VERSION "AgOpen Rate CAN ECU DBC with S0-S3 banks, 16 nodes, and service CAN"

NS_ :

BS_:

BU_: MASTER TOOL NODE1 NODE2 NODE3 NODE4 NODE5 NODE6 NODE7 NODE8 NODE9 NODE10 NODE11 NODE12 NODE13 NODE14 NODE15 NODE16

BO_ 972 S2_NODE_DIAG_12: 8 NODE12
 SG_ bus_voltage : 0|16@1+ (0.1,0) [0|6553.5] "V"  MASTER,NODE1,NODE2,NODE3,NODE4,NODE5,NODE6,NODE7,NODE8,NODE9,NODE10,NODE11,NODE12,NODE13,NODE14,NODE15,NODE16,TOOL
 SG_ motor_current : 16|16@1- (0.1,0) [-3276.8|3276.7] "A"  MASTER,NODE1,NODE2,NODE3,NODE4,NODE5,NODE6,NODE7,NODE8,NODE9,NODE10,NODE11,NODE12,NODE13,NODE14,NODE15,NODE16,TOOL
 SG_ controller_temp : 32|8@1- (1,0) [-128|127] "degC"  MASTER,NODE1,NODE2,NODE3,NODE4,NODE5,NODE6,NODE7,NODE8,NODE9,NODE10,NODE11,NODE12,NODE13,NODE14,NODE15,NODE16,TOOL
 SG_ motor_temp : 40|8@1- (1,0) [-128|127] "degC"  MASTER,NODE1,NODE2,NODE3,NODE4,NODE5,NODE6,NODE7,NODE8,NODE9,NODE10,NODE11,NODE12,NODE13,NODE14,NODE15,NODE16,TOOL
 SG_ fault_flags : 48|8@1+ (1,0) [0|255] "bitfield"  MASTER,NODE1,NODE2,NODE3,NODE4,NODE5,NODE6,NODE7,NODE8,NODE9,NODE10,NODE11,NODE12,NODE13,NODE14,NODE15,NODE16,TOOL
 SG_ warning_flags : 56|8@1+ (1,0) [0|255] "bitfield"  MASTER,NODE1,NODE2,NODE3,NODE4,NODE5,NODE6,NODE7,NODE8,NODE9,NODE10,NODE11,NODE12,NODE13,NODE14,NODE15,NODE16,TOOL

BO_ 797 S2_NODE_CMD_13: 8 MASTER
 SG_ node_command : 0|8@1+ (1,0) [0|255] ""  MASTER,NODE1,NODE2,NODE3,NODE4,NODE5,NODE6,NODE7,NODE8,NODE9,NODE10,NODE11,NODE12,NODE13,NODE14,NODE15,NODE16,TOOL
 SG_ node_flags : 8|8@1+ (1,0) [0|255] "bitfield"  MASTER,NODE1,NODE2,NODE3,NODE4,NODE5,NODE6,NODE7,NODE8,NODE9,NODE10,NODE11,NODE12,NODE13,NODE14,NODE15,NODE16,TOOL
 SG_ trim_rpm : 16|16@1- (0.1,0) [-3276.8|3276.7] "rpm"  MASTER,NODE1,NODE2,NODE3,NODE4,NODE5,NODE6,NODE7,NODE8,NODE9,NODE10,NODE11,NODE12,NODE13,NODE14,NODE15,NODE16,TOOL
 SG_ section_mask : 32|16@1+ (1,0) [0|65535] "bitmask"  MASTER,NODE1,NODE2,NODE3,NODE4,NODE5,NODE6,NODE7,NODE8,NODE9,NODE10,NODE11,NODE12,NODE13,NODE14,NODE15,NODE16,TOOL
 SG_ seq : 48|8@1+ (1,0) [0|255] ""  MASTER,NODE1,NODE2,NODE3,NODE4,NODE5,NODE6,NODE7,NODE8,NODE9,NODE10,NODE11,NODE12,NODE13,NODE14,NODE15,NODE16,TOOL
 SG_ reserved : 56|8@1+ (1,0) [0|255] ""  MASTER,NODE1,NODE2,NODE3,NODE4,NODE5,NODE6,NODE7,NODE8,NODE9,NODE10,NODE11,NODE12,NODE13,NODE14,NODE15,NODE16,TOOL

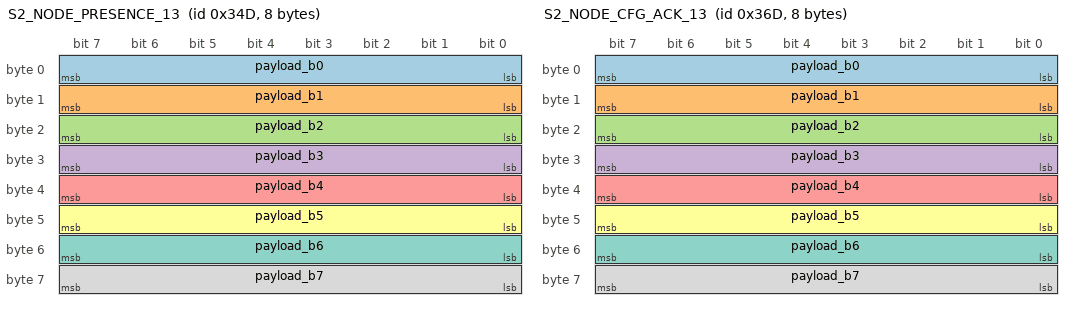
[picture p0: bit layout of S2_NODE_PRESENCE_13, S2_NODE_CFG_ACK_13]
BO_ 845 S2_NODE_PRESENCE_13: 8 NODE13
 SG_ payload_b0 : 0|8@1+ (1,0) [0|255] "raw"  MASTER,NODE1,NODE2,NODE3,NODE4,NODE5,NODE6,NODE7,NODE8,NODE9,NODE10,NODE11,NODE12,NODE13,NODE14,NODE15,NODE16,TOOL
 SG_ payload_b1 : 8|8@1+ (1,0) [0|255] "raw"  MASTER,NODE1,NODE2,NODE3,NODE4,NODE5,NODE6,NODE7,NODE8,NODE9,NODE10,NODE11,NODE12,NODE13,NODE14,NODE15,NODE16,TOOL
 SG_ payload_b2 : 16|8@1+ (1,0) [0|255] "raw"  MASTER,NODE1,NODE2,NODE3,NODE4,NODE5,NODE6,NODE7,NODE8,NODE9,NODE10,NODE11,NODE12,NODE13,NODE14,NODE15,NODE16,TOOL
 SG_ payload_b3 : 24|8@1+ (1,0) [0|255] "raw"  MASTER,NODE1,NODE2,NODE3,NODE4,NODE5,NODE6,NODE7,NODE8,NODE9,NODE10,NODE11,NODE12,NODE13,NODE14,NODE15,NODE16,TOOL
 SG_ payload_b4 : 32|8@1+ (1,0) [0|255] "raw"  MASTER,NODE1,NODE2,NODE3,NODE4,NODE5,NODE6,NODE7,NODE8,NODE9,NODE10,NODE11,NODE12,NODE13,NODE14,NODE15,NODE16,TOOL
 SG_ payload_b5 : 40|8@1+ (1,0) [0|255] "raw"  MASTER,NODE1,NODE2,NODE3,NODE4,NODE5,NODE6,NODE7,NODE8,NODE9,NODE10,NODE11,NODE12,NODE13,NODE14,NODE15,NODE16,TOOL
 SG_ payload_b6 : 48|8@1+ (1,0) [0|255] "raw"  MASTER,NODE1,NODE2,NODE3,NODE4,NODE5,NODE6,NODE7,NODE8,NODE9,NODE10,NODE11,NODE12,NODE13,NODE14,NODE15,NODE16,TOOL
 SG_ payload_b7 : 56|8@1+ (1,0) [0|255] "raw"  MASTER,NODE1,NODE2,NODE3,NODE4,NODE5,NODE6,NODE7,NODE8,NODE9,NODE10,NODE11,NODE12,NODE13,NODE14,NODE15,NODE16,TOOL

BO_ 877 S2_NODE_CFG_ACK_13: 8 NODE13
 SG_ payload_b0 : 0|8@1+ (1,0) [0|255] "raw"  MASTER,NODE1,NODE2,NODE3,NODE4,NODE5,NODE6,NODE7,NODE8,NODE9,NODE10,NODE11,NODE12,NODE13,NODE14,NODE15,NODE16,TOOL
 SG_ payload_b1 : 8|8@1+ (1,0) [0|255] "raw"  MASTER,NODE1,NODE2,NODE3,NODE4,NODE5,NODE6,NODE7,NODE8,NODE9,NODE10,NODE11,NODE12,NODE13,NODE14,NODE15,NODE16,TOOL
 SG_ payload_b2 : 16|8@1+ (1,0) [0|255] "raw"  MASTER,NODE1,NODE2,NODE3,NODE4,NODE5,NODE6,NODE7,NODE8,NODE9,NODE10,NODE11,NODE12,NODE13,NODE14,NODE15,NODE16,TOOL
 SG_ payload_b3 : 24|8@1+ (1,0) [0|255] "raw"  MASTER,NODE1,NODE2,NODE3,NODE4,NODE5,NODE6,NODE7,NODE8,NODE9,NODE10,NODE11,NODE12,NODE13,NODE14,NODE15,NODE16,TOOL
 SG_ payload_b4 : 32|8@1+ (1,0) [0|255] "raw"  MASTER,NODE1,NODE2,NODE3,NODE4,NODE5,NODE6,NODE7,NODE8,NODE9,NODE10,NODE11,NODE12,NODE13,NODE14,NODE15,NODE16,TOOL
 SG_ payload_b5 : 40|8@1+ (1,0) [0|255] "raw"  MASTER,NODE1,NODE2,NODE3,NODE4,NODE5,NODE6,NODE7,NODE8,NODE9,NODE10,NODE11,NODE12,NODE13,NODE14,NODE15,NODE16,TOOL
 SG_ payload_b6 : 48|8@1+ (1,0) [0|255] "raw"  MASTER,NODE1,NODE2,NODE3,NODE4,NODE5,NODE6,NODE7,NODE8,NODE9,NODE10,NODE11,NODE12,NODE13,NODE14,NODE15,NODE16,TOOL
 SG_ payload_b7 : 56|8@1+ (1,0) [0|255] "raw"  MASTER,NODE1,NODE2,NODE3,NODE4,NODE5,NODE6,NODE7,NODE8,NODE9,NODE10,NODE11,NODE12,NODE13,NODE14,NODE15,NODE16,TOOL

BO_ 909 S2_NODE_STATUS_FAST_13: 8 NODE13
 SG_ status_flags : 0|8@1+ (1,0) [0|255] "bitfield"  MASTER,NODE1,NODE2,NODE3,NODE4,NODE5,NODE6,NODE7,NODE8,NODE9,NODE10,NODE11,NODE12,NODE13,NODE14,NODE15,NODE16,TOOL
 SG_ error_code : 8|8@1+ (1,0) [0|255] ""  MASTER,NODE1,NODE2,NODE3,NODE4,NODE5,NODE6,NODE7,NODE8,NODE9,NODE10,NODE11,NODE12,NODE13,NODE14,NODE15,NODE16,TOOL
 SG_ actual_rpm : 16|16@1+ (1,0) [0|10000] "rpm"  MASTER,NODE1,NODE2,NODE3,NODE4,NODE5,NODE6,NODE7,NODE8,NODE9,NODE10,NODE11,NODE12,NODE13,NODE14,NODE15,NODE16,TOOL
 SG_ actual_pos : 32|16@1+ (1.52587890625e-05,0) [0|0.9999847412109375] "rev"  MASTER,NODE1,NODE2,NODE3,NODE4,NODE5,NODE6,NODE7,NODE8,NODE9,NODE10,NODE11,NODE12,NODE13,NODE14,NODE15,NODE16,TOOL
 SG_ alive_counter : 48|8@1+ (1,0) [0|255] ""  MASTER,NODE1,NODE2,NODE3,NODE4,NODE5,NODE6,NODE7,NODE8,NODE9,NODE10,NODE11,NODE12,NODE13,NODE14,NODE15,NODE16,TOOL
 SG_ sync_error : 56|8@1- (0.00390625,0) [-0.5|0.49609375] "rev"  MASTER,NODE1,NODE2,NODE3,NODE4,NODE5,NODE6,NODE7,NODE8,NODE9,NODE10,NODE11,NODE12,NODE13,NODE14,NODE15,NODE16,TOOL

BO_ 973 S2_NODE_DIAG_13: 8 NODE13
 SG_ bus_voltage : 0|16@1+ (0.1,0) [0|6553.5] "V"  MASTER,NODE1,NODE2,NODE3,NODE4,NODE5,NODE6,NODE7,NODE8,NODE9,NODE10,NODE11,NODE12,NODE13,NODE14,NODE15,NODE16,TOOL
 SG_ motor_current : 16|16@1- (0.1,0) [-3276.8|3276.7] "A"  MASTER,NODE1,NODE2,NODE3,NODE4,NODE5,NODE6,NODE7,NODE8,NODE9,NODE10,NODE11,NODE12,NODE13,NODE14,NODE15,NODE16,TOOL
 SG_ controller_temp : 32|8@1- (1,0) [-128|127] "degC"  MASTER,NODE1,NODE2,NODE3,NODE4,NODE5,NODE6,NODE7,NODE8,NODE9,NODE10,NODE11,NODE12,NODE13,NODE14,NODE15,NODE16,TOOL
 SG_ motor_temp : 40|8@1- (1,0) [-128|127] "degC"  MASTER,NODE1,NODE2,NODE3,NODE4,NODE5,NODE6,NODE7,NODE8,NODE9,NODE10,NODE11,NODE12,NODE13,NODE14,NODE15,NODE16,TOOL
 SG_ fault_flags : 48|8@1+ (1,0) [0|255] "bitfield"  MASTER,NODE1,NODE2,NODE3,NODE4,NODE5,NODE6,NODE7,NODE8,NODE9,NODE10,NODE11,NODE12,NODE13,NODE14,NODE15,NODE16,TOOL
 SG_ warning_flags : 56|8@1+ (1,0) [0|255] "bitfield"  MASTER,NODE1,NODE2,NODE3,NODE4,NODE5,NODE6,NODE7,NODE8,NODE9,NODE10,NODE11,NODE12,NODE13,NODE14,NODE15,NODE16,TOOL

BO_ 798 S2_NODE_CMD_14: 8 MASTER
 SG_ node_command : 0|8@1+ (1,0) [0|255] ""  MASTER,NODE1,NODE2,NODE3,NODE4,NODE5,NODE6,NODE7,NODE8,NODE9,NODE10,NODE11,NODE12,NODE13,NODE14,NODE15,NODE16,TOOL
 SG_ node_flags : 8|8@1+ (1,0) [0|255] "bitfield"  MASTER,NODE1,NODE2,NODE3,NODE4,NODE5,NODE6,NODE7,NODE8,NODE9,NODE10,NODE11,NODE12,NODE13,NODE14,NODE15,NODE16,TOOL
 SG_ trim_rpm : 16|16@1- (0.1,0) [-3276.8|3276.7] "rpm"  MASTER,NODE1,NODE2,NODE3,NODE4,NODE5,NODE6,NODE7,NODE8,NODE9,NODE10,NODE11,NODE12,NODE13,NODE14,NODE15,NODE16,TOOL
 SG_ section_mask : 32|16@1+ (1,0) [0|65535] "bitmask"  MASTER,NODE1,NODE2,NODE3,NODE4,NODE5,NODE6,NODE7,NODE8,NODE9,NODE10,NODE11,NODE12,NODE13,NODE14,NODE15,NODE16,TOOL
 SG_ seq : 48|8@1+ (1,0) [0|255] ""  MASTER,NODE1,NODE2,NODE3,NODE4,NODE5,NODE6,NODE7,NODE8,NODE9,NODE10,NODE11,NODE12,NODE13,NODE14,NODE15,NODE16,TOOL
 SG_ reserved : 56|8@1+ (1,0) [0|255] ""  MASTER,NODE1,NODE2,NODE3,NODE4,NODE5,NODE6,NODE7,NODE8,NODE9,NODE10,NODE11,NODE12,NODE13,NODE14,NODE15,NODE16,TOOL

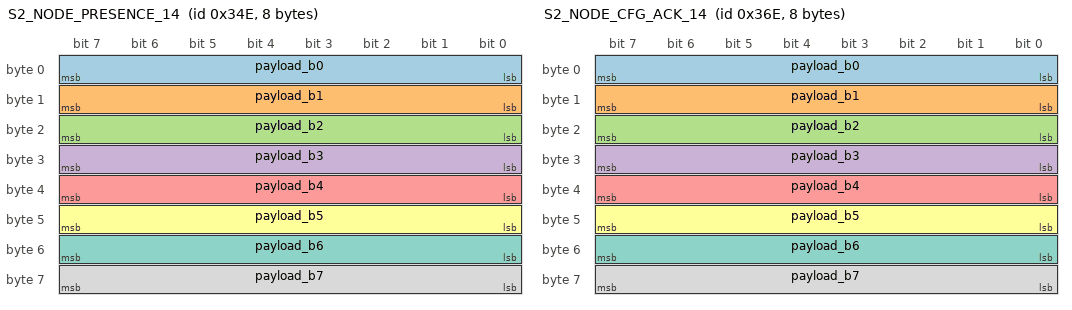
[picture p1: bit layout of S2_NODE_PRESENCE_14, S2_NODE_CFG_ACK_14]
BO_ 846 S2_NODE_PRESENCE_14: 8 NODE14
 SG_ payload_b0 : 0|8@1+ (1,0) [0|255] "raw"  MASTER,NODE1,NODE2,NODE3,NODE4,NODE5,NODE6,NODE7,NODE8,NODE9,NODE10,NODE11,NODE12,NODE13,NODE14,NODE15,NODE16,TOOL
 SG_ payload_b1 : 8|8@1+ (1,0) [0|255] "raw"  MASTER,NODE1,NODE2,NODE3,NODE4,NODE5,NODE6,NODE7,NODE8,NODE9,NODE10,NODE11,NODE12,NODE13,NODE14,NODE15,NODE16,TOOL
 SG_ payload_b2 : 16|8@1+ (1,0) [0|255] "raw"  MASTER,NODE1,NODE2,NODE3,NODE4,NODE5,NODE6,NODE7,NODE8,NODE9,NODE10,NODE11,NODE12,NODE13,NODE14,NODE15,NODE16,TOOL
 SG_ payload_b3 : 24|8@1+ (1,0) [0|255] "raw"  MASTER,NODE1,NODE2,NODE3,NODE4,NODE5,NODE6,NODE7,NODE8,NODE9,NODE10,NODE11,NODE12,NODE13,NODE14,NODE15,NODE16,TOOL
 SG_ payload_b4 : 32|8@1+ (1,0) [0|255] "raw"  MASTER,NODE1,NODE2,NODE3,NODE4,NODE5,NODE6,NODE7,NODE8,NODE9,NODE10,NODE11,NODE12,NODE13,NODE14,NODE15,NODE16,TOOL
 SG_ payload_b5 : 40|8@1+ (1,0) [0|255] "raw"  MASTER,NODE1,NODE2,NODE3,NODE4,NODE5,NODE6,NODE7,NODE8,NODE9,NODE10,NODE11,NODE12,NODE13,NODE14,NODE15,NODE16,TOOL
 SG_ payload_b6 : 48|8@1+ (1,0) [0|255] "raw"  MASTER,NODE1,NODE2,NODE3,NODE4,NODE5,NODE6,NODE7,NODE8,NODE9,NODE10,NODE11,NODE12,NODE13,NODE14,NODE15,NODE16,TOOL
 SG_ payload_b7 : 56|8@1+ (1,0) [0|255] "raw"  MASTER,NODE1,NODE2,NODE3,NODE4,NODE5,NODE6,NODE7,NODE8,NODE9,NODE10,NODE11,NODE12,NODE13,NODE14,NODE15,NODE16,TOOL

BO_ 878 S2_NODE_CFG_ACK_14: 8 NODE14
 SG_ payload_b0 : 0|8@1+ (1,0) [0|255] "raw"  MASTER,NODE1,NODE2,NODE3,NODE4,NODE5,NODE6,NODE7,NODE8,NODE9,NODE10,NODE11,NODE12,NODE13,NODE14,NODE15,NODE16,TOOL
 SG_ payload_b1 : 8|8@1+ (1,0) [0|255] "raw"  MASTER,NODE1,NODE2,NODE3,NODE4,NODE5,NODE6,NODE7,NODE8,NODE9,NODE10,NODE11,NODE12,NODE13,NODE14,NODE15,NODE16,TOOL
 SG_ payload_b2 : 16|8@1+ (1,0) [0|255] "raw"  MASTER,NODE1,NODE2,NODE3,NODE4,NODE5,NODE6,NODE7,NODE8,NODE9,NODE10,NODE11,NODE12,NODE13,NODE14,NODE15,NODE16,TOOL
 SG_ payload_b3 : 24|8@1+ (1,0) [0|255] "raw"  MASTER,NODE1,NODE2,NODE3,NODE4,NODE5,NODE6,NODE7,NODE8,NODE9,NODE10,NODE11,NODE12,NODE13,NODE14,NODE15,NODE16,TOOL
 SG_ payload_b4 : 32|8@1+ (1,0) [0|255] "raw"  MASTER,NODE1,NODE2,NODE3,NODE4,NODE5,NODE6,NODE7,NODE8,NODE9,NODE10,NODE11,NODE12,NODE13,NODE14,NODE15,NODE16,TOOL
 SG_ payload_b5 : 40|8@1+ (1,0) [0|255] "raw"  MASTER,NODE1,NODE2,NODE3,NODE4,NODE5,NODE6,NODE7,NODE8,NODE9,NODE10,NODE11,NODE12,NODE13,NODE14,NODE15,NODE16,TOOL
 SG_ payload_b6 : 48|8@1+ (1,0) [0|255] "raw"  MASTER,NODE1,NODE2,NODE3,NODE4,NODE5,NODE6,NODE7,NODE8,NODE9,NODE10,NODE11,NODE12,NODE13,NODE14,NODE15,NODE16,TOOL
 SG_ payload_b7 : 56|8@1+ (1,0) [0|255] "raw"  MASTER,NODE1,NODE2,NODE3,NODE4,NODE5,NODE6,NODE7,NODE8,NODE9,NODE10,NODE11,NODE12,NODE13,NODE14,NODE15,NODE16,TOOL

BO_ 910 S2_NODE_STATUS_FAST_14: 8 NODE14
 SG_ status_flags : 0|8@1+ (1,0) [0|255] "bitfield"  MASTER,NODE1,NODE2,NODE3,NODE4,NODE5,NODE6,NODE7,NODE8,NODE9,NODE10,NODE11,NODE12,NODE13,NODE14,NODE15,NODE16,TOOL
 SG_ error_code : 8|8@1+ (1,0) [0|255] ""  MASTER,NODE1,NODE2,NODE3,NODE4,NODE5,NODE6,NODE7,NODE8,NODE9,NODE10,NODE11,NODE12,NODE13,NODE14,NODE15,NODE16,TOOL
 SG_ actual_rpm : 16|16@1+ (1,0) [0|10000] "rpm"  MASTER,NODE1,NODE2,NODE3,NODE4,NODE5,NODE6,NODE7,NODE8,NODE9,NODE10,NODE11,NODE12,NODE13,NODE14,NODE15,NODE16,TOOL
 SG_ actual_pos : 32|16@1+ (1.52587890625e-05,0) [0|0.9999847412109375] "rev"  MASTER,NODE1,NODE2,NODE3,NODE4,NODE5,NODE6,NODE7,NODE8,NODE9,NODE10,NODE11,NODE12,NODE13,NODE14,NODE15,NODE16,TOOL
 SG_ alive_counter : 48|8@1+ (1,0) [0|255] ""  MASTER,NODE1,NODE2,NODE3,NODE4,NODE5,NODE6,NODE7,NODE8,NODE9,NODE10,NODE11,NODE12,NODE13,NODE14,NODE15,NODE16,TOOL
 SG_ sync_error : 56|8@1- (0.00390625,0) [-0.5|0.49609375] "rev"  MASTER,NODE1,NODE2,NODE3,NODE4,NODE5,NODE6,NODE7,NODE8,NODE9,NODE10,NODE11,NODE12,NODE13,NODE14,NODE15,NODE16,TOOL

BO_ 974 S2_NODE_DIAG_14: 8 NODE14
 SG_ bus_voltage : 0|16@1+ (0.1,0) [0|6553.5] "V"  MASTER,NODE1,NODE2,NODE3,NODE4,NODE5,NODE6,NODE7,NODE8,NODE9,NODE10,NODE11,NODE12,NODE13,NODE14,NODE15,NODE16,TOOL
 SG_ motor_current : 16|16@1- (0.1,0) [-3276.8|3276.7] "A"  MASTER,NODE1,NODE2,NODE3,NODE4,NODE5,NODE6,NODE7,NODE8,NODE9,NODE10,NODE11,NODE12,NODE13,NODE14,NODE15,NODE16,TOOL
 SG_ controller_temp : 32|8@1- (1,0) [-128|127] "degC"  MASTER,NODE1,NODE2,NODE3,NODE4,NODE5,NODE6,NODE7,NODE8,NODE9,NODE10,NODE11,NODE12,NODE13,NODE14,NODE15,NODE16,TOOL
 SG_ motor_temp : 40|8@1- (1,0) [-128|127] "degC"  MASTER,NODE1,NODE2,NODE3,NODE4,NODE5,NODE6,NODE7,NODE8,NODE9,NODE10,NODE11,NODE12,NODE13,NODE14,NODE15,NODE16,TOOL
 SG_ fault_flags : 48|8@1+ (1,0) [0|255] "bitfield"  MASTER,NODE1,NODE2,NODE3,NODE4,NODE5,NODE6,NODE7,NODE8,NODE9,NODE10,NODE11,NODE12,NODE13,NODE14,NODE15,NODE16,TOOL
 SG_ warning_flags : 56|8@1+ (1,0) [0|255] "bitfield"  MASTER,NODE1,NODE2,NODE3,NODE4,NODE5,NODE6,NODE7,NODE8,NODE9,NODE10,NODE11,NODE12,NODE13,NODE14,NODE15,NODE16,TOOL

BO_ 799 S2_NODE_CMD_15: 8 MASTER
 SG_ node_command : 0|8@1+ (1,0) [0|255] ""  MASTER,NODE1,NODE2,NODE3,NODE4,NODE5,NODE6,NODE7,NODE8,NODE9,NODE10,NODE11,NODE12,NODE13,NODE14,NODE15,NODE16,TOOL
 SG_ node_flags : 8|8@1+ (1,0) [0|255] "bitfield"  MASTER,NODE1,NODE2,NODE3,NODE4,NODE5,NODE6,NODE7,NODE8,NODE9,NODE10,NODE11,NODE12,NODE13,NODE14,NODE15,NODE16,TOOL
 SG_ trim_rpm : 16|16@1- (0.1,0) [-3276.8|3276.7] "rpm"  MASTER,NODE1,NODE2,NODE3,NODE4,NODE5,NODE6,NODE7,NODE8,NODE9,NODE10,NODE11,NODE12,NODE13,NODE14,NODE15,NODE16,TOOL
 SG_ section_mask : 32|16@1+ (1,0) [0|65535] "bitmask"  MASTER,NODE1,NODE2,NODE3,NODE4,NODE5,NODE6,NODE7,NODE8,NODE9,NODE10,NODE11,NODE12,NODE13,NODE14,NODE15,NODE16,TOOL
 SG_ seq : 48|8@1+ (1,0) [0|255] ""  MASTER,NODE1,NODE2,NODE3,NODE4,NODE5,NODE6,NODE7,NODE8,NODE9,NODE10,NODE11,NODE12,NODE13,NODE14,NODE15,NODE16,TOOL
 SG_ reserved : 56|8@1+ (1,0) [0|255] ""  MASTER,NODE1,NODE2,NODE3,NODE4,NODE5,NODE6,NODE7,NODE8,NODE9,NODE10,NODE11,NODE12,NODE13,NODE14,NODE15,NODE16,TOOL

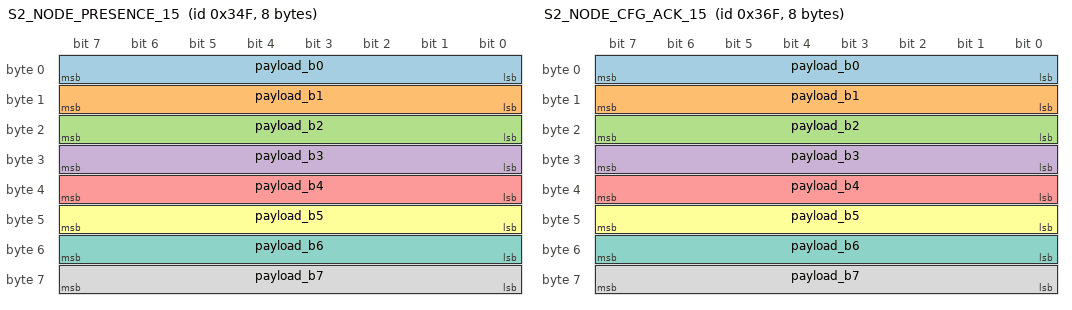
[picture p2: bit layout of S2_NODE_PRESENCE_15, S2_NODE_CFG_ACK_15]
BO_ 847 S2_NODE_PRESENCE_15: 8 NODE15
 SG_ payload_b0 : 0|8@1+ (1,0) [0|255] "raw"  MASTER,NODE1,NODE2,NODE3,NODE4,NODE5,NODE6,NODE7,NODE8,NODE9,NODE10,NODE11,NODE12,NODE13,NODE14,NODE15,NODE16,TOOL
 SG_ payload_b1 : 8|8@1+ (1,0) [0|255] "raw"  MASTER,NODE1,NODE2,NODE3,NODE4,NODE5,NODE6,NODE7,NODE8,NODE9,NODE10,NODE11,NODE12,NODE13,NODE14,NODE15,NODE16,TOOL
 SG_ payload_b2 : 16|8@1+ (1,0) [0|255] "raw"  MASTER,NODE1,NODE2,NODE3,NODE4,NODE5,NODE6,NODE7,NODE8,NODE9,NODE10,NODE11,NODE12,NODE13,NODE14,NODE15,NODE16,TOOL
 SG_ payload_b3 : 24|8@1+ (1,0) [0|255] "raw"  MASTER,NODE1,NODE2,NODE3,NODE4,NODE5,NODE6,NODE7,NODE8,NODE9,NODE10,NODE11,NODE12,NODE13,NODE14,NODE15,NODE16,TOOL
 SG_ payload_b4 : 32|8@1+ (1,0) [0|255] "raw"  MASTER,NODE1,NODE2,NODE3,NODE4,NODE5,NODE6,NODE7,NODE8,NODE9,NODE10,NODE11,NODE12,NODE13,NODE14,NODE15,NODE16,TOOL
 SG_ payload_b5 : 40|8@1+ (1,0) [0|255] "raw"  MASTER,NODE1,NODE2,NODE3,NODE4,NODE5,NODE6,NODE7,NODE8,NODE9,NODE10,NODE11,NODE12,NODE13,NODE14,NODE15,NODE16,TOOL
 SG_ payload_b6 : 48|8@1+ (1,0) [0|255] "raw"  MASTER,NODE1,NODE2,NODE3,NODE4,NODE5,NODE6,NODE7,NODE8,NODE9,NODE10,NODE11,NODE12,NODE13,NODE14,NODE15,NODE16,TOOL
 SG_ payload_b7 : 56|8@1+ (1,0) [0|255] "raw"  MASTER,NODE1,NODE2,NODE3,NODE4,NODE5,NODE6,NODE7,NODE8,NODE9,NODE10,NODE11,NODE12,NODE13,NODE14,NODE15,NODE16,TOOL

BO_ 879 S2_NODE_CFG_ACK_15: 8 NODE15
 SG_ payload_b0 : 0|8@1+ (1,0) [0|255] "raw"  MASTER,NODE1,NODE2,NODE3,NODE4,NODE5,NODE6,NODE7,NODE8,NODE9,NODE10,NODE11,NODE12,NODE13,NODE14,NODE15,NODE16,TOOL
 SG_ payload_b1 : 8|8@1+ (1,0) [0|255] "raw"  MASTER,NODE1,NODE2,NODE3,NODE4,NODE5,NODE6,NODE7,NODE8,NODE9,NODE10,NODE11,NODE12,NODE13,NODE14,NODE15,NODE16,TOOL
 SG_ payload_b2 : 16|8@1+ (1,0) [0|255] "raw"  MASTER,NODE1,NODE2,NODE3,NODE4,NODE5,NODE6,NODE7,NODE8,NODE9,NODE10,NODE11,NODE12,NODE13,NODE14,NODE15,NODE16,TOOL
 SG_ payload_b3 : 24|8@1+ (1,0) [0|255] "raw"  MASTER,NODE1,NODE2,NODE3,NODE4,NODE5,NODE6,NODE7,NODE8,NODE9,NODE10,NODE11,NODE12,NODE13,NODE14,NODE15,NODE16,TOOL
 SG_ payload_b4 : 32|8@1+ (1,0) [0|255] "raw"  MASTER,NODE1,NODE2,NODE3,NODE4,NODE5,NODE6,NODE7,NODE8,NODE9,NODE10,NODE11,NODE12,NODE13,NODE14,NODE15,NODE16,TOOL
 SG_ payload_b5 : 40|8@1+ (1,0) [0|255] "raw"  MASTER,NODE1,NODE2,NODE3,NODE4,NODE5,NODE6,NODE7,NODE8,NODE9,NODE10,NODE11,NODE12,NODE13,NODE14,NODE15,NODE16,TOOL
 SG_ payload_b6 : 48|8@1+ (1,0) [0|255] "raw"  MASTER,NODE1,NODE2,NODE3,NODE4,NODE5,NODE6,NODE7,NODE8,NODE9,NODE10,NODE11,NODE12,NODE13,NODE14,NODE15,NODE16,TOOL
 SG_ payload_b7 : 56|8@1+ (1,0) [0|255] "raw"  MASTER,NODE1,NODE2,NODE3,NODE4,NODE5,NODE6,NODE7,NODE8,NODE9,NODE10,NODE11,NODE12,NODE13,NODE14,NODE15,NODE16,TOOL

BO_ 911 S2_NODE_STATUS_FAST_15: 8 NODE15
 SG_ status_flags : 0|8@1+ (1,0) [0|255] "bitfield"  MASTER,NODE1,NODE2,NODE3,NODE4,NODE5,NODE6,NODE7,NODE8,NODE9,NODE10,NODE11,NODE12,NODE13,NODE14,NODE15,NODE16,TOOL
 SG_ error_code : 8|8@1+ (1,0) [0|255] ""  MASTER,NODE1,NODE2,NODE3,NODE4,NODE5,NODE6,NODE7,NODE8,NODE9,NODE10,NODE11,NODE12,NODE13,NODE14,NODE15,NODE16,TOOL
 SG_ actual_rpm : 16|16@1+ (1,0) [0|10000] "rpm"  MASTER,NODE1,NODE2,NODE3,NODE4,NODE5,NODE6,NODE7,NODE8,NODE9,NODE10,NODE11,NODE12,NODE13,NODE14,NODE15,NODE16,TOOL
 SG_ actual_pos : 32|16@1+ (1.52587890625e-05,0) [0|0.9999847412109375] "rev"  MASTER,NODE1,NODE2,NODE3,NODE4,NODE5,NODE6,NODE7,NODE8,NODE9,NODE10,NODE11,NODE12,NODE13,NODE14,NODE15,NODE16,TOOL
 SG_ alive_counter : 48|8@1+ (1,0) [0|255] ""  MASTER,NODE1,NODE2,NODE3,NODE4,NODE5,NODE6,NODE7,NODE8,NODE9,NODE10,NODE11,NODE12,NODE13,NODE14,NODE15,NODE16,TOOL
 SG_ sync_error : 56|8@1- (0.00390625,0) [-0.5|0.49609375] "rev"  MASTER,NODE1,NODE2,NODE3,NODE4,NODE5,NODE6,NODE7,NODE8,NODE9,NODE10,NODE11,NODE12,NODE13,NODE14,NODE15,NODE16,TOOL

BO_ 975 S2_NODE_DIAG_15: 8 NODE15
 SG_ bus_voltage : 0|16@1+ (0.1,0) [0|6553.5] "V"  MASTER,NODE1,NODE2,NODE3,NODE4,NODE5,NODE6,NODE7,NODE8,NODE9,NODE10,NODE11,NODE12,NODE13,NODE14,NODE15,NODE16,TOOL
 SG_ motor_current : 16|16@1- (0.1,0) [-3276.8|3276.7] "A"  MASTER,NODE1,NODE2,NODE3,NODE4,NODE5,NODE6,NODE7,NODE8,NODE9,NODE10,NODE11,NODE12,NODE13,NODE14,NODE15,NODE16,TOOL
 SG_ controller_temp : 32|8@1- (1,0) [-128|127] "degC"  MASTER,NODE1,NODE2,NODE3,NODE4,NODE5,NODE6,NODE7,NODE8,NODE9,NODE10,NODE11,NODE12,NODE13,NODE14,NODE15,NODE16,TOOL
 SG_ motor_temp : 40|8@1- (1,0) [-128|127] "degC"  MASTER,NODE1,NODE2,NODE3,NODE4,NODE5,NODE6,NODE7,NODE8,NODE9,NODE10,NODE11,NODE12,NODE13,NODE14,NODE15,NODE16,TOOL
 SG_ fault_flags : 48|8@1+ (1,0) [0|255] "bitfield"  MASTER,NODE1,NODE2,NODE3,NODE4,NODE5,NODE6,NODE7,NODE8,NODE9,NODE10,NODE11,NODE12,NODE13,NODE14,NODE15,NODE16,TOOL
 SG_ warning_flags : 56|8@1+ (1,0) [0|255] "bitfield"  MASTER,NODE1,NODE2,NODE3,NODE4,NODE5,NODE6,NODE7,NODE8,NODE9,NODE10,NODE11,NODE12,NODE13,NODE14,NODE15,NODE16,TOOL

BO_ 800 S2_NODE_CMD_16: 8 MASTER
 SG_ node_command : 0|8@1+ (1,0) [0|255] ""  MASTER,NODE1,NODE2,NODE3,NODE4,NODE5,NODE6,NODE7,NODE8,NODE9,NODE10,NODE11,NODE12,NODE13,NODE14,NODE15,NODE16,TOOL
 SG_ node_flags : 8|8@1+ (1,0) [0|255] "bitfield"  MASTER,NODE1,NODE2,NODE3,NODE4,NODE5,NODE6,NODE7,NODE8,NODE9,NODE10,NODE11,NODE12,NODE13,NODE14,NODE15,NODE16,TOOL
 SG_ trim_rpm : 16|16@1- (0.1,0) [-3276.8|3276.7] "rpm"  MASTER,NODE1,NODE2,NODE3,NODE4,NODE5,NODE6,NODE7,NODE8,NODE9,NODE10,NODE11,NODE12,NODE13,NODE14,NODE15,NODE16,TOOL
 SG_ section_mask : 32|16@1+ (1,0) [0|65535] "bitmask"  MASTER,NODE1,NODE2,NODE3,NODE4,NODE5,NODE6,NODE7,NODE8,NODE9,NODE10,NODE11,NODE12,NODE13,NODE14,NODE15,NODE16,TOOL
 SG_ seq : 48|8@1+ (1,0) [0|255] ""  MASTER,NODE1,NODE2,NODE3,NODE4,NODE5,NODE6,NODE7,NODE8,NODE9,NODE10,NODE11,NODE12,NODE13,NODE14,NODE15,NODE16,TOOL
 SG_ reserved : 56|8@1+ (1,0) [0|255] ""  MASTER,NODE1,NODE2,NODE3,NODE4,NODE5,NODE6,NODE7,NODE8,NODE9,NODE10,NODE11,NODE12,NODE13,NODE14,NODE15,NODE16,TOOL

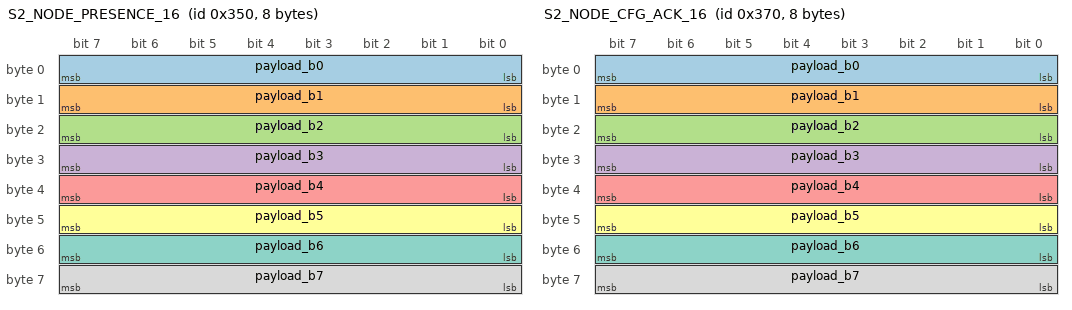
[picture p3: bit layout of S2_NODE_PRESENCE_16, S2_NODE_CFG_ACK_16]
BO_ 848 S2_NODE_PRESENCE_16: 8 NODE16
 SG_ payload_b0 : 0|8@1+ (1,0) [0|255] "raw"  MASTER,NODE1,NODE2,NODE3,NODE4,NODE5,NODE6,NODE7,NODE8,NODE9,NODE10,NODE11,NODE12,NODE13,NODE14,NODE15,NODE16,TOOL
 SG_ payload_b1 : 8|8@1+ (1,0) [0|255] "raw"  MASTER,NODE1,NODE2,NODE3,NODE4,NODE5,NODE6,NODE7,NODE8,NODE9,NODE10,NODE11,NODE12,NODE13,NODE14,NODE15,NODE16,TOOL
 SG_ payload_b2 : 16|8@1+ (1,0) [0|255] "raw"  MASTER,NODE1,NODE2,NODE3,NODE4,NODE5,NODE6,NODE7,NODE8,NODE9,NODE10,NODE11,NODE12,NODE13,NODE14,NODE15,NODE16,TOOL
 SG_ payload_b3 : 24|8@1+ (1,0) [0|255] "raw"  MASTER,NODE1,NODE2,NODE3,NODE4,NODE5,NODE6,NODE7,NODE8,NODE9,NODE10,NODE11,NODE12,NODE13,NODE14,NODE15,NODE16,TOOL
 SG_ payload_b4 : 32|8@1+ (1,0) [0|255] "raw"  MASTER,NODE1,NODE2,NODE3,NODE4,NODE5,NODE6,NODE7,NODE8,NODE9,NODE10,NODE11,NODE12,NODE13,NODE14,NODE15,NODE16,TOOL
 SG_ payload_b5 : 40|8@1+ (1,0) [0|255] "raw"  MASTER,NODE1,NODE2,NODE3,NODE4,NODE5,NODE6,NODE7,NODE8,NODE9,NODE10,NODE11,NODE12,NODE13,NODE14,NODE15,NODE16,TOOL
 SG_ payload_b6 : 48|8@1+ (1,0) [0|255] "raw"  MASTER,NODE1,NODE2,NODE3,NODE4,NODE5,NODE6,NODE7,NODE8,NODE9,NODE10,NODE11,NODE12,NODE13,NODE14,NODE15,NODE16,TOOL
 SG_ payload_b7 : 56|8@1+ (1,0) [0|255] "raw"  MASTER,NODE1,NODE2,NODE3,NODE4,NODE5,NODE6,NODE7,NODE8,NODE9,NODE10,NODE11,NODE12,NODE13,NODE14,NODE15,NODE16,TOOL

BO_ 880 S2_NODE_CFG_ACK_16: 8 NODE16
 SG_ payload_b0 : 0|8@1+ (1,0) [0|255] "raw"  MASTER,NODE1,NODE2,NODE3,NODE4,NODE5,NODE6,NODE7,NODE8,NODE9,NODE10,NODE11,NODE12,NODE13,NODE14,NODE15,NODE16,TOOL
 SG_ payload_b1 : 8|8@1+ (1,0) [0|255] "raw"  MASTER,NODE1,NODE2,NODE3,NODE4,NODE5,NODE6,NODE7,NODE8,NODE9,NODE10,NODE11,NODE12,NODE13,NODE14,NODE15,NODE16,TOOL
 SG_ payload_b2 : 16|8@1+ (1,0) [0|255] "raw"  MASTER,NODE1,NODE2,NODE3,NODE4,NODE5,NODE6,NODE7,NODE8,NODE9,NODE10,NODE11,NODE12,NODE13,NODE14,NODE15,NODE16,TOOL
 SG_ payload_b3 : 24|8@1+ (1,0) [0|255] "raw"  MASTER,NODE1,NODE2,NODE3,NODE4,NODE5,NODE6,NODE7,NODE8,NODE9,NODE10,NODE11,NODE12,NODE13,NODE14,NODE15,NODE16,TOOL
 SG_ payload_b4 : 32|8@1+ (1,0) [0|255] "raw"  MASTER,NODE1,NODE2,NODE3,NODE4,NODE5,NODE6,NODE7,NODE8,NODE9,NODE10,NODE11,NODE12,NODE13,NODE14,NODE15,NODE16,TOOL
 SG_ payload_b5 : 40|8@1+ (1,0) [0|255] "raw"  MASTER,NODE1,NODE2,NODE3,NODE4,NODE5,NODE6,NODE7,NODE8,NODE9,NODE10,NODE11,NODE12,NODE13,NODE14,NODE15,NODE16,TOOL
 SG_ payload_b6 : 48|8@1+ (1,0) [0|255] "raw"  MASTER,NODE1,NODE2,NODE3,NODE4,NODE5,NODE6,NODE7,NODE8,NODE9,NODE10,NODE11,NODE12,NODE13,NODE14,NODE15,NODE16,TOOL
 SG_ payload_b7 : 56|8@1+ (1,0) [0|255] "raw"  MASTER,NODE1,NODE2,NODE3,NODE4,NODE5,NODE6,NODE7,NODE8,NODE9,NODE10,NODE11,NODE12,NODE13,NODE14,NODE15,NODE16,TOOL

BO_ 912 S2_NODE_STATUS_FAST_16: 8 NODE16
 SG_ status_flags : 0|8@1+ (1,0) [0|255] "bitfield"  MASTER,NODE1,NODE2,NODE3,NODE4,NODE5,NODE6,NODE7,NODE8,NODE9,NODE10,NODE11,NODE12,NODE13,NODE14,NODE15,NODE16,TOOL
 SG_ error_code : 8|8@1+ (1,0) [0|255] ""  MASTER,NODE1,NODE2,NODE3,NODE4,NODE5,NODE6,NODE7,NODE8,NODE9,NODE10,NODE11,NODE12,NODE13,NODE14,NODE15,NODE16,TOOL
 SG_ actual_rpm : 16|16@1+ (1,0) [0|10000] "rpm"  MASTER,NODE1,NODE2,NODE3,NODE4,NODE5,NODE6,NODE7,NODE8,NODE9,NODE10,NODE11,NODE12,NODE13,NODE14,NODE15,NODE16,TOOL
 SG_ actual_pos : 32|16@1+ (1.52587890625e-05,0) [0|0.9999847412109375] "rev"  MASTER,NODE1,NODE2,NODE3,NODE4,NODE5,NODE6,NODE7,NODE8,NODE9,NODE10,NODE11,NODE12,NODE13,NODE14,NODE15,NODE16,TOOL
 SG_ alive_counter : 48|8@1+ (1,0) [0|255] ""  MASTER,NODE1,NODE2,NODE3,NODE4,NODE5,NODE6,NODE7,NODE8,NODE9,NODE10,NODE11,NODE12,NODE13,NODE14,NODE15,NODE16,TOOL
 SG_ sync_error : 56|8@1- (0.00390625,0) [-0.5|0.49609375] "rev"  MASTER,NODE1,NODE2,NODE3,NODE4,NODE5,NODE6,NODE7,NODE8,NODE9,NODE10,NODE11,NODE12,NODE13,NODE14,NODE15,NODE16,TOOL

BO_ 976 S2_NODE_DIAG_16: 8 NODE16
 SG_ bus_voltage : 0|16@1+ (0.1,0) [0|6553.5] "V"  MASTER,NODE1,NODE2,NODE3,NODE4,NODE5,NODE6,NODE7,NODE8,NODE9,NODE10,NODE11,NODE12,NODE13,NODE14,NODE15,NODE16,TOOL
 SG_ motor_current : 16|16@1- (0.1,0) [-3276.8|3276.7] "A"  MASTER,NODE1,NODE2,NODE3,NODE4,NODE5,NODE6,NODE7,NODE8,NODE9,NODE10,NODE11,NODE12,NODE13,NODE14,NODE15,NODE16,TOOL
 SG_ controller_temp : 32|8@1- (1,0) [-128|127] "degC"  MASTER,NODE1,NODE2,NODE3,NODE4,NODE5,NODE6,NODE7,NODE8,NODE9,NODE10,NODE11,NODE12,NODE13,NODE14,NODE15,NODE16,TOOL
 SG_ motor_temp : 40|8@1- (1,0) [-128|127] "degC"  MASTER,NODE1,NODE2,NODE3,NODE4,NODE5,NODE6,NODE7,NODE8,NODE9,NODE10,NODE11,NODE12,NODE13,NODE14,NODE15,NODE16,TOOL
 SG_ fault_flags : 48|8@1+ (1,0) [0|255] "bitfield"  MASTER,NODE1,NODE2,NODE3,NODE4,NODE5,NODE6,NODE7,NODE8,NODE9,NODE10,NODE11,NODE12,NODE13,NODE14,NODE15,NODE16,TOOL
 SG_ warning_flags : 56|8@1+ (1,0) [0|255] "bitfield"  MASTER,NODE1,NODE2,NODE3,NODE4,NODE5,NODE6,NODE7,NODE8,NODE9,NODE10,NODE11,NODE12,NODE13,NODE14,NODE15,NODE16,TOOL

BO_ 1024 S3_GLOBAL_CONTROL: 8 MASTER
 SG_ system_mode : 0|8@1+ (1,0) [0|255] ""  MASTER,NODE1,NODE2,NODE3,NODE4,NODE5,NODE6,NODE7,NODE8,NODE9,NODE10,NODE11,NODE12,NODE13,NODE14,NODE15,NODE16,TOOL
 SG_ control_flags : 8|8@1+ (1,0) [0|255] "bitfield"  MASTER,NODE1,NODE2,NODE3,NODE4,NODE5,NODE6,NODE7,NODE8,NODE9,NODE10,NODE11,NODE12,NODE13,NODE14,NODE15,NODE16,TOOL
 SG_ ctrl_drive_enable : 8|1@1+ (1,0) [0|1] "bool"  MASTER,NODE1,NODE2,NODE3,NODE4,NODE5,NODE6,NODE7,NODE8,NODE9,NODE10,NODE11,NODE12,NODE13,NODE14,NODE15,NODE16,TOOL
 SG_ ctrl_sync_enable : 9|1@1+ (1,0) [0|1] "bool"  MASTER,NODE1,NODE2,NODE3,NODE4,NODE5,NODE6,NODE7,NODE8,NODE9,NODE10,NODE11,NODE12,NODE13,NODE14,NODE15,NODE16,TOOL
 SG_ ctrl_estop : 10|1@1+ (1,0) [0|1] "bool"  MASTER,NODE1,NODE2,NODE3,NODE4,NODE5,NODE6,NODE7,NODE8,NODE9,NODE10,NODE11,NODE12,NODE13,NODE14,NODE15,NODE16,TOOL
 SG_ ctrl_diag_enable : 11|1@1+ (1,0) [0|1] "bool"  MASTER,NODE1,NODE2,NODE3,NODE4,NODE5,NODE6,NODE7,NODE8,NODE9,NODE10,NODE11,NODE12,NODE13,NODE14,NODE15,NODE16,TOOL
 SG_ base_rpm : 16|16@1+ (1,0) [0|10000] "rpm"  MASTER,NODE1,NODE2,NODE3,NODE4,NODE5,NODE6,NODE7,NODE8,NODE9,NODE10,NODE11,NODE12,NODE13,NODE14,NODE15,NODE16,TOOL
 SG_ sync_pos : 32|16@1+ (1.52587890625e-05,0) [0|0.9999847412109375] "rev"  MASTER,NODE1,NODE2,NODE3,NODE4,NODE5,NODE6,NODE7,NODE8,NODE9,NODE10,NODE11,NODE12,NODE13,NODE14,NODE15,NODE16,TOOL
 SG_ sequence : 48|8@1+ (1,0) [0|255] ""  MASTER,NODE1,NODE2,NODE3,NODE4,NODE5,NODE6,NODE7,NODE8,NODE9,NODE10,NODE11,NODE12,NODE13,NODE14,NODE15,NODE16,TOOL
 SG_ reserved : 56|8@1+ (1,0) [0|255] ""  MASTER,NODE1,NODE2,NODE3,NODE4,NODE5,NODE6,NODE7,NODE8,NODE9,NODE10,NODE11,NODE12,NODE13,NODE14,NODE15,NODE16,TOOL

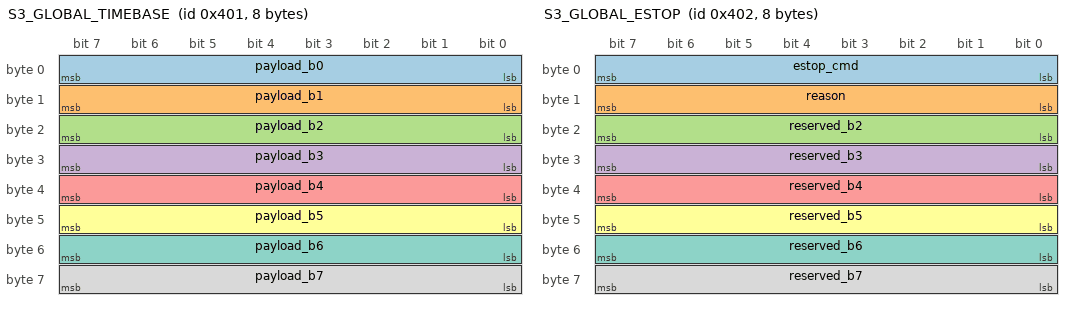
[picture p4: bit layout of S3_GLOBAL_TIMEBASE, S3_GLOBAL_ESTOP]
BO_ 1025 S3_GLOBAL_TIMEBASE: 8 MASTER
 SG_ payload_b0 : 0|8@1+ (1,0) [0|255] "raw"  MASTER,NODE1,NODE2,NODE3,NODE4,NODE5,NODE6,NODE7,NODE8,NODE9,NODE10,NODE11,NODE12,NODE13,NODE14,NODE15,NODE16,TOOL
 SG_ payload_b1 : 8|8@1+ (1,0) [0|255] "raw"  MASTER,NODE1,NODE2,NODE3,NODE4,NODE5,NODE6,NODE7,NODE8,NODE9,NODE10,NODE11,NODE12,NODE13,NODE14,NODE15,NODE16,TOOL
 SG_ payload_b2 : 16|8@1+ (1,0) [0|255] "raw"  MASTER,NODE1,NODE2,NODE3,NODE4,NODE5,NODE6,NODE7,NODE8,NODE9,NODE10,NODE11,NODE12,NODE13,NODE14,NODE15,NODE16,TOOL
 SG_ payload_b3 : 24|8@1+ (1,0) [0|255] "raw"  MASTER,NODE1,NODE2,NODE3,NODE4,NODE5,NODE6,NODE7,NODE8,NODE9,NODE10,NODE11,NODE12,NODE13,NODE14,NODE15,NODE16,TOOL
 SG_ payload_b4 : 32|8@1+ (1,0) [0|255] "raw"  MASTER,NODE1,NODE2,NODE3,NODE4,NODE5,NODE6,NODE7,NODE8,NODE9,NODE10,NODE11,NODE12,NODE13,NODE14,NODE15,NODE16,TOOL
 SG_ payload_b5 : 40|8@1+ (1,0) [0|255] "raw"  MASTER,NODE1,NODE2,NODE3,NODE4,NODE5,NODE6,NODE7,NODE8,NODE9,NODE10,NODE11,NODE12,NODE13,NODE14,NODE15,NODE16,TOOL
 SG_ payload_b6 : 48|8@1+ (1,0) [0|255] "raw"  MASTER,NODE1,NODE2,NODE3,NODE4,NODE5,NODE6,NODE7,NODE8,NODE9,NODE10,NODE11,NODE12,NODE13,NODE14,NODE15,NODE16,TOOL
 SG_ payload_b7 : 56|8@1+ (1,0) [0|255] "raw"  MASTER,NODE1,NODE2,NODE3,NODE4,NODE5,NODE6,NODE7,NODE8,NODE9,NODE10,NODE11,NODE12,NODE13,NODE14,NODE15,NODE16,TOOL

BO_ 1026 S3_GLOBAL_ESTOP: 8 MASTER
 SG_ estop_cmd : 0|8@1+ (1,0) [0|255] ""  MASTER,NODE1,NODE2,NODE3,NODE4,NODE5,NODE6,NODE7,NODE8,NODE9,NODE10,NODE11,NODE12,NODE13,NODE14,NODE15,NODE16,TOOL
 SG_ reason : 8|8@1+ (1,0) [0|255] ""  MASTER,NODE1,NODE2,NODE3,NODE4,NODE5,NODE6,NODE7,NODE8,NODE9,NODE10,NODE11,NODE12,NODE13,NODE14,NODE15,NODE16,TOOL
 SG_ reserved_b2 : 16|8@1+ (1,0) [0|255] ""  MASTER,NODE1,NODE2,NODE3,NODE4,NODE5,NODE6,NODE7,NODE8,NODE9,NODE10,NODE11,NODE12,NODE13,NODE14,NODE15,NODE16,TOOL
 SG_ reserved_b3 : 24|8@1+ (1,0) [0|255] ""  MASTER,NODE1,NODE2,NODE3,NODE4,NODE5,NODE6,NODE7,NODE8,NODE9,NODE10,NODE11,NODE12,NODE13,NODE14,NODE15,NODE16,TOOL
 SG_ reserved_b4 : 32|8@1+ (1,0) [0|255] ""  MASTER,NODE1,NODE2,NODE3,NODE4,NODE5,NODE6,NODE7,NODE8,NODE9,NODE10,NODE11,NODE12,NODE13,NODE14,NODE15,NODE16,TOOL
 SG_ reserved_b5 : 40|8@1+ (1,0) [0|255] ""  MASTER,NODE1,NODE2,NODE3,NODE4,NODE5,NODE6,NODE7,NODE8,NODE9,NODE10,NODE11,NODE12,NODE13,NODE14,NODE15,NODE16,TOOL
 SG_ reserved_b6 : 48|8@1+ (1,0) [0|255] ""  MASTER,NODE1,NODE2,NODE3,NODE4,NODE5,NODE6,NODE7,NODE8,NODE9,NODE10,NODE11,NODE12,NODE13,NODE14,NODE15,NODE16,TOOL
 SG_ reserved_b7 : 56|8@1+ (1,0) [0|255] ""  MASTER,NODE1,NODE2,NODE3,NODE4,NODE5,NODE6,NODE7,NODE8,NODE9,NODE10,NODE11,NODE12,NODE13,NODE14,NODE15,NODE16,TOOL

BO_ 1041 S3_NODE_CMD_1: 8 MASTER
 SG_ node_command : 0|8@1+ (1,0) [0|255] ""  MASTER,NODE1,NODE2,NODE3,NODE4,NODE5,NODE6,NODE7,NODE8,NODE9,NODE10,NODE11,NODE12,NODE13,NODE14,NODE15,NODE16,TOOL
 SG_ node_flags : 8|8@1+ (1,0) [0|255] "bitfield"  MASTER,NODE1,NODE2,NODE3,NODE4,NODE5,NODE6,NODE7,NODE8,NODE9,NODE10,NODE11,NODE12,NODE13,NODE14,NODE15,NODE16,TOOL
 SG_ trim_rpm : 16|16@1- (0.1,0) [-3276.8|3276.7] "rpm"  MASTER,NODE1,NODE2,NODE3,NODE4,NODE5,NODE6,NODE7,NODE8,NODE9,NODE10,NODE11,NODE12,NODE13,NODE14,NODE15,NODE16,TOOL
 SG_ section_mask : 32|16@1+ (1,0) [0|65535] "bitmask"  MASTER,NODE1,NODE2,NODE3,NODE4,NODE5,NODE6,NODE7,NODE8,NODE9,NODE10,NODE11,NODE12,NODE13,NODE14,NODE15,NODE16,TOOL
 SG_ seq : 48|8@1+ (1,0) [0|255] ""  MASTER,NODE1,NODE2,NODE3,NODE4,NODE5,NODE6,NODE7,NODE8,NODE9,NODE10,NODE11,NODE12,NODE13,NODE14,NODE15,NODE16,TOOL
 SG_ reserved : 56|8@1+ (1,0) [0|255] ""  MASTER,NODE1,NODE2,NODE3,NODE4,NODE5,NODE6,NODE7,NODE8,NODE9,NODE10,NODE11,NODE12,NODE13,NODE14,NODE15,NODE16,TOOL

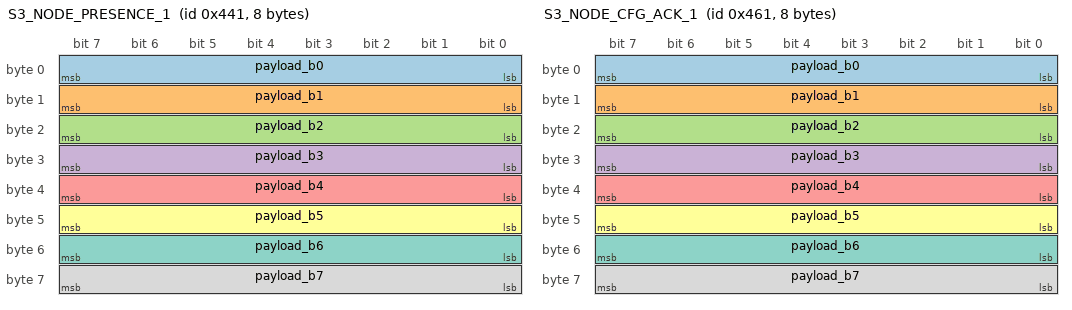
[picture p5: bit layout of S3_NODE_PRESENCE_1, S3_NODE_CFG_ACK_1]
BO_ 1089 S3_NODE_PRESENCE_1: 8 NODE1
 SG_ payload_b0 : 0|8@1+ (1,0) [0|255] "raw"  MASTER,NODE1,NODE2,NODE3,NODE4,NODE5,NODE6,NODE7,NODE8,NODE9,NODE10,NODE11,NODE12,NODE13,NODE14,NODE15,NODE16,TOOL
 SG_ payload_b1 : 8|8@1+ (1,0) [0|255] "raw"  MASTER,NODE1,NODE2,NODE3,NODE4,NODE5,NODE6,NODE7,NODE8,NODE9,NODE10,NODE11,NODE12,NODE13,NODE14,NODE15,NODE16,TOOL
 SG_ payload_b2 : 16|8@1+ (1,0) [0|255] "raw"  MASTER,NODE1,NODE2,NODE3,NODE4,NODE5,NODE6,NODE7,NODE8,NODE9,NODE10,NODE11,NODE12,NODE13,NODE14,NODE15,NODE16,TOOL
 SG_ payload_b3 : 24|8@1+ (1,0) [0|255] "raw"  MASTER,NODE1,NODE2,NODE3,NODE4,NODE5,NODE6,NODE7,NODE8,NODE9,NODE10,NODE11,NODE12,NODE13,NODE14,NODE15,NODE16,TOOL
 SG_ payload_b4 : 32|8@1+ (1,0) [0|255] "raw"  MASTER,NODE1,NODE2,NODE3,NODE4,NODE5,NODE6,NODE7,NODE8,NODE9,NODE10,NODE11,NODE12,NODE13,NODE14,NODE15,NODE16,TOOL
 SG_ payload_b5 : 40|8@1+ (1,0) [0|255] "raw"  MASTER,NODE1,NODE2,NODE3,NODE4,NODE5,NODE6,NODE7,NODE8,NODE9,NODE10,NODE11,NODE12,NODE13,NODE14,NODE15,NODE16,TOOL
 SG_ payload_b6 : 48|8@1+ (1,0) [0|255] "raw"  MASTER,NODE1,NODE2,NODE3,NODE4,NODE5,NODE6,NODE7,NODE8,NODE9,NODE10,NODE11,NODE12,NODE13,NODE14,NODE15,NODE16,TOOL
 SG_ payload_b7 : 56|8@1+ (1,0) [0|255] "raw"  MASTER,NODE1,NODE2,NODE3,NODE4,NODE5,NODE6,NODE7,NODE8,NODE9,NODE10,NODE11,NODE12,NODE13,NODE14,NODE15,NODE16,TOOL

BO_ 1121 S3_NODE_CFG_ACK_1: 8 NODE1
 SG_ payload_b0 : 0|8@1+ (1,0) [0|255] "raw"  MASTER,NODE1,NODE2,NODE3,NODE4,NODE5,NODE6,NODE7,NODE8,NODE9,NODE10,NODE11,NODE12,NODE13,NODE14,NODE15,NODE16,TOOL
 SG_ payload_b1 : 8|8@1+ (1,0) [0|255] "raw"  MASTER,NODE1,NODE2,NODE3,NODE4,NODE5,NODE6,NODE7,NODE8,NODE9,NODE10,NODE11,NODE12,NODE13,NODE14,NODE15,NODE16,TOOL
 SG_ payload_b2 : 16|8@1+ (1,0) [0|255] "raw"  MASTER,NODE1,NODE2,NODE3,NODE4,NODE5,NODE6,NODE7,NODE8,NODE9,NODE10,NODE11,NODE12,NODE13,NODE14,NODE15,NODE16,TOOL
 SG_ payload_b3 : 24|8@1+ (1,0) [0|255] "raw"  MASTER,NODE1,NODE2,NODE3,NODE4,NODE5,NODE6,NODE7,NODE8,NODE9,NODE10,NODE11,NODE12,NODE13,NODE14,NODE15,NODE16,TOOL
 SG_ payload_b4 : 32|8@1+ (1,0) [0|255] "raw"  MASTER,NODE1,NODE2,NODE3,NODE4,NODE5,NODE6,NODE7,NODE8,NODE9,NODE10,NODE11,NODE12,NODE13,NODE14,NODE15,NODE16,TOOL
 SG_ payload_b5 : 40|8@1+ (1,0) [0|255] "raw"  MASTER,NODE1,NODE2,NODE3,NODE4,NODE5,NODE6,NODE7,NODE8,NODE9,NODE10,NODE11,NODE12,NODE13,NODE14,NODE15,NODE16,TOOL
 SG_ payload_b6 : 48|8@1+ (1,0) [0|255] "raw"  MASTER,NODE1,NODE2,NODE3,NODE4,NODE5,NODE6,NODE7,NODE8,NODE9,NODE10,NODE11,NODE12,NODE13,NODE14,NODE15,NODE16,TOOL
 SG_ payload_b7 : 56|8@1+ (1,0) [0|255] "raw"  MASTER,NODE1,NODE2,NODE3,NODE4,NODE5,NODE6,NODE7,NODE8,NODE9,NODE10,NODE11,NODE12,NODE13,NODE14,NODE15,NODE16,TOOL

BO_ 1153 S3_NODE_STATUS_FAST_1: 8 NODE1
 SG_ status_flags : 0|8@1+ (1,0) [0|255] "bitfield"  MASTER,NODE1,NODE2,NODE3,NODE4,NODE5,NODE6,NODE7,NODE8,NODE9,NODE10,NODE11,NODE12,NODE13,NODE14,NODE15,NODE16,TOOL
 SG_ error_code : 8|8@1+ (1,0) [0|255] ""  MASTER,NODE1,NODE2,NODE3,NODE4,NODE5,NODE6,NODE7,NODE8,NODE9,NODE10,NODE11,NODE12,NODE13,NODE14,NODE15,NODE16,TOOL
 SG_ actual_rpm : 16|16@1+ (1,0) [0|10000] "rpm"  MASTER,NODE1,NODE2,NODE3,NODE4,NODE5,NODE6,NODE7,NODE8,NODE9,NODE10,NODE11,NODE12,NODE13,NODE14,NODE15,NODE16,TOOL
 SG_ actual_pos : 32|16@1+ (1.52587890625e-05,0) [0|0.9999847412109375] "rev"  MASTER,NODE1,NODE2,NODE3,NODE4,NODE5,NODE6,NODE7,NODE8,NODE9,NODE10,NODE11,NODE12,NODE13,NODE14,NODE15,NODE16,TOOL
 SG_ alive_counter : 48|8@1+ (1,0) [0|255] ""  MASTER,NODE1,NODE2,NODE3,NODE4,NODE5,NODE6,NODE7,NODE8,NODE9,NODE10,NODE11,NODE12,NODE13,NODE14,NODE15,NODE16,TOOL
 SG_ sync_error : 56|8@1- (0.00390625,0) [-0.5|0.49609375] "rev"  MASTER,NODE1,NODE2,NODE3,NODE4,NODE5,NODE6,NODE7,NODE8,NODE9,NODE10,NODE11,NODE12,NODE13,NODE14,NODE15,NODE16,TOOL

BO_ 1217 S3_NODE_DIAG_1: 8 NODE1
 SG_ bus_voltage : 0|16@1+ (0.1,0) [0|6553.5] "V"  MASTER,NODE1,NODE2,NODE3,NODE4,NODE5,NODE6,NODE7,NODE8,NODE9,NODE10,NODE11,NODE12,NODE13,NODE14,NODE15,NODE16,TOOL
 SG_ motor_current : 16|16@1- (0.1,0) [-3276.8|3276.7] "A"  MASTER,NODE1,NODE2,NODE3,NODE4,NODE5,NODE6,NODE7,NODE8,NODE9,NODE10,NODE11,NODE12,NODE13,NODE14,NODE15,NODE16,TOOL
 SG_ controller_temp : 32|8@1- (1,0) [-128|127] "degC"  MASTER,NODE1,NODE2,NODE3,NODE4,NODE5,NODE6,NODE7,NODE8,NODE9,NODE10,NODE11,NODE12,NODE13,NODE14,NODE15,NODE16,TOOL
 SG_ motor_temp : 40|8@1- (1,0) [-128|127] "degC"  MASTER,NODE1,NODE2,NODE3,NODE4,NODE5,NODE6,NODE7,NODE8,NODE9,NODE10,NODE11,NODE12,NODE13,NODE14,NODE15,NODE16,TOOL
 SG_ fault_flags : 48|8@1+ (1,0) [0|255] "bitfield"  MASTER,NODE1,NODE2,NODE3,NODE4,NODE5,NODE6,NODE7,NODE8,NODE9,NODE10,NODE11,NODE12,NODE13,NODE14,NODE15,NODE16,TOOL
 SG_ warning_flags : 56|8@1+ (1,0) [0|255] "bitfield"  MASTER,NODE1,NODE2,NODE3,NODE4,NODE5,NODE6,NODE7,NODE8,NODE9,NODE10,NODE11,NODE12,NODE13,NODE14,NODE15,NODE16,TOOL

BO_ 1042 S3_NODE_CMD_2: 8 MASTER
 SG_ node_command : 0|8@1+ (1,0) [0|255] ""  MASTER,NODE1,NODE2,NODE3,NODE4,NODE5,NODE6,NODE7,NODE8,NODE9,NODE10,NODE11,NODE12,NODE13,NODE14,NODE15,NODE16,TOOL
 SG_ node_flags : 8|8@1+ (1,0) [0|255] "bitfield"  MASTER,NODE1,NODE2,NODE3,NODE4,NODE5,NODE6,NODE7,NODE8,NODE9,NODE10,NODE11,NODE12,NODE13,NODE14,NODE15,NODE16,TOOL
 SG_ trim_rpm : 16|16@1- (0.1,0) [-3276.8|3276.7] "rpm"  MASTER,NODE1,NODE2,NODE3,NODE4,NODE5,NODE6,NODE7,NODE8,NODE9,NODE10,NODE11,NODE12,NODE13,NODE14,NODE15,NODE16,TOOL
 SG_ section_mask : 32|16@1+ (1,0) [0|65535] "bitmask"  MASTER,NODE1,NODE2,NODE3,NODE4,NODE5,NODE6,NODE7,NODE8,NODE9,NODE10,NODE11,NODE12,NODE13,NODE14,NODE15,NODE16,TOOL
 SG_ seq : 48|8@1+ (1,0) [0|255] ""  MASTER,NODE1,NODE2,NODE3,NODE4,NODE5,NODE6,NODE7,NODE8,NODE9,NODE10,NODE11,NODE12,NODE13,NODE14,NODE15,NODE16,TOOL
 SG_ reserved : 56|8@1+ (1,0) [0|255] ""  MASTER,NODE1,NODE2,NODE3,NODE4,NODE5,NODE6,NODE7,NODE8,NODE9,NODE10,NODE11,NODE12,NODE13,NODE14,NODE15,NODE16,TOOL

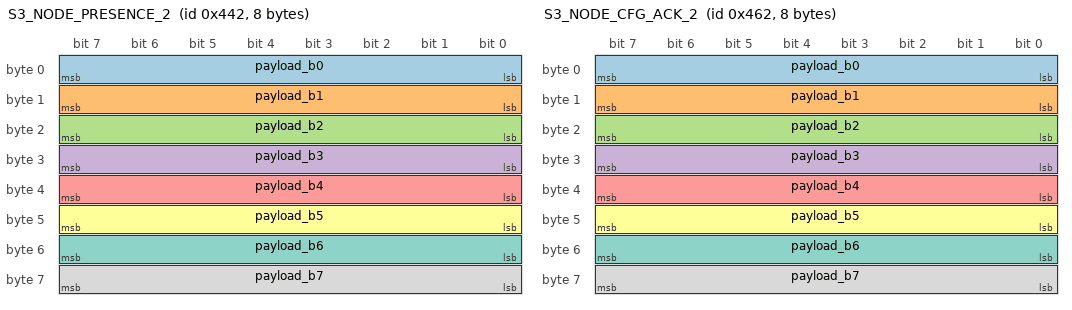
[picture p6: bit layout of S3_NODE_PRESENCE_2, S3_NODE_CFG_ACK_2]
BO_ 1090 S3_NODE_PRESENCE_2: 8 NODE2
 SG_ payload_b0 : 0|8@1+ (1,0) [0|255] "raw"  MASTER,NODE1,NODE2,NODE3,NODE4,NODE5,NODE6,NODE7,NODE8,NODE9,NODE10,NODE11,NODE12,NODE13,NODE14,NODE15,NODE16,TOOL
 SG_ payload_b1 : 8|8@1+ (1,0) [0|255] "raw"  MASTER,NODE1,NODE2,NODE3,NODE4,NODE5,NODE6,NODE7,NODE8,NODE9,NODE10,NODE11,NODE12,NODE13,NODE14,NODE15,NODE16,TOOL
 SG_ payload_b2 : 16|8@1+ (1,0) [0|255] "raw"  MASTER,NODE1,NODE2,NODE3,NODE4,NODE5,NODE6,NODE7,NODE8,NODE9,NODE10,NODE11,NODE12,NODE13,NODE14,NODE15,NODE16,TOOL
 SG_ payload_b3 : 24|8@1+ (1,0) [0|255] "raw"  MASTER,NODE1,NODE2,NODE3,NODE4,NODE5,NODE6,NODE7,NODE8,NODE9,NODE10,NODE11,NODE12,NODE13,NODE14,NODE15,NODE16,TOOL
 SG_ payload_b4 : 32|8@1+ (1,0) [0|255] "raw"  MASTER,NODE1,NODE2,NODE3,NODE4,NODE5,NODE6,NODE7,NODE8,NODE9,NODE10,NODE11,NODE12,NODE13,NODE14,NODE15,NODE16,TOOL
 SG_ payload_b5 : 40|8@1+ (1,0) [0|255] "raw"  MASTER,NODE1,NODE2,NODE3,NODE4,NODE5,NODE6,NODE7,NODE8,NODE9,NODE10,NODE11,NODE12,NODE13,NODE14,NODE15,NODE16,TOOL
 SG_ payload_b6 : 48|8@1+ (1,0) [0|255] "raw"  MASTER,NODE1,NODE2,NODE3,NODE4,NODE5,NODE6,NODE7,NODE8,NODE9,NODE10,NODE11,NODE12,NODE13,NODE14,NODE15,NODE16,TOOL
 SG_ payload_b7 : 56|8@1+ (1,0) [0|255] "raw"  MASTER,NODE1,NODE2,NODE3,NODE4,NODE5,NODE6,NODE7,NODE8,NODE9,NODE10,NODE11,NODE12,NODE13,NODE14,NODE15,NODE16,TOOL

BO_ 1122 S3_NODE_CFG_ACK_2: 8 NODE2
 SG_ payload_b0 : 0|8@1+ (1,0) [0|255] "raw"  MASTER,NODE1,NODE2,NODE3,NODE4,NODE5,NODE6,NODE7,NODE8,NODE9,NODE10,NODE11,NODE12,NODE13,NODE14,NODE15,NODE16,TOOL
 SG_ payload_b1 : 8|8@1+ (1,0) [0|255] "raw"  MASTER,NODE1,NODE2,NODE3,NODE4,NODE5,NODE6,NODE7,NODE8,NODE9,NODE10,NODE11,NODE12,NODE13,NODE14,NODE15,NODE16,TOOL
 SG_ payload_b2 : 16|8@1+ (1,0) [0|255] "raw"  MASTER,NODE1,NODE2,NODE3,NODE4,NODE5,NODE6,NODE7,NODE8,NODE9,NODE10,NODE11,NODE12,NODE13,NODE14,NODE15,NODE16,TOOL
 SG_ payload_b3 : 24|8@1+ (1,0) [0|255] "raw"  MASTER,NODE1,NODE2,NODE3,NODE4,NODE5,NODE6,NODE7,NODE8,NODE9,NODE10,NODE11,NODE12,NODE13,NODE14,NODE15,NODE16,TOOL
 SG_ payload_b4 : 32|8@1+ (1,0) [0|255] "raw"  MASTER,NODE1,NODE2,NODE3,NODE4,NODE5,NODE6,NODE7,NODE8,NODE9,NODE10,NODE11,NODE12,NODE13,NODE14,NODE15,NODE16,TOOL
 SG_ payload_b5 : 40|8@1+ (1,0) [0|255] "raw"  MASTER,NODE1,NODE2,NODE3,NODE4,NODE5,NODE6,NODE7,NODE8,NODE9,NODE10,NODE11,NODE12,NODE13,NODE14,NODE15,NODE16,TOOL
 SG_ payload_b6 : 48|8@1+ (1,0) [0|255] "raw"  MASTER,NODE1,NODE2,NODE3,NODE4,NODE5,NODE6,NODE7,NODE8,NODE9,NODE10,NODE11,NODE12,NODE13,NODE14,NODE15,NODE16,TOOL
 SG_ payload_b7 : 56|8@1+ (1,0) [0|255] "raw"  MASTER,NODE1,NODE2,NODE3,NODE4,NODE5,NODE6,NODE7,NODE8,NODE9,NODE10,NODE11,NODE12,NODE13,NODE14,NODE15,NODE16,TOOL

BO_ 1154 S3_NODE_STATUS_FAST_2: 8 NODE2
 SG_ status_flags : 0|8@1+ (1,0) [0|255] "bitfield"  MASTER,NODE1,NODE2,NODE3,NODE4,NODE5,NODE6,NODE7,NODE8,NODE9,NODE10,NODE11,NODE12,NODE13,NODE14,NODE15,NODE16,TOOL
 SG_ error_code : 8|8@1+ (1,0) [0|255] ""  MASTER,NODE1,NODE2,NODE3,NODE4,NODE5,NODE6,NODE7,NODE8,NODE9,NODE10,NODE11,NODE12,NODE13,NODE14,NODE15,NODE16,TOOL
 SG_ actual_rpm : 16|16@1+ (1,0) [0|10000] "rpm"  MASTER,NODE1,NODE2,NODE3,NODE4,NODE5,NODE6,NODE7,NODE8,NODE9,NODE10,NODE11,NODE12,NODE13,NODE14,NODE15,NODE16,TOOL
 SG_ actual_pos : 32|16@1+ (1.52587890625e-05,0) [0|0.9999847412109375] "rev"  MASTER,NODE1,NODE2,NODE3,NODE4,NODE5,NODE6,NODE7,NODE8,NODE9,NODE10,NODE11,NODE12,NODE13,NODE14,NODE15,NODE16,TOOL
 SG_ alive_counter : 48|8@1+ (1,0) [0|255] ""  MASTER,NODE1,NODE2,NODE3,NODE4,NODE5,NODE6,NODE7,NODE8,NODE9,NODE10,NODE11,NODE12,NODE13,NODE14,NODE15,NODE16,TOOL
 SG_ sync_error : 56|8@1- (0.00390625,0) [-0.5|0.49609375] "rev"  MASTER,NODE1,NODE2,NODE3,NODE4,NODE5,NODE6,NODE7,NODE8,NODE9,NODE10,NODE11,NODE12,NODE13,NODE14,NODE15,NODE16,TOOL

BO_ 1218 S3_NODE_DIAG_2: 8 NODE2
 SG_ bus_voltage : 0|16@1+ (0.1,0) [0|6553.5] "V"  MASTER,NODE1,NODE2,NODE3,NODE4,NODE5,NODE6,NODE7,NODE8,NODE9,NODE10,NODE11,NODE12,NODE13,NODE14,NODE15,NODE16,TOOL
 SG_ motor_current : 16|16@1- (0.1,0) [-3276.8|3276.7] "A"  MASTER,NODE1,NODE2,NODE3,NODE4,NODE5,NODE6,NODE7,NODE8,NODE9,NODE10,NODE11,NODE12,NODE13,NODE14,NODE15,NODE16,TOOL
 SG_ controller_temp : 32|8@1- (1,0) [-128|127] "degC"  MASTER,NODE1,NODE2,NODE3,NODE4,NODE5,NODE6,NODE7,NODE8,NODE9,NODE10,NODE11,NODE12,NODE13,NODE14,NODE15,NODE16,TOOL
 SG_ motor_temp : 40|8@1- (1,0) [-128|127] "degC"  MASTER,NODE1,NODE2,NODE3,NODE4,NODE5,NODE6,NODE7,NODE8,NODE9,NODE10,NODE11,NODE12,NODE13,NODE14,NODE15,NODE16,TOOL
 SG_ fault_flags : 48|8@1+ (1,0) [0|255] "bitfield"  MASTER,NODE1,NODE2,NODE3,NODE4,NODE5,NODE6,NODE7,NODE8,NODE9,NODE10,NODE11,NODE12,NODE13,NODE14,NODE15,NODE16,TOOL
 SG_ warning_flags : 56|8@1+ (1,0) [0|255] "bitfield"  MASTER,NODE1,NODE2,NODE3,NODE4,NODE5,NODE6,NODE7,NODE8,NODE9,NODE10,NODE11,NODE12,NODE13,NODE14,NODE15,NODE16,TOOL

BO_ 1043 S3_NODE_CMD_3: 8 MASTER
 SG_ node_command : 0|8@1+ (1,0) [0|255] ""  MASTER,NODE1,NODE2,NODE3,NODE4,NODE5,NODE6,NODE7,NODE8,NODE9,NODE10,NODE11,NODE12,NODE13,NODE14,NODE15,NODE16,TOOL
 SG_ node_flags : 8|8@1+ (1,0) [0|255] "bitfield"  MASTER,NODE1,NODE2,NODE3,NODE4,NODE5,NODE6,NODE7,NODE8,NODE9,NODE10,NODE11,NODE12,NODE13,NODE14,NODE15,NODE16,TOOL
 SG_ trim_rpm : 16|16@1- (0.1,0) [-3276.8|3276.7] "rpm"  MASTER,NODE1,NODE2,NODE3,NODE4,NODE5,NODE6,NODE7,NODE8,NODE9,NODE10,NODE11,NODE12,NODE13,NODE14,NODE15,NODE16,TOOL
 SG_ section_mask : 32|16@1+ (1,0) [0|65535] "bitmask"  MASTER,NODE1,NODE2,NODE3,NODE4,NODE5,NODE6,NODE7,NODE8,NODE9,NODE10,NODE11,NODE12,NODE13,NODE14,NODE15,NODE16,TOOL
 SG_ seq : 48|8@1+ (1,0) [0|255] ""  MASTER,NODE1,NODE2,NODE3,NODE4,NODE5,NODE6,NODE7,NODE8,NODE9,NODE10,NODE11,NODE12,NODE13,NODE14,NODE15,NODE16,TOOL
 SG_ reserved : 56|8@1+ (1,0) [0|255] ""  MASTER,NODE1,NODE2,NODE3,NODE4,NODE5,NODE6,NODE7,NODE8,NODE9,NODE10,NODE11,NODE12,NODE13,NODE14,NODE15,NODE16,TOOL

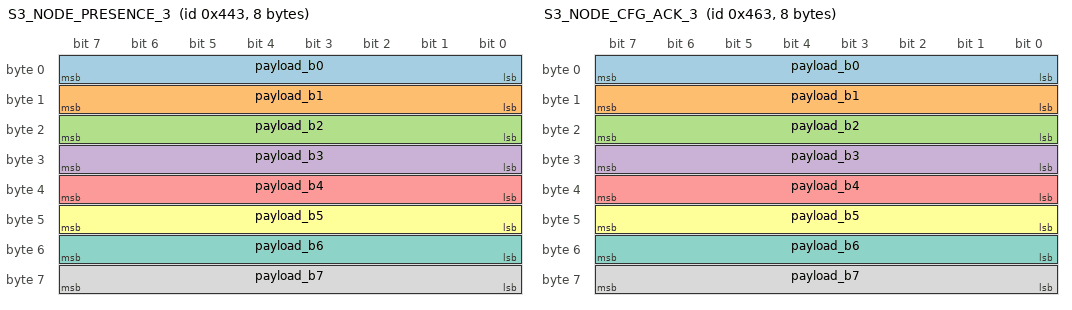
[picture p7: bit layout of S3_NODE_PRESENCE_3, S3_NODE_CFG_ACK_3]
BO_ 1091 S3_NODE_PRESENCE_3: 8 NODE3
 SG_ payload_b0 : 0|8@1+ (1,0) [0|255] "raw"  MASTER,NODE1,NODE2,NODE3,NODE4,NODE5,NODE6,NODE7,NODE8,NODE9,NODE10,NODE11,NODE12,NODE13,NODE14,NODE15,NODE16,TOOL
 SG_ payload_b1 : 8|8@1+ (1,0) [0|255] "raw"  MASTER,NODE1,NODE2,NODE3,NODE4,NODE5,NODE6,NODE7,NODE8,NODE9,NODE10,NODE11,NODE12,NODE13,NODE14,NODE15,NODE16,TOOL
 SG_ payload_b2 : 16|8@1+ (1,0) [0|255] "raw"  MASTER,NODE1,NODE2,NODE3,NODE4,NODE5,NODE6,NODE7,NODE8,NODE9,NODE10,NODE11,NODE12,NODE13,NODE14,NODE15,NODE16,TOOL
 SG_ payload_b3 : 24|8@1+ (1,0) [0|255] "raw"  MASTER,NODE1,NODE2,NODE3,NODE4,NODE5,NODE6,NODE7,NODE8,NODE9,NODE10,NODE11,NODE12,NODE13,NODE14,NODE15,NODE16,TOOL
 SG_ payload_b4 : 32|8@1+ (1,0) [0|255] "raw"  MASTER,NODE1,NODE2,NODE3,NODE4,NODE5,NODE6,NODE7,NODE8,NODE9,NODE10,NODE11,NODE12,NODE13,NODE14,NODE15,NODE16,TOOL
 SG_ payload_b5 : 40|8@1+ (1,0) [0|255] "raw"  MASTER,NODE1,NODE2,NODE3,NODE4,NODE5,NODE6,NODE7,NODE8,NODE9,NODE10,NODE11,NODE12,NODE13,NODE14,NODE15,NODE16,TOOL
 SG_ payload_b6 : 48|8@1+ (1,0) [0|255] "raw"  MASTER,NODE1,NODE2,NODE3,NODE4,NODE5,NODE6,NODE7,NODE8,NODE9,NODE10,NODE11,NODE12,NODE13,NODE14,NODE15,NODE16,TOOL
 SG_ payload_b7 : 56|8@1+ (1,0) [0|255] "raw"  MASTER,NODE1,NODE2,NODE3,NODE4,NODE5,NODE6,NODE7,NODE8,NODE9,NODE10,NODE11,NODE12,NODE13,NODE14,NODE15,NODE16,TOOL

BO_ 1123 S3_NODE_CFG_ACK_3: 8 NODE3
 SG_ payload_b0 : 0|8@1+ (1,0) [0|255] "raw"  MASTER,NODE1,NODE2,NODE3,NODE4,NODE5,NODE6,NODE7,NODE8,NODE9,NODE10,NODE11,NODE12,NODE13,NODE14,NODE15,NODE16,TOOL
 SG_ payload_b1 : 8|8@1+ (1,0) [0|255] "raw"  MASTER,NODE1,NODE2,NODE3,NODE4,NODE5,NODE6,NODE7,NODE8,NODE9,NODE10,NODE11,NODE12,NODE13,NODE14,NODE15,NODE16,TOOL
 SG_ payload_b2 : 16|8@1+ (1,0) [0|255] "raw"  MASTER,NODE1,NODE2,NODE3,NODE4,NODE5,NODE6,NODE7,NODE8,NODE9,NODE10,NODE11,NODE12,NODE13,NODE14,NODE15,NODE16,TOOL
 SG_ payload_b3 : 24|8@1+ (1,0) [0|255] "raw"  MASTER,NODE1,NODE2,NODE3,NODE4,NODE5,NODE6,NODE7,NODE8,NODE9,NODE10,NODE11,NODE12,NODE13,NODE14,NODE15,NODE16,TOOL
 SG_ payload_b4 : 32|8@1+ (1,0) [0|255] "raw"  MASTER,NODE1,NODE2,NODE3,NODE4,NODE5,NODE6,NODE7,NODE8,NODE9,NODE10,NODE11,NODE12,NODE13,NODE14,NODE15,NODE16,TOOL
 SG_ payload_b5 : 40|8@1+ (1,0) [0|255] "raw"  MASTER,NODE1,NODE2,NODE3,NODE4,NODE5,NODE6,NODE7,NODE8,NODE9,NODE10,NODE11,NODE12,NODE13,NODE14,NODE15,NODE16,TOOL
 SG_ payload_b6 : 48|8@1+ (1,0) [0|255] "raw"  MASTER,NODE1,NODE2,NODE3,NODE4,NODE5,NODE6,NODE7,NODE8,NODE9,NODE10,NODE11,NODE12,NODE13,NODE14,NODE15,NODE16,TOOL
 SG_ payload_b7 : 56|8@1+ (1,0) [0|255] "raw"  MASTER,NODE1,NODE2,NODE3,NODE4,NODE5,NODE6,NODE7,NODE8,NODE9,NODE10,NODE11,NODE12,NODE13,NODE14,NODE15,NODE16,TOOL

BO_ 1155 S3_NODE_STATUS_FAST_3: 8 NODE3
 SG_ status_flags : 0|8@1+ (1,0) [0|255] "bitfield"  MASTER,NODE1,NODE2,NODE3,NODE4,NODE5,NODE6,NODE7,NODE8,NODE9,NODE10,NODE11,NODE12,NODE13,NODE14,NODE15,NODE16,TOOL
 SG_ error_code : 8|8@1+ (1,0) [0|255] ""  MASTER,NODE1,NODE2,NODE3,NODE4,NODE5,NODE6,NODE7,NODE8,NODE9,NODE10,NODE11,NODE12,NODE13,NODE14,NODE15,NODE16,TOOL
 SG_ actual_rpm : 16|16@1+ (1,0) [0|10000] "rpm"  MASTER,NODE1,NODE2,NODE3,NODE4,NODE5,NODE6,NODE7,NODE8,NODE9,NODE10,NODE11,NODE12,NODE13,NODE14,NODE15,NODE16,TOOL
 SG_ actual_pos : 32|16@1+ (1.52587890625e-05,0) [0|0.9999847412109375] "rev"  MASTER,NODE1,NODE2,NODE3,NODE4,NODE5,NODE6,NODE7,NODE8,NODE9,NODE10,NODE11,NODE12,NODE13,NODE14,NODE15,NODE16,TOOL
 SG_ alive_counter : 48|8@1+ (1,0) [0|255] ""  MASTER,NODE1,NODE2,NODE3,NODE4,NODE5,NODE6,NODE7,NODE8,NODE9,NODE10,NODE11,NODE12,NODE13,NODE14,NODE15,NODE16,TOOL
 SG_ sync_error : 56|8@1- (0.00390625,0) [-0.5|0.49609375] "rev"  MASTER,NODE1,NODE2,NODE3,NODE4,NODE5,NODE6,NODE7,NODE8,NODE9,NODE10,NODE11,NODE12,NODE13,NODE14,NODE15,NODE16,TOOL

BO_ 1219 S3_NODE_DIAG_3: 8 NODE3
 SG_ bus_voltage : 0|16@1+ (0.1,0) [0|6553.5] "V"  MASTER,NODE1,NODE2,NODE3,NODE4,NODE5,NODE6,NODE7,NODE8,NODE9,NODE10,NODE11,NODE12,NODE13,NODE14,NODE15,NODE16,TOOL
 SG_ motor_current : 16|16@1- (0.1,0) [-3276.8|3276.7] "A"  MASTER,NODE1,NODE2,NODE3,NODE4,NODE5,NODE6,NODE7,NODE8,NODE9,NODE10,NODE11,NODE12,NODE13,NODE14,NODE15,NODE16,TOOL
 SG_ controller_temp : 32|8@1- (1,0) [-128|127] "degC"  MASTER,NODE1,NODE2,NODE3,NODE4,NODE5,NODE6,NODE7,NODE8,NODE9,NODE10,NODE11,NODE12,NODE13,NODE14,NODE15,NODE16,TOOL
 SG_ motor_temp : 40|8@1- (1,0) [-128|127] "degC"  MASTER,NODE1,NODE2,NODE3,NODE4,NODE5,NODE6,NODE7,NODE8,NODE9,NODE10,NODE11,NODE12,NODE13,NODE14,NODE15,NODE16,TOOL
 SG_ fault_flags : 48|8@1+ (1,0) [0|255] "bitfield"  MASTER,NODE1,NODE2,NODE3,NODE4,NODE5,NODE6,NODE7,NODE8,NODE9,NODE10,NODE11,NODE12,NODE13,NODE14,NODE15,NODE16,TOOL
 SG_ warning_flags : 56|8@1+ (1,0) [0|255] "bitfield"  MASTER,NODE1,NODE2,NODE3,NODE4,NODE5,NODE6,NODE7,NODE8,NODE9,NODE10,NODE11,NODE12,NODE13,NODE14,NODE15,NODE16,TOOL

BO_ 1044 S3_NODE_CMD_4: 8 MASTER
 SG_ node_command : 0|8@1+ (1,0) [0|255] ""  MASTER,NODE1,NODE2,NODE3,NODE4,NODE5,NODE6,NODE7,NODE8,NODE9,NODE10,NODE11,NODE12,NODE13,NODE14,NODE15,NODE16,TOOL
 SG_ node_flags : 8|8@1+ (1,0) [0|255] "bitfield"  MASTER,NODE1,NODE2,NODE3,NODE4,NODE5,NODE6,NODE7,NODE8,NODE9,NODE10,NODE11,NODE12,NODE13,NODE14,NODE15,NODE16,TOOL
 SG_ trim_rpm : 16|16@1- (0.1,0) [-3276.8|3276.7] "rpm"  MASTER,NODE1,NODE2,NODE3,NODE4,NODE5,NODE6,NODE7,NODE8,NODE9,NODE10,NODE11,NODE12,NODE13,NODE14,NODE15,NODE16,TOOL
 SG_ section_mask : 32|16@1+ (1,0) [0|65535] "bitmask"  MASTER,NODE1,NODE2,NODE3,NODE4,NODE5,NODE6,NODE7,NODE8,NODE9,NODE10,NODE11,NODE12,NODE13,NODE14,NODE15,NODE16,TOOL
 SG_ seq : 48|8@1+ (1,0) [0|255] ""  MASTER,NODE1,NODE2,NODE3,NODE4,NODE5,NODE6,NODE7,NODE8,NODE9,NODE10,NODE11,NODE12,NODE13,NODE14,NODE15,NODE16,TOOL
 SG_ reserved : 56|8@1+ (1,0) [0|255] ""  MASTER,NODE1,NODE2,NODE3,NODE4,NODE5,NODE6,NODE7,NODE8,NODE9,NODE10,NODE11,NODE12,NODE13,NODE14,NODE15,NODE16,TOOL

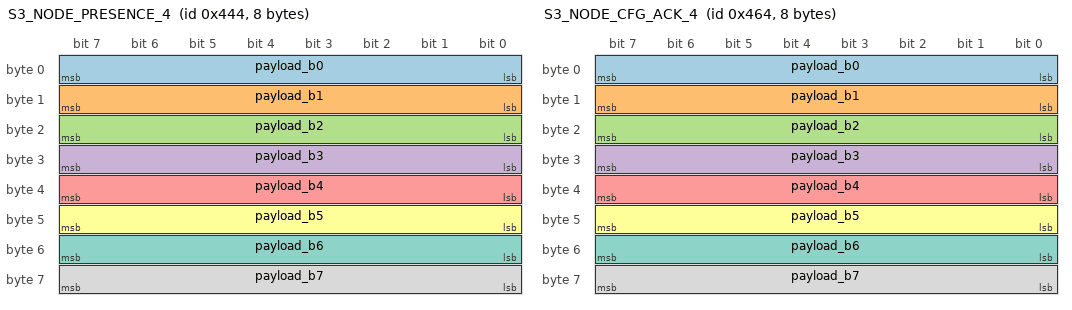
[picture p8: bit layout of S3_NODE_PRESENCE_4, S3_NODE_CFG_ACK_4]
BO_ 1092 S3_NODE_PRESENCE_4: 8 NODE4
 SG_ payload_b0 : 0|8@1+ (1,0) [0|255] "raw"  MASTER,NODE1,NODE2,NODE3,NODE4,NODE5,NODE6,NODE7,NODE8,NODE9,NODE10,NODE11,NODE12,NODE13,NODE14,NODE15,NODE16,TOOL
 SG_ payload_b1 : 8|8@1+ (1,0) [0|255] "raw"  MASTER,NODE1,NODE2,NODE3,NODE4,NODE5,NODE6,NODE7,NODE8,NODE9,NODE10,NODE11,NODE12,NODE13,NODE14,NODE15,NODE16,TOOL
 SG_ payload_b2 : 16|8@1+ (1,0) [0|255] "raw"  MASTER,NODE1,NODE2,NODE3,NODE4,NODE5,NODE6,NODE7,NODE8,NODE9,NODE10,NODE11,NODE12,NODE13,NODE14,NODE15,NODE16,TOOL
 SG_ payload_b3 : 24|8@1+ (1,0) [0|255] "raw"  MASTER,NODE1,NODE2,NODE3,NODE4,NODE5,NODE6,NODE7,NODE8,NODE9,NODE10,NODE11,NODE12,NODE13,NODE14,NODE15,NODE16,TOOL
 SG_ payload_b4 : 32|8@1+ (1,0) [0|255] "raw"  MASTER,NODE1,NODE2,NODE3,NODE4,NODE5,NODE6,NODE7,NODE8,NODE9,NODE10,NODE11,NODE12,NODE13,NODE14,NODE15,NODE16,TOOL
 SG_ payload_b5 : 40|8@1+ (1,0) [0|255] "raw"  MASTER,NODE1,NODE2,NODE3,NODE4,NODE5,NODE6,NODE7,NODE8,NODE9,NODE10,NODE11,NODE12,NODE13,NODE14,NODE15,NODE16,TOOL
 SG_ payload_b6 : 48|8@1+ (1,0) [0|255] "raw"  MASTER,NODE1,NODE2,NODE3,NODE4,NODE5,NODE6,NODE7,NODE8,NODE9,NODE10,NODE11,NODE12,NODE13,NODE14,NODE15,NODE16,TOOL
 SG_ payload_b7 : 56|8@1+ (1,0) [0|255] "raw"  MASTER,NODE1,NODE2,NODE3,NODE4,NODE5,NODE6,NODE7,NODE8,NODE9,NODE10,NODE11,NODE12,NODE13,NODE14,NODE15,NODE16,TOOL

BO_ 1124 S3_NODE_CFG_ACK_4: 8 NODE4
 SG_ payload_b0 : 0|8@1+ (1,0) [0|255] "raw"  MASTER,NODE1,NODE2,NODE3,NODE4,NODE5,NODE6,NODE7,NODE8,NODE9,NODE10,NODE11,NODE12,NODE13,NODE14,NODE15,NODE16,TOOL
 SG_ payload_b1 : 8|8@1+ (1,0) [0|255] "raw"  MASTER,NODE1,NODE2,NODE3,NODE4,NODE5,NODE6,NODE7,NODE8,NODE9,NODE10,NODE11,NODE12,NODE13,NODE14,NODE15,NODE16,TOOL
 SG_ payload_b2 : 16|8@1+ (1,0) [0|255] "raw"  MASTER,NODE1,NODE2,NODE3,NODE4,NODE5,NODE6,NODE7,NODE8,NODE9,NODE10,NODE11,NODE12,NODE13,NODE14,NODE15,NODE16,TOOL
 SG_ payload_b3 : 24|8@1+ (1,0) [0|255] "raw"  MASTER,NODE1,NODE2,NODE3,NODE4,NODE5,NODE6,NODE7,NODE8,NODE9,NODE10,NODE11,NODE12,NODE13,NODE14,NODE15,NODE16,TOOL
 SG_ payload_b4 : 32|8@1+ (1,0) [0|255] "raw"  MASTER,NODE1,NODE2,NODE3,NODE4,NODE5,NODE6,NODE7,NODE8,NODE9,NODE10,NODE11,NODE12,NODE13,NODE14,NODE15,NODE16,TOOL
 SG_ payload_b5 : 40|8@1+ (1,0) [0|255] "raw"  MASTER,NODE1,NODE2,NODE3,NODE4,NODE5,NODE6,NODE7,NODE8,NODE9,NODE10,NODE11,NODE12,NODE13,NODE14,NODE15,NODE16,TOOL
 SG_ payload_b6 : 48|8@1+ (1,0) [0|255] "raw"  MASTER,NODE1,NODE2,NODE3,NODE4,NODE5,NODE6,NODE7,NODE8,NODE9,NODE10,NODE11,NODE12,NODE13,NODE14,NODE15,NODE16,TOOL
 SG_ payload_b7 : 56|8@1+ (1,0) [0|255] "raw"  MASTER,NODE1,NODE2,NODE3,NODE4,NODE5,NODE6,NODE7,NODE8,NODE9,NODE10,NODE11,NODE12,NODE13,NODE14,NODE15,NODE16,TOOL

BO_ 1156 S3_NODE_STATUS_FAST_4: 8 NODE4
 SG_ status_flags : 0|8@1+ (1,0) [0|255] "bitfield"  MASTER,NODE1,NODE2,NODE3,NODE4,NODE5,NODE6,NODE7,NODE8,NODE9,NODE10,NODE11,NODE12,NODE13,NODE14,NODE15,NODE16,TOOL
 SG_ error_code : 8|8@1+ (1,0) [0|255] ""  MASTER,NODE1,NODE2,NODE3,NODE4,NODE5,NODE6,NODE7,NODE8,NODE9,NODE10,NODE11,NODE12,NODE13,NODE14,NODE15,NODE16,TOOL
 SG_ actual_rpm : 16|16@1+ (1,0) [0|10000] "rpm"  MASTER,NODE1,NODE2,NODE3,NODE4,NODE5,NODE6,NODE7,NODE8,NODE9,NODE10,NODE11,NODE12,NODE13,NODE14,NODE15,NODE16,TOOL
 SG_ actual_pos : 32|16@1+ (1.52587890625e-05,0) [0|0.9999847412109375] "rev"  MASTER,NODE1,NODE2,NODE3,NODE4,NODE5,NODE6,NODE7,NODE8,NODE9,NODE10,NODE11,NODE12,NODE13,NODE14,NODE15,NODE16,TOOL
 SG_ alive_counter : 48|8@1+ (1,0) [0|255] ""  MASTER,NODE1,NODE2,NODE3,NODE4,NODE5,NODE6,NODE7,NODE8,NODE9,NODE10,NODE11,NODE12,NODE13,NODE14,NODE15,NODE16,TOOL
 SG_ sync_error : 56|8@1- (0.00390625,0) [-0.5|0.49609375] "rev"  MASTER,NODE1,NODE2,NODE3,NODE4,NODE5,NODE6,NODE7,NODE8,NODE9,NODE10,NODE11,NODE12,NODE13,NODE14,NODE15,NODE16,TOOL

BO_ 1220 S3_NODE_DIAG_4: 8 NODE4
 SG_ bus_voltage : 0|16@1+ (0.1,0) [0|6553.5] "V"  MASTER,NODE1,NODE2,NODE3,NODE4,NODE5,NODE6,NODE7,NODE8,NODE9,NODE10,NODE11,NODE12,NODE13,NODE14,NODE15,NODE16,TOOL
 SG_ motor_current : 16|16@1- (0.1,0) [-3276.8|3276.7] "A"  MASTER,NODE1,NODE2,NODE3,NODE4,NODE5,NODE6,NODE7,NODE8,NODE9,NODE10,NODE11,NODE12,NODE13,NODE14,NODE15,NODE16,TOOL
 SG_ controller_temp : 32|8@1- (1,0) [-128|127] "degC"  MASTER,NODE1,NODE2,NODE3,NODE4,NODE5,NODE6,NODE7,NODE8,NODE9,NODE10,NODE11,NODE12,NODE13,NODE14,NODE15,NODE16,TOOL
 SG_ motor_temp : 40|8@1- (1,0) [-128|127] "degC"  MASTER,NODE1,NODE2,NODE3,NODE4,NODE5,NODE6,NODE7,NODE8,NODE9,NODE10,NODE11,NODE12,NODE13,NODE14,NODE15,NODE16,TOOL
 SG_ fault_flags : 48|8@1+ (1,0) [0|255] "bitfield"  MASTER,NODE1,NODE2,NODE3,NODE4,NODE5,NODE6,NODE7,NODE8,NODE9,NODE10,NODE11,NODE12,NODE13,NODE14,NODE15,NODE16,TOOL
 SG_ warning_flags : 56|8@1+ (1,0) [0|255] "bitfield"  MASTER,NODE1,NODE2,NODE3,NODE4,NODE5,NODE6,NODE7,NODE8,NODE9,NODE10,NODE11,NODE12,NODE13,NODE14,NODE15,NODE16,TOOL

BO_ 1045 S3_NODE_CMD_5: 8 MASTER
 SG_ node_command : 0|8@1+ (1,0) [0|255] ""  MASTER,NODE1,NODE2,NODE3,NODE4,NODE5,NODE6,NODE7,NODE8,NODE9,NODE10,NODE11,NODE12,NODE13,NODE14,NODE15,NODE16,TOOL
 SG_ node_flags : 8|8@1+ (1,0) [0|255] "bitfield"  MASTER,NODE1,NODE2,NODE3,NODE4,NODE5,NODE6,NODE7,NODE8,NODE9,NODE10,NODE11,NODE12,NODE13,NODE14,NODE15,NODE16,TOOL
 SG_ trim_rpm : 16|16@1- (0.1,0) [-3276.8|3276.7] "rpm"  MASTER,NODE1,NODE2,NODE3,NODE4,NODE5,NODE6,NODE7,NODE8,NODE9,NODE10,NODE11,NODE12,NODE13,NODE14,NODE15,NODE16,TOOL
 SG_ section_mask : 32|16@1+ (1,0) [0|65535] "bitmask"  MASTER,NODE1,NODE2,NODE3,NODE4,NODE5,NODE6,NODE7,NODE8,NODE9,NODE10,NODE11,NODE12,NODE13,NODE14,NODE15,NODE16,TOOL
 SG_ seq : 48|8@1+ (1,0) [0|255] ""  MASTER,NODE1,NODE2,NODE3,NODE4,NODE5,NODE6,NODE7,NODE8,NODE9,NODE10,NODE11,NODE12,NODE13,NODE14,NODE15,NODE16,TOOL
 SG_ reserved : 56|8@1+ (1,0) [0|255] ""  MASTER,NODE1,NODE2,NODE3,NODE4,NODE5,NODE6,NODE7,NODE8,NODE9,NODE10,NODE11,NODE12,NODE13,NODE14,NODE15,NODE16,TOOL

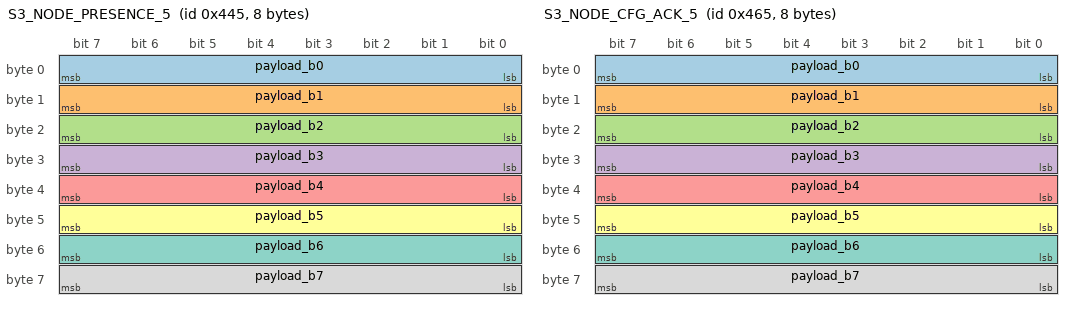
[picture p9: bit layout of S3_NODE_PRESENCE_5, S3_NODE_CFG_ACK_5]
BO_ 1093 S3_NODE_PRESENCE_5: 8 NODE5
 SG_ payload_b0 : 0|8@1+ (1,0) [0|255] "raw"  MASTER,NODE1,NODE2,NODE3,NODE4,NODE5,NODE6,NODE7,NODE8,NODE9,NODE10,NODE11,NODE12,NODE13,NODE14,NODE15,NODE16,TOOL
 SG_ payload_b1 : 8|8@1+ (1,0) [0|255] "raw"  MASTER,NODE1,NODE2,NODE3,NODE4,NODE5,NODE6,NODE7,NODE8,NODE9,NODE10,NODE11,NODE12,NODE13,NODE14,NODE15,NODE16,TOOL
 SG_ payload_b2 : 16|8@1+ (1,0) [0|255] "raw"  MASTER,NODE1,NODE2,NODE3,NODE4,NODE5,NODE6,NODE7,NODE8,NODE9,NODE10,NODE11,NODE12,NODE13,NODE14,NODE15,NODE16,TOOL
 SG_ payload_b3 : 24|8@1+ (1,0) [0|255] "raw"  MASTER,NODE1,NODE2,NODE3,NODE4,NODE5,NODE6,NODE7,NODE8,NODE9,NODE10,NODE11,NODE12,NODE13,NODE14,NODE15,NODE16,TOOL
 SG_ payload_b4 : 32|8@1+ (1,0) [0|255] "raw"  MASTER,NODE1,NODE2,NODE3,NODE4,NODE5,NODE6,NODE7,NODE8,NODE9,NODE10,NODE11,NODE12,NODE13,NODE14,NODE15,NODE16,TOOL
 SG_ payload_b5 : 40|8@1+ (1,0) [0|255] "raw"  MASTER,NODE1,NODE2,NODE3,NODE4,NODE5,NODE6,NODE7,NODE8,NODE9,NODE10,NODE11,NODE12,NODE13,NODE14,NODE15,NODE16,TOOL
 SG_ payload_b6 : 48|8@1+ (1,0) [0|255] "raw"  MASTER,NODE1,NODE2,NODE3,NODE4,NODE5,NODE6,NODE7,NODE8,NODE9,NODE10,NODE11,NODE12,NODE13,NODE14,NODE15,NODE16,TOOL
 SG_ payload_b7 : 56|8@1+ (1,0) [0|255] "raw"  MASTER,NODE1,NODE2,NODE3,NODE4,NODE5,NODE6,NODE7,NODE8,NODE9,NODE10,NODE11,NODE12,NODE13,NODE14,NODE15,NODE16,TOOL

BO_ 1125 S3_NODE_CFG_ACK_5: 8 NODE5
 SG_ payload_b0 : 0|8@1+ (1,0) [0|255] "raw"  MASTER,NODE1,NODE2,NODE3,NODE4,NODE5,NODE6,NODE7,NODE8,NODE9,NODE10,NODE11,NODE12,NODE13,NODE14,NODE15,NODE16,TOOL
 SG_ payload_b1 : 8|8@1+ (1,0) [0|255] "raw"  MASTER,NODE1,NODE2,NODE3,NODE4,NODE5,NODE6,NODE7,NODE8,NODE9,NODE10,NODE11,NODE12,NODE13,NODE14,NODE15,NODE16,TOOL
 SG_ payload_b2 : 16|8@1+ (1,0) [0|255] "raw"  MASTER,NODE1,NODE2,NODE3,NODE4,NODE5,NODE6,NODE7,NODE8,NODE9,NODE10,NODE11,NODE12,NODE13,NODE14,NODE15,NODE16,TOOL
 SG_ payload_b3 : 24|8@1+ (1,0) [0|255] "raw"  MASTER,NODE1,NODE2,NODE3,NODE4,NODE5,NODE6,NODE7,NODE8,NODE9,NODE10,NODE11,NODE12,NODE13,NODE14,NODE15,NODE16,TOOL
 SG_ payload_b4 : 32|8@1+ (1,0) [0|255] "raw"  MASTER,NODE1,NODE2,NODE3,NODE4,NODE5,NODE6,NODE7,NODE8,NODE9,NODE10,NODE11,NODE12,NODE13,NODE14,NODE15,NODE16,TOOL
 SG_ payload_b5 : 40|8@1+ (1,0) [0|255] "raw"  MASTER,NODE1,NODE2,NODE3,NODE4,NODE5,NODE6,NODE7,NODE8,NODE9,NODE10,NODE11,NODE12,NODE13,NODE14,NODE15,NODE16,TOOL
 SG_ payload_b6 : 48|8@1+ (1,0) [0|255] "raw"  MASTER,NODE1,NODE2,NODE3,NODE4,NODE5,NODE6,NODE7,NODE8,NODE9,NODE10,NODE11,NODE12,NODE13,NODE14,NODE15,NODE16,TOOL
 SG_ payload_b7 : 56|8@1+ (1,0) [0|255] "raw"  MASTER,NODE1,NODE2,NODE3,NODE4,NODE5,NODE6,NODE7,NODE8,NODE9,NODE10,NODE11,NODE12,NODE13,NODE14,NODE15,NODE16,TOOL

BO_ 1157 S3_NODE_STATUS_FAST_5: 8 NODE5
 SG_ status_flags : 0|8@1+ (1,0) [0|255] "bitfield"  MASTER,NODE1,NODE2,NODE3,NODE4,NODE5,NODE6,NODE7,NODE8,NODE9,NODE10,NODE11,NODE12,NODE13,NODE14,NODE15,NODE16,TOOL
 SG_ error_code : 8|8@1+ (1,0) [0|255] ""  MASTER,NODE1,NODE2,NODE3,NODE4,NODE5,NODE6,NODE7,NODE8,NODE9,NODE10,NODE11,NODE12,NODE13,NODE14,NODE15,NODE16,TOOL
 SG_ actual_rpm : 16|16@1+ (1,0) [0|10000] "rpm"  MASTER,NODE1,NODE2,NODE3,NODE4,NODE5,NODE6,NODE7,NODE8,NODE9,NODE10,NODE11,NODE12,NODE13,NODE14,NODE15,NODE16,TOOL
 SG_ actual_pos : 32|16@1+ (1.52587890625e-05,0) [0|0.9999847412109375] "rev"  MASTER,NODE1,NODE2,NODE3,NODE4,NODE5,NODE6,NODE7,NODE8,NODE9,NODE10,NODE11,NODE12,NODE13,NODE14,NODE15,NODE16,TOOL
 SG_ alive_counter : 48|8@1+ (1,0) [0|255] ""  MASTER,NODE1,NODE2,NODE3,NODE4,NODE5,NODE6,NODE7,NODE8,NODE9,NODE10,NODE11,NODE12,NODE13,NODE14,NODE15,NODE16,TOOL
 SG_ sync_error : 56|8@1- (0.00390625,0) [-0.5|0.49609375] "rev"  MASTER,NODE1,NODE2,NODE3,NODE4,NODE5,NODE6,NODE7,NODE8,NODE9,NODE10,NODE11,NODE12,NODE13,NODE14,NODE15,NODE16,TOOL

BO_ 1221 S3_NODE_DIAG_5: 8 NODE5
 SG_ bus_voltage : 0|16@1+ (0.1,0) [0|6553.5] "V"  MASTER,NODE1,NODE2,NODE3,NODE4,NODE5,NODE6,NODE7,NODE8,NODE9,NODE10,NODE11,NODE12,NODE13,NODE14,NODE15,NODE16,TOOL
 SG_ motor_current : 16|16@1- (0.1,0) [-3276.8|3276.7] "A"  MASTER,NODE1,NODE2,NODE3,NODE4,NODE5,NODE6,NODE7,NODE8,NODE9,NODE10,NODE11,NODE12,NODE13,NODE14,NODE15,NODE16,TOOL
 SG_ controller_temp : 32|8@1- (1,0) [-128|127] "degC"  MASTER,NODE1,NODE2,NODE3,NODE4,NODE5,NODE6,NODE7,NODE8,NODE9,NODE10,NODE11,NODE12,NODE13,NODE14,NODE15,NODE16,TOOL
 SG_ motor_temp : 40|8@1- (1,0) [-128|127] "degC"  MASTER,NODE1,NODE2,NODE3,NODE4,NODE5,NODE6,NODE7,NODE8,NODE9,NODE10,NODE11,NODE12,NODE13,NODE14,NODE15,NODE16,TOOL
 SG_ fault_flags : 48|8@1+ (1,0) [0|255] "bitfield"  MASTER,NODE1,NODE2,NODE3,NODE4,NODE5,NODE6,NODE7,NODE8,NODE9,NODE10,NODE11,NODE12,NODE13,NODE14,NODE15,NODE16,TOOL
 SG_ warning_flags : 56|8@1+ (1,0) [0|255] "bitfield"  MASTER,NODE1,NODE2,NODE3,NODE4,NODE5,NODE6,NODE7,NODE8,NODE9,NODE10,NODE11,NODE12,NODE13,NODE14,NODE15,NODE16,TOOL

BO_ 1046 S3_NODE_CMD_6: 8 MASTER
 SG_ node_command : 0|8@1+ (1,0) [0|255] ""  MASTER,NODE1,NODE2,NODE3,NODE4,NODE5,NODE6,NODE7,NODE8,NODE9,NODE10,NODE11,NODE12,NODE13,NODE14,NODE15,NODE16,TOOL
 SG_ node_flags : 8|8@1+ (1,0) [0|255] "bitfield"  MASTER,NODE1,NODE2,NODE3,NODE4,NODE5,NODE6,NODE7,NODE8,NODE9,NODE10,NODE11,NODE12,NODE13,NODE14,NODE15,NODE16,TOOL
 SG_ trim_rpm : 16|16@1- (0.1,0) [-3276.8|3276.7] "rpm"  MASTER,NODE1,NODE2,NODE3,NODE4,NODE5,NODE6,NODE7,NODE8,NODE9,NODE10,NODE11,NODE12,NODE13,NODE14,NODE15,NODE16,TOOL
 SG_ section_mask : 32|16@1+ (1,0) [0|65535] "bitmask"  MASTER,NODE1,NODE2,NODE3,NODE4,NODE5,NODE6,NODE7,NODE8,NODE9,NODE10,NODE11,NODE12,NODE13,NODE14,NODE15,NODE16,TOOL
 SG_ seq : 48|8@1+ (1,0) [0|255] ""  MASTER,NODE1,NODE2,NODE3,NODE4,NODE5,NODE6,NODE7,NODE8,NODE9,NODE10,NODE11,NODE12,NODE13,NODE14,NODE15,NODE16,TOOL
 SG_ reserved : 56|8@1+ (1,0) [0|255] ""  MASTER,NODE1,NODE2,NODE3,NODE4,NODE5,NODE6,NODE7,NODE8,NODE9,NODE10,NODE11,NODE12,NODE13,NODE14,NODE15,NODE16,TOOL

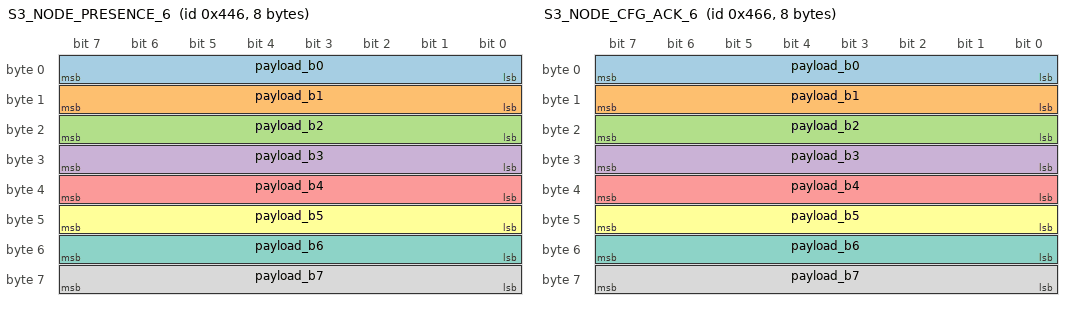
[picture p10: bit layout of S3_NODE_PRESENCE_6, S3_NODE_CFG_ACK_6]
BO_ 1094 S3_NODE_PRESENCE_6: 8 NODE6
 SG_ payload_b0 : 0|8@1+ (1,0) [0|255] "raw"  MASTER,NODE1,NODE2,NODE3,NODE4,NODE5,NODE6,NODE7,NODE8,NODE9,NODE10,NODE11,NODE12,NODE13,NODE14,NODE15,NODE16,TOOL
 SG_ payload_b1 : 8|8@1+ (1,0) [0|255] "raw"  MASTER,NODE1,NODE2,NODE3,NODE4,NODE5,NODE6,NODE7,NODE8,NODE9,NODE10,NODE11,NODE12,NODE13,NODE14,NODE15,NODE16,TOOL
 SG_ payload_b2 : 16|8@1+ (1,0) [0|255] "raw"  MASTER,NODE1,NODE2,NODE3,NODE4,NODE5,NODE6,NODE7,NODE8,NODE9,NODE10,NODE11,NODE12,NODE13,NODE14,NODE15,NODE16,TOOL
 SG_ payload_b3 : 24|8@1+ (1,0) [0|255] "raw"  MASTER,NODE1,NODE2,NODE3,NODE4,NODE5,NODE6,NODE7,NODE8,NODE9,NODE10,NODE11,NODE12,NODE13,NODE14,NODE15,NODE16,TOOL
 SG_ payload_b4 : 32|8@1+ (1,0) [0|255] "raw"  MASTER,NODE1,NODE2,NODE3,NODE4,NODE5,NODE6,NODE7,NODE8,NODE9,NODE10,NODE11,NODE12,NODE13,NODE14,NODE15,NODE16,TOOL
 SG_ payload_b5 : 40|8@1+ (1,0) [0|255] "raw"  MASTER,NODE1,NODE2,NODE3,NODE4,NODE5,NODE6,NODE7,NODE8,NODE9,NODE10,NODE11,NODE12,NODE13,NODE14,NODE15,NODE16,TOOL
 SG_ payload_b6 : 48|8@1+ (1,0) [0|255] "raw"  MASTER,NODE1,NODE2,NODE3,NODE4,NODE5,NODE6,NODE7,NODE8,NODE9,NODE10,NODE11,NODE12,NODE13,NODE14,NODE15,NODE16,TOOL
 SG_ payload_b7 : 56|8@1+ (1,0) [0|255] "raw"  MASTER,NODE1,NODE2,NODE3,NODE4,NODE5,NODE6,NODE7,NODE8,NODE9,NODE10,NODE11,NODE12,NODE13,NODE14,NODE15,NODE16,TOOL

BO_ 1126 S3_NODE_CFG_ACK_6: 8 NODE6
 SG_ payload_b0 : 0|8@1+ (1,0) [0|255] "raw"  MASTER,NODE1,NODE2,NODE3,NODE4,NODE5,NODE6,NODE7,NODE8,NODE9,NODE10,NODE11,NODE12,NODE13,NODE14,NODE15,NODE16,TOOL
 SG_ payload_b1 : 8|8@1+ (1,0) [0|255] "raw"  MASTER,NODE1,NODE2,NODE3,NODE4,NODE5,NODE6,NODE7,NODE8,NODE9,NODE10,NODE11,NODE12,NODE13,NODE14,NODE15,NODE16,TOOL
 SG_ payload_b2 : 16|8@1+ (1,0) [0|255] "raw"  MASTER,NODE1,NODE2,NODE3,NODE4,NODE5,NODE6,NODE7,NODE8,NODE9,NODE10,NODE11,NODE12,NODE13,NODE14,NODE15,NODE16,TOOL
 SG_ payload_b3 : 24|8@1+ (1,0) [0|255] "raw"  MASTER,NODE1,NODE2,NODE3,NODE4,NODE5,NODE6,NODE7,NODE8,NODE9,NODE10,NODE11,NODE12,NODE13,NODE14,NODE15,NODE16,TOOL
 SG_ payload_b4 : 32|8@1+ (1,0) [0|255] "raw"  MASTER,NODE1,NODE2,NODE3,NODE4,NODE5,NODE6,NODE7,NODE8,NODE9,NODE10,NODE11,NODE12,NODE13,NODE14,NODE15,NODE16,TOOL
 SG_ payload_b5 : 40|8@1+ (1,0) [0|255] "raw"  MASTER,NODE1,NODE2,NODE3,NODE4,NODE5,NODE6,NODE7,NODE8,NODE9,NODE10,NODE11,NODE12,NODE13,NODE14,NODE15,NODE16,TOOL
 SG_ payload_b6 : 48|8@1+ (1,0) [0|255] "raw"  MASTER,NODE1,NODE2,NODE3,NODE4,NODE5,NODE6,NODE7,NODE8,NODE9,NODE10,NODE11,NODE12,NODE13,NODE14,NODE15,NODE16,TOOL
 SG_ payload_b7 : 56|8@1+ (1,0) [0|255] "raw"  MASTER,NODE1,NODE2,NODE3,NODE4,NODE5,NODE6,NODE7,NODE8,NODE9,NODE10,NODE11,NODE12,NODE13,NODE14,NODE15,NODE16,TOOL

BO_ 1158 S3_NODE_STATUS_FAST_6: 8 NODE6
 SG_ status_flags : 0|8@1+ (1,0) [0|255] "bitfield"  MASTER,NODE1,NODE2,NODE3,NODE4,NODE5,NODE6,NODE7,NODE8,NODE9,NODE10,NODE11,NODE12,NODE13,NODE14,NODE15,NODE16,TOOL
 SG_ error_code : 8|8@1+ (1,0) [0|255] ""  MASTER,NODE1,NODE2,NODE3,NODE4,NODE5,NODE6,NODE7,NODE8,NODE9,NODE10,NODE11,NODE12,NODE13,NODE14,NODE15,NODE16,TOOL
 SG_ actual_rpm : 16|16@1+ (1,0) [0|10000] "rpm"  MASTER,NODE1,NODE2,NODE3,NODE4,NODE5,NODE6,NODE7,NODE8,NODE9,NODE10,NODE11,NODE12,NODE13,NODE14,NODE15,NODE16,TOOL
 SG_ actual_pos : 32|16@1+ (1.52587890625e-05,0) [0|0.9999847412109375] "rev"  MASTER,NODE1,NODE2,NODE3,NODE4,NODE5,NODE6,NODE7,NODE8,NODE9,NODE10,NODE11,NODE12,NODE13,NODE14,NODE15,NODE16,TOOL
 SG_ alive_counter : 48|8@1+ (1,0) [0|255] ""  MASTER,NODE1,NODE2,NODE3,NODE4,NODE5,NODE6,NODE7,NODE8,NODE9,NODE10,NODE11,NODE12,NODE13,NODE14,NODE15,NODE16,TOOL
 SG_ sync_error : 56|8@1- (0.00390625,0) [-0.5|0.49609375] "rev"  MASTER,NODE1,NODE2,NODE3,NODE4,NODE5,NODE6,NODE7,NODE8,NODE9,NODE10,NODE11,NODE12,NODE13,NODE14,NODE15,NODE16,TOOL

BO_ 1222 S3_NODE_DIAG_6: 8 NODE6
 SG_ bus_voltage : 0|16@1+ (0.1,0) [0|6553.5] "V"  MASTER,NODE1,NODE2,NODE3,NODE4,NODE5,NODE6,NODE7,NODE8,NODE9,NODE10,NODE11,NODE12,NODE13,NODE14,NODE15,NODE16,TOOL
 SG_ motor_current : 16|16@1- (0.1,0) [-3276.8|3276.7] "A"  MASTER,NODE1,NODE2,NODE3,NODE4,NODE5,NODE6,NODE7,NODE8,NODE9,NODE10,NODE11,NODE12,NODE13,NODE14,NODE15,NODE16,TOOL
 SG_ controller_temp : 32|8@1- (1,0) [-128|127] "degC"  MASTER,NODE1,NODE2,NODE3,NODE4,NODE5,NODE6,NODE7,NODE8,NODE9,NODE10,NODE11,NODE12,NODE13,NODE14,NODE15,NODE16,TOOL
 SG_ motor_temp : 40|8@1- (1,0) [-128|127] "degC"  MASTER,NODE1,NODE2,NODE3,NODE4,NODE5,NODE6,NODE7,NODE8,NODE9,NODE10,NODE11,NODE12,NODE13,NODE14,NODE15,NODE16,TOOL
 SG_ fault_flags : 48|8@1+ (1,0) [0|255] "bitfield"  MASTER,NODE1,NODE2,NODE3,NODE4,NODE5,NODE6,NODE7,NODE8,NODE9,NODE10,NODE11,NODE12,NODE13,NODE14,NODE15,NODE16,TOOL
 SG_ warning_flags : 56|8@1+ (1,0) [0|255] "bitfield"  MASTER,NODE1,NODE2,NODE3,NODE4,NODE5,NODE6,NODE7,NODE8,NODE9,NODE10,NODE11,NODE12,NODE13,NODE14,NODE15,NODE16,TOOL

BO_ 1047 S3_NODE_CMD_7: 8 MASTER
 SG_ node_command : 0|8@1+ (1,0) [0|255] ""  MASTER,NODE1,NODE2,NODE3,NODE4,NODE5,NODE6,NODE7,NODE8,NODE9,NODE10,NODE11,NODE12,NODE13,NODE14,NODE15,NODE16,TOOL
 SG_ node_flags : 8|8@1+ (1,0) [0|255] "bitfield"  MASTER,NODE1,NODE2,NODE3,NODE4,NODE5,NODE6,NODE7,NODE8,NODE9,NODE10,NODE11,NODE12,NODE13,NODE14,NODE15,NODE16,TOOL
 SG_ trim_rpm : 16|16@1- (0.1,0) [-3276.8|3276.7] "rpm"  MASTER,NODE1,NODE2,NODE3,NODE4,NODE5,NODE6,NODE7,NODE8,NODE9,NODE10,NODE11,NODE12,NODE13,NODE14,NODE15,NODE16,TOOL
 SG_ section_mask : 32|16@1+ (1,0) [0|65535] "bitmask"  MASTER,NODE1,NODE2,NODE3,NODE4,NODE5,NODE6,NODE7,NODE8,NODE9,NODE10,NODE11,NODE12,NODE13,NODE14,NODE15,NODE16,TOOL
 SG_ seq : 48|8@1+ (1,0) [0|255] ""  MASTER,NODE1,NODE2,NODE3,NODE4,NODE5,NODE6,NODE7,NODE8,NODE9,NODE10,NODE11,NODE12,NODE13,NODE14,NODE15,NODE16,TOOL
 SG_ reserved : 56|8@1+ (1,0) [0|255] ""  MASTER,NODE1,NODE2,NODE3,NODE4,NODE5,NODE6,NODE7,NODE8,NODE9,NODE10,NODE11,NODE12,NODE13,NODE14,NODE15,NODE16,TOOL

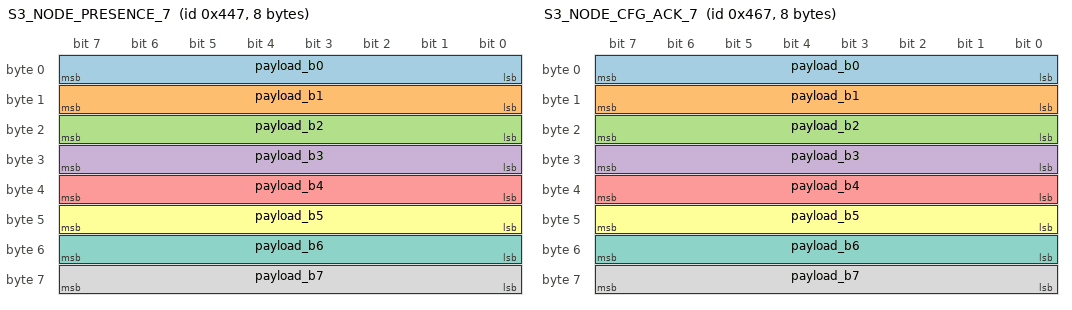
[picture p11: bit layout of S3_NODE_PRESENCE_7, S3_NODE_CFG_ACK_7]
BO_ 1095 S3_NODE_PRESENCE_7: 8 NODE7
 SG_ payload_b0 : 0|8@1+ (1,0) [0|255] "raw"  MASTER,NODE1,NODE2,NODE3,NODE4,NODE5,NODE6,NODE7,NODE8,NODE9,NODE10,NODE11,NODE12,NODE13,NODE14,NODE15,NODE16,TOOL
 SG_ payload_b1 : 8|8@1+ (1,0) [0|255] "raw"  MASTER,NODE1,NODE2,NODE3,NODE4,NODE5,NODE6,NODE7,NODE8,NODE9,NODE10,NODE11,NODE12,NODE13,NODE14,NODE15,NODE16,TOOL
 SG_ payload_b2 : 16|8@1+ (1,0) [0|255] "raw"  MASTER,NODE1,NODE2,NODE3,NODE4,NODE5,NODE6,NODE7,NODE8,NODE9,NODE10,NODE11,NODE12,NODE13,NODE14,NODE15,NODE16,TOOL
 SG_ payload_b3 : 24|8@1+ (1,0) [0|255] "raw"  MASTER,NODE1,NODE2,NODE3,NODE4,NODE5,NODE6,NODE7,NODE8,NODE9,NODE10,NODE11,NODE12,NODE13,NODE14,NODE15,NODE16,TOOL
 SG_ payload_b4 : 32|8@1+ (1,0) [0|255] "raw"  MASTER,NODE1,NODE2,NODE3,NODE4,NODE5,NODE6,NODE7,NODE8,NODE9,NODE10,NODE11,NODE12,NODE13,NODE14,NODE15,NODE16,TOOL
 SG_ payload_b5 : 40|8@1+ (1,0) [0|255] "raw"  MASTER,NODE1,NODE2,NODE3,NODE4,NODE5,NODE6,NODE7,NODE8,NODE9,NODE10,NODE11,NODE12,NODE13,NODE14,NODE15,NODE16,TOOL
 SG_ payload_b6 : 48|8@1+ (1,0) [0|255] "raw"  MASTER,NODE1,NODE2,NODE3,NODE4,NODE5,NODE6,NODE7,NODE8,NODE9,NODE10,NODE11,NODE12,NODE13,NODE14,NODE15,NODE16,TOOL
 SG_ payload_b7 : 56|8@1+ (1,0) [0|255] "raw"  MASTER,NODE1,NODE2,NODE3,NODE4,NODE5,NODE6,NODE7,NODE8,NODE9,NODE10,NODE11,NODE12,NODE13,NODE14,NODE15,NODE16,TOOL

BO_ 1127 S3_NODE_CFG_ACK_7: 8 NODE7
 SG_ payload_b0 : 0|8@1+ (1,0) [0|255] "raw"  MASTER,NODE1,NODE2,NODE3,NODE4,NODE5,NODE6,NODE7,NODE8,NODE9,NODE10,NODE11,NODE12,NODE13,NODE14,NODE15,NODE16,TOOL
 SG_ payload_b1 : 8|8@1+ (1,0) [0|255] "raw"  MASTER,NODE1,NODE2,NODE3,NODE4,NODE5,NODE6,NODE7,NODE8,NODE9,NODE10,NODE11,NODE12,NODE13,NODE14,NODE15,NODE16,TOOL
 SG_ payload_b2 : 16|8@1+ (1,0) [0|255] "raw"  MASTER,NODE1,NODE2,NODE3,NODE4,NODE5,NODE6,NODE7,NODE8,NODE9,NODE10,NODE11,NODE12,NODE13,NODE14,NODE15,NODE16,TOOL
 SG_ payload_b3 : 24|8@1+ (1,0) [0|255] "raw"  MASTER,NODE1,NODE2,NODE3,NODE4,NODE5,NODE6,NODE7,NODE8,NODE9,NODE10,NODE11,NODE12,NODE13,NODE14,NODE15,NODE16,TOOL
 SG_ payload_b4 : 32|8@1+ (1,0) [0|255] "raw"  MASTER,NODE1,NODE2,NODE3,NODE4,NODE5,NODE6,NODE7,NODE8,NODE9,NODE10,NODE11,NODE12,NODE13,NODE14,NODE15,NODE16,TOOL
 SG_ payload_b5 : 40|8@1+ (1,0) [0|255] "raw"  MASTER,NODE1,NODE2,NODE3,NODE4,NODE5,NODE6,NODE7,NODE8,NODE9,NODE10,NODE11,NODE12,NODE13,NODE14,NODE15,NODE16,TOOL
 SG_ payload_b6 : 48|8@1+ (1,0) [0|255] "raw"  MASTER,NODE1,NODE2,NODE3,NODE4,NODE5,NODE6,NODE7,NODE8,NODE9,NODE10,NODE11,NODE12,NODE13,NODE14,NODE15,NODE16,TOOL
 SG_ payload_b7 : 56|8@1+ (1,0) [0|255] "raw"  MASTER,NODE1,NODE2,NODE3,NODE4,NODE5,NODE6,NODE7,NODE8,NODE9,NODE10,NODE11,NODE12,NODE13,NODE14,NODE15,NODE16,TOOL

BO_ 1159 S3_NODE_STATUS_FAST_7: 8 NODE7
 SG_ status_flags : 0|8@1+ (1,0) [0|255] "bitfield"  MASTER,NODE1,NODE2,NODE3,NODE4,NODE5,NODE6,NODE7,NODE8,NODE9,NODE10,NODE11,NODE12,NODE13,NODE14,NODE15,NODE16,TOOL
 SG_ error_code : 8|8@1+ (1,0) [0|255] ""  MASTER,NODE1,NODE2,NODE3,NODE4,NODE5,NODE6,NODE7,NODE8,NODE9,NODE10,NODE11,NODE12,NODE13,NODE14,NODE15,NODE16,TOOL
 SG_ actual_rpm : 16|16@1+ (1,0) [0|10000] "rpm"  MASTER,NODE1,NODE2,NODE3,NODE4,NODE5,NODE6,NODE7,NODE8,NODE9,NODE10,NODE11,NODE12,NODE13,NODE14,NODE15,NODE16,TOOL
 SG_ actual_pos : 32|16@1+ (1.52587890625e-05,0) [0|0.9999847412109375] "rev"  MASTER,NODE1,NODE2,NODE3,NODE4,NODE5,NODE6,NODE7,NODE8,NODE9,NODE10,NODE11,NODE12,NODE13,NODE14,NODE15,NODE16,TOOL
 SG_ alive_counter : 48|8@1+ (1,0) [0|255] ""  MASTER,NODE1,NODE2,NODE3,NODE4,NODE5,NODE6,NODE7,NODE8,NODE9,NODE10,NODE11,NODE12,NODE13,NODE14,NODE15,NODE16,TOOL
 SG_ sync_error : 56|8@1- (0.00390625,0) [-0.5|0.49609375] "rev"  MASTER,NODE1,NODE2,NODE3,NODE4,NODE5,NODE6,NODE7,NODE8,NODE9,NODE10,NODE11,NODE12,NODE13,NODE14,NODE15,NODE16,TOOL

BO_ 1223 S3_NODE_DIAG_7: 8 NODE7
 SG_ bus_voltage : 0|16@1+ (0.1,0) [0|6553.5] "V"  MASTER,NODE1,NODE2,NODE3,NODE4,NODE5,NODE6,NODE7,NODE8,NODE9,NODE10,NODE11,NODE12,NODE13,NODE14,NODE15,NODE16,TOOL
 SG_ motor_current : 16|16@1- (0.1,0) [-3276.8|3276.7] "A"  MASTER,NODE1,NODE2,NODE3,NODE4,NODE5,NODE6,NODE7,NODE8,NODE9,NODE10,NODE11,NODE12,NODE13,NODE14,NODE15,NODE16,TOOL
 SG_ controller_temp : 32|8@1- (1,0) [-128|127] "degC"  MASTER,NODE1,NODE2,NODE3,NODE4,NODE5,NODE6,NODE7,NODE8,NODE9,NODE10,NODE11,NODE12,NODE13,NODE14,NODE15,NODE16,TOOL
 SG_ motor_temp : 40|8@1- (1,0) [-128|127] "degC"  MASTER,NODE1,NODE2,NODE3,NODE4,NODE5,NODE6,NODE7,NODE8,NODE9,NODE10,NODE11,NODE12,NODE13,NODE14,NODE15,NODE16,TOOL
 SG_ fault_flags : 48|8@1+ (1,0) [0|255] "bitfield"  MASTER,NODE1,NODE2,NODE3,NODE4,NODE5,NODE6,NODE7,NODE8,NODE9,NODE10,NODE11,NODE12,NODE13,NODE14,NODE15,NODE16,TOOL
 SG_ warning_flags : 56|8@1+ (1,0) [0|255] "bitfield"  MASTER,NODE1,NODE2,NODE3,NODE4,NODE5,NODE6,NODE7,NODE8,NODE9,NODE10,NODE11,NODE12,NODE13,NODE14,NODE15,NODE16,TOOL

BO_ 1048 S3_NODE_CMD_8: 8 MASTER
 SG_ node_command : 0|8@1+ (1,0) [0|255] ""  MASTER,NODE1,NODE2,NODE3,NODE4,NODE5,NODE6,NODE7,NODE8,NODE9,NODE10,NODE11,NODE12,NODE13,NODE14,NODE15,NODE16,TOOL
 SG_ node_flags : 8|8@1+ (1,0) [0|255] "bitfield"  MASTER,NODE1,NODE2,NODE3,NODE4,NODE5,NODE6,NODE7,NODE8,NODE9,NODE10,NODE11,NODE12,NODE13,NODE14,NODE15,NODE16,TOOL
 SG_ trim_rpm : 16|16@1- (0.1,0) [-3276.8|3276.7] "rpm"  MASTER,NODE1,NODE2,NODE3,NODE4,NODE5,NODE6,NODE7,NODE8,NODE9,NODE10,NODE11,NODE12,NODE13,NODE14,NODE15,NODE16,TOOL
 SG_ section_mask : 32|16@1+ (1,0) [0|65535] "bitmask"  MASTER,NODE1,NODE2,NODE3,NODE4,NODE5,NODE6,NODE7,NODE8,NODE9,NODE10,NODE11,NODE12,NODE13,NODE14,NODE15,NODE16,TOOL
 SG_ seq : 48|8@1+ (1,0) [0|255] ""  MASTER,NODE1,NODE2,NODE3,NODE4,NODE5,NODE6,NODE7,NODE8,NODE9,NODE10,NODE11,NODE12,NODE13,NODE14,NODE15,NODE16,TOOL
 SG_ reserved : 56|8@1+ (1,0) [0|255] ""  MASTER,NODE1,NODE2,NODE3,NODE4,NODE5,NODE6,NODE7,NODE8,NODE9,NODE10,NODE11,NODE12,NODE13,NODE14,NODE15,NODE16,TOOL

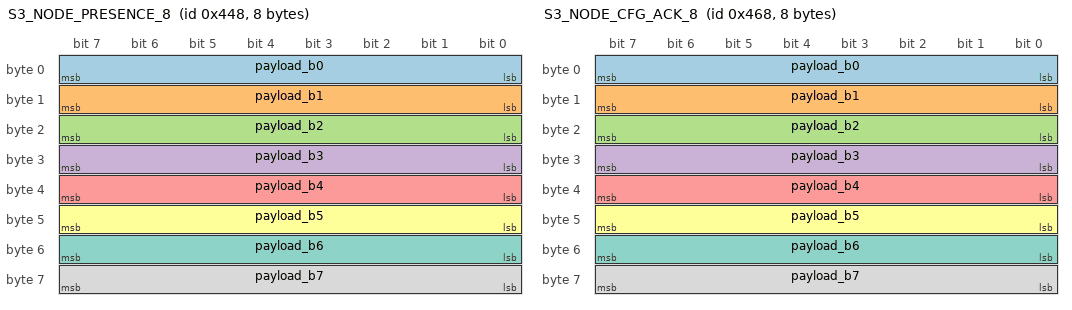
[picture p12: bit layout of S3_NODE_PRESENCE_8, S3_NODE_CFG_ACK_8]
BO_ 1096 S3_NODE_PRESENCE_8: 8 NODE8
 SG_ payload_b0 : 0|8@1+ (1,0) [0|255] "raw"  MASTER,NODE1,NODE2,NODE3,NODE4,NODE5,NODE6,NODE7,NODE8,NODE9,NODE10,NODE11,NODE12,NODE13,NODE14,NODE15,NODE16,TOOL
 SG_ payload_b1 : 8|8@1+ (1,0) [0|255] "raw"  MASTER,NODE1,NODE2,NODE3,NODE4,NODE5,NODE6,NODE7,NODE8,NODE9,NODE10,NODE11,NODE12,NODE13,NODE14,NODE15,NODE16,TOOL
 SG_ payload_b2 : 16|8@1+ (1,0) [0|255] "raw"  MASTER,NODE1,NODE2,NODE3,NODE4,NODE5,NODE6,NODE7,NODE8,NODE9,NODE10,NODE11,NODE12,NODE13,NODE14,NODE15,NODE16,TOOL
 SG_ payload_b3 : 24|8@1+ (1,0) [0|255] "raw"  MASTER,NODE1,NODE2,NODE3,NODE4,NODE5,NODE6,NODE7,NODE8,NODE9,NODE10,NODE11,NODE12,NODE13,NODE14,NODE15,NODE16,TOOL
 SG_ payload_b4 : 32|8@1+ (1,0) [0|255] "raw"  MASTER,NODE1,NODE2,NODE3,NODE4,NODE5,NODE6,NODE7,NODE8,NODE9,NODE10,NODE11,NODE12,NODE13,NODE14,NODE15,NODE16,TOOL
 SG_ payload_b5 : 40|8@1+ (1,0) [0|255] "raw"  MASTER,NODE1,NODE2,NODE3,NODE4,NODE5,NODE6,NODE7,NODE8,NODE9,NODE10,NODE11,NODE12,NODE13,NODE14,NODE15,NODE16,TOOL
 SG_ payload_b6 : 48|8@1+ (1,0) [0|255] "raw"  MASTER,NODE1,NODE2,NODE3,NODE4,NODE5,NODE6,NODE7,NODE8,NODE9,NODE10,NODE11,NODE12,NODE13,NODE14,NODE15,NODE16,TOOL
 SG_ payload_b7 : 56|8@1+ (1,0) [0|255] "raw"  MASTER,NODE1,NODE2,NODE3,NODE4,NODE5,NODE6,NODE7,NODE8,NODE9,NODE10,NODE11,NODE12,NODE13,NODE14,NODE15,NODE16,TOOL

BO_ 1128 S3_NODE_CFG_ACK_8: 8 NODE8
 SG_ payload_b0 : 0|8@1+ (1,0) [0|255] "raw"  MASTER,NODE1,NODE2,NODE3,NODE4,NODE5,NODE6,NODE7,NODE8,NODE9,NODE10,NODE11,NODE12,NODE13,NODE14,NODE15,NODE16,TOOL
 SG_ payload_b1 : 8|8@1+ (1,0) [0|255] "raw"  MASTER,NODE1,NODE2,NODE3,NODE4,NODE5,NODE6,NODE7,NODE8,NODE9,NODE10,NODE11,NODE12,NODE13,NODE14,NODE15,NODE16,TOOL
 SG_ payload_b2 : 16|8@1+ (1,0) [0|255] "raw"  MASTER,NODE1,NODE2,NODE3,NODE4,NODE5,NODE6,NODE7,NODE8,NODE9,NODE10,NODE11,NODE12,NODE13,NODE14,NODE15,NODE16,TOOL
 SG_ payload_b3 : 24|8@1+ (1,0) [0|255] "raw"  MASTER,NODE1,NODE2,NODE3,NODE4,NODE5,NODE6,NODE7,NODE8,NODE9,NODE10,NODE11,NODE12,NODE13,NODE14,NODE15,NODE16,TOOL
 SG_ payload_b4 : 32|8@1+ (1,0) [0|255] "raw"  MASTER,NODE1,NODE2,NODE3,NODE4,NODE5,NODE6,NODE7,NODE8,NODE9,NODE10,NODE11,NODE12,NODE13,NODE14,NODE15,NODE16,TOOL
 SG_ payload_b5 : 40|8@1+ (1,0) [0|255] "raw"  MASTER,NODE1,NODE2,NODE3,NODE4,NODE5,NODE6,NODE7,NODE8,NODE9,NODE10,NODE11,NODE12,NODE13,NODE14,NODE15,NODE16,TOOL
 SG_ payload_b6 : 48|8@1+ (1,0) [0|255] "raw"  MASTER,NODE1,NODE2,NODE3,NODE4,NODE5,NODE6,NODE7,NODE8,NODE9,NODE10,NODE11,NODE12,NODE13,NODE14,NODE15,NODE16,TOOL
 SG_ payload_b7 : 56|8@1+ (1,0) [0|255] "raw"  MASTER,NODE1,NODE2,NODE3,NODE4,NODE5,NODE6,NODE7,NODE8,NODE9,NODE10,NODE11,NODE12,NODE13,NODE14,NODE15,NODE16,TOOL

BO_ 1160 S3_NODE_STATUS_FAST_8: 8 NODE8
 SG_ status_flags : 0|8@1+ (1,0) [0|255] "bitfield"  MASTER,NODE1,NODE2,NODE3,NODE4,NODE5,NODE6,NODE7,NODE8,NODE9,NODE10,NODE11,NODE12,NODE13,NODE14,NODE15,NODE16,TOOL
 SG_ error_code : 8|8@1+ (1,0) [0|255] ""  MASTER,NODE1,NODE2,NODE3,NODE4,NODE5,NODE6,NODE7,NODE8,NODE9,NODE10,NODE11,NODE12,NODE13,NODE14,NODE15,NODE16,TOOL
 SG_ actual_rpm : 16|16@1+ (1,0) [0|10000] "rpm"  MASTER,NODE1,NODE2,NODE3,NODE4,NODE5,NODE6,NODE7,NODE8,NODE9,NODE10,NODE11,NODE12,NODE13,NODE14,NODE15,NODE16,TOOL
 SG_ actual_pos : 32|16@1+ (1.52587890625e-05,0) [0|0.9999847412109375] "rev"  MASTER,NODE1,NODE2,NODE3,NODE4,NODE5,NODE6,NODE7,NODE8,NODE9,NODE10,NODE11,NODE12,NODE13,NODE14,NODE15,NODE16,TOOL
 SG_ alive_counter : 48|8@1+ (1,0) [0|255] ""  MASTER,NODE1,NODE2,NODE3,NODE4,NODE5,NODE6,NODE7,NODE8,NODE9,NODE10,NODE11,NODE12,NODE13,NODE14,NODE15,NODE16,TOOL
 SG_ sync_error : 56|8@1- (0.00390625,0) [-0.5|0.49609375] "rev"  MASTER,NODE1,NODE2,NODE3,NODE4,NODE5,NODE6,NODE7,NODE8,NODE9,NODE10,NODE11,NODE12,NODE13,NODE14,NODE15,NODE16,TOOL

BO_ 1224 S3_NODE_DIAG_8: 8 NODE8
 SG_ bus_voltage : 0|16@1+ (0.1,0) [0|6553.5] "V"  MASTER,NODE1,NODE2,NODE3,NODE4,NODE5,NODE6,NODE7,NODE8,NODE9,NODE10,NODE11,NODE12,NODE13,NODE14,NODE15,NODE16,TOOL
 SG_ motor_current : 16|16@1- (0.1,0) [-3276.8|3276.7] "A"  MASTER,NODE1,NODE2,NODE3,NODE4,NODE5,NODE6,NODE7,NODE8,NODE9,NODE10,NODE11,NODE12,NODE13,NODE14,NODE15,NODE16,TOOL
 SG_ controller_temp : 32|8@1- (1,0) [-128|127] "degC"  MASTER,NODE1,NODE2,NODE3,NODE4,NODE5,NODE6,NODE7,NODE8,NODE9,NODE10,NODE11,NODE12,NODE13,NODE14,NODE15,NODE16,TOOL
 SG_ motor_temp : 40|8@1- (1,0) [-128|127] "degC"  MASTER,NODE1,NODE2,NODE3,NODE4,NODE5,NODE6,NODE7,NODE8,NODE9,NODE10,NODE11,NODE12,NODE13,NODE14,NODE15,NODE16,TOOL
 SG_ fault_flags : 48|8@1+ (1,0) [0|255] "bitfield"  MASTER,NODE1,NODE2,NODE3,NODE4,NODE5,NODE6,NODE7,NODE8,NODE9,NODE10,NODE11,NODE12,NODE13,NODE14,NODE15,NODE16,TOOL
 SG_ warning_flags : 56|8@1+ (1,0) [0|255] "bitfield"  MASTER,NODE1,NODE2,NODE3,NODE4,NODE5,NODE6,NODE7,NODE8,NODE9,NODE10,NODE11,NODE12,NODE13,NODE14,NODE15,NODE16,TOOL

BO_ 1049 S3_NODE_CMD_9: 8 MASTER
 SG_ node_command : 0|8@1+ (1,0) [0|255] ""  MASTER,NODE1,NODE2,NODE3,NODE4,NODE5,NODE6,NODE7,NODE8,NODE9,NODE10,NODE11,NODE12,NODE13,NODE14,NODE15,NODE16,TOOL
 SG_ node_flags : 8|8@1+ (1,0) [0|255] "bitfield"  MASTER,NODE1,NODE2,NODE3,NODE4,NODE5,NODE6,NODE7,NODE8,NODE9,NODE10,NODE11,NODE12,NODE13,NODE14,NODE15,NODE16,TOOL
 SG_ trim_rpm : 16|16@1- (0.1,0) [-3276.8|3276.7] "rpm"  MASTER,NODE1,NODE2,NODE3,NODE4,NODE5,NODE6,NODE7,NODE8,NODE9,NODE10,NODE11,NODE12,NODE13,NODE14,NODE15,NODE16,TOOL
 SG_ section_mask : 32|16@1+ (1,0) [0|65535] "bitmask"  MASTER,NODE1,NODE2,NODE3,NODE4,NODE5,NODE6,NODE7,NODE8,NODE9,NODE10,NODE11,NODE12,NODE13,NODE14,NODE15,NODE16,TOOL
 SG_ seq : 48|8@1+ (1,0) [0|255] ""  MASTER,NODE1,NODE2,NODE3,NODE4,NODE5,NODE6,NODE7,NODE8,NODE9,NODE10,NODE11,NODE12,NODE13,NODE14,NODE15,NODE16,TOOL
 SG_ reserved : 56|8@1+ (1,0) [0|255] ""  MASTER,NODE1,NODE2,NODE3,NODE4,NODE5,NODE6,NODE7,NODE8,NODE9,NODE10,NODE11,NODE12,NODE13,NODE14,NODE15,NODE16,TOOL

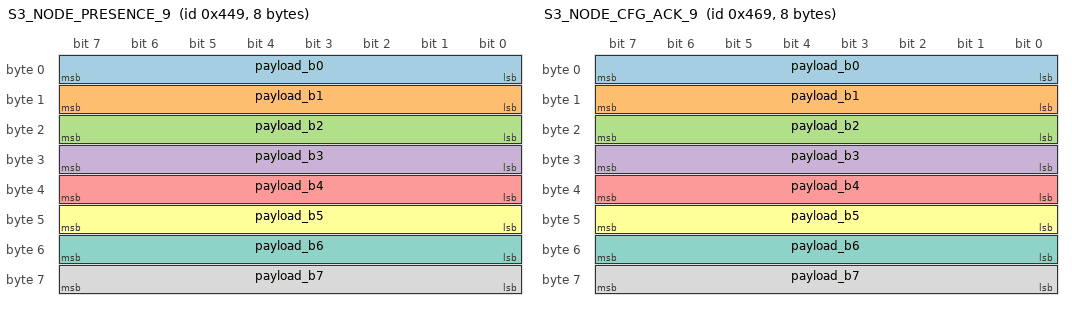
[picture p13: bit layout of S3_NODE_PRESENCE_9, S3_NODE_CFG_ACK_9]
BO_ 1097 S3_NODE_PRESENCE_9: 8 NODE9
 SG_ payload_b0 : 0|8@1+ (1,0) [0|255] "raw"  MASTER,NODE1,NODE2,NODE3,NODE4,NODE5,NODE6,NODE7,NODE8,NODE9,NODE10,NODE11,NODE12,NODE13,NODE14,NODE15,NODE16,TOOL
 SG_ payload_b1 : 8|8@1+ (1,0) [0|255] "raw"  MASTER,NODE1,NODE2,NODE3,NODE4,NODE5,NODE6,NODE7,NODE8,NODE9,NODE10,NODE11,NODE12,NODE13,NODE14,NODE15,NODE16,TOOL
 SG_ payload_b2 : 16|8@1+ (1,0) [0|255] "raw"  MASTER,NODE1,NODE2,NODE3,NODE4,NODE5,NODE6,NODE7,NODE8,NODE9,NODE10,NODE11,NODE12,NODE13,NODE14,NODE15,NODE16,TOOL
 SG_ payload_b3 : 24|8@1+ (1,0) [0|255] "raw"  MASTER,NODE1,NODE2,NODE3,NODE4,NODE5,NODE6,NODE7,NODE8,NODE9,NODE10,NODE11,NODE12,NODE13,NODE14,NODE15,NODE16,TOOL
 SG_ payload_b4 : 32|8@1+ (1,0) [0|255] "raw"  MASTER,NODE1,NODE2,NODE3,NODE4,NODE5,NODE6,NODE7,NODE8,NODE9,NODE10,NODE11,NODE12,NODE13,NODE14,NODE15,NODE16,TOOL
 SG_ payload_b5 : 40|8@1+ (1,0) [0|255] "raw"  MASTER,NODE1,NODE2,NODE3,NODE4,NODE5,NODE6,NODE7,NODE8,NODE9,NODE10,NODE11,NODE12,NODE13,NODE14,NODE15,NODE16,TOOL
 SG_ payload_b6 : 48|8@1+ (1,0) [0|255] "raw"  MASTER,NODE1,NODE2,NODE3,NODE4,NODE5,NODE6,NODE7,NODE8,NODE9,NODE10,NODE11,NODE12,NODE13,NODE14,NODE15,NODE16,TOOL
 SG_ payload_b7 : 56|8@1+ (1,0) [0|255] "raw"  MASTER,NODE1,NODE2,NODE3,NODE4,NODE5,NODE6,NODE7,NODE8,NODE9,NODE10,NODE11,NODE12,NODE13,NODE14,NODE15,NODE16,TOOL

BO_ 1129 S3_NODE_CFG_ACK_9: 8 NODE9
 SG_ payload_b0 : 0|8@1+ (1,0) [0|255] "raw"  MASTER,NODE1,NODE2,NODE3,NODE4,NODE5,NODE6,NODE7,NODE8,NODE9,NODE10,NODE11,NODE12,NODE13,NODE14,NODE15,NODE16,TOOL
 SG_ payload_b1 : 8|8@1+ (1,0) [0|255] "raw"  MASTER,NODE1,NODE2,NODE3,NODE4,NODE5,NODE6,NODE7,NODE8,NODE9,NODE10,NODE11,NODE12,NODE13,NODE14,NODE15,NODE16,TOOL
 SG_ payload_b2 : 16|8@1+ (1,0) [0|255] "raw"  MASTER,NODE1,NODE2,NODE3,NODE4,NODE5,NODE6,NODE7,NODE8,NODE9,NODE10,NODE11,NODE12,NODE13,NODE14,NODE15,NODE16,TOOL
 SG_ payload_b3 : 24|8@1+ (1,0) [0|255] "raw"  MASTER,NODE1,NODE2,NODE3,NODE4,NODE5,NODE6,NODE7,NODE8,NODE9,NODE10,NODE11,NODE12,NODE13,NODE14,NODE15,NODE16,TOOL
 SG_ payload_b4 : 32|8@1+ (1,0) [0|255] "raw"  MASTER,NODE1,NODE2,NODE3,NODE4,NODE5,NODE6,NODE7,NODE8,NODE9,NODE10,NODE11,NODE12,NODE13,NODE14,NODE15,NODE16,TOOL
 SG_ payload_b5 : 40|8@1+ (1,0) [0|255] "raw"  MASTER,NODE1,NODE2,NODE3,NODE4,NODE5,NODE6,NODE7,NODE8,NODE9,NODE10,NODE11,NODE12,NODE13,NODE14,NODE15,NODE16,TOOL
 SG_ payload_b6 : 48|8@1+ (1,0) [0|255] "raw"  MASTER,NODE1,NODE2,NODE3,NODE4,NODE5,NODE6,NODE7,NODE8,NODE9,NODE10,NODE11,NODE12,NODE13,NODE14,NODE15,NODE16,TOOL
 SG_ payload_b7 : 56|8@1+ (1,0) [0|255] "raw"  MASTER,NODE1,NODE2,NODE3,NODE4,NODE5,NODE6,NODE7,NODE8,NODE9,NODE10,NODE11,NODE12,NODE13,NODE14,NODE15,NODE16,TOOL

BO_ 1161 S3_NODE_STATUS_FAST_9: 8 NODE9
 SG_ status_flags : 0|8@1+ (1,0) [0|255] "bitfield"  MASTER,NODE1,NODE2,NODE3,NODE4,NODE5,NODE6,NODE7,NODE8,NODE9,NODE10,NODE11,NODE12,NODE13,NODE14,NODE15,NODE16,TOOL
 SG_ error_code : 8|8@1+ (1,0) [0|255] ""  MASTER,NODE1,NODE2,NODE3,NODE4,NODE5,NODE6,NODE7,NODE8,NODE9,NODE10,NODE11,NODE12,NODE13,NODE14,NODE15,NODE16,TOOL
 SG_ actual_rpm : 16|16@1+ (1,0) [0|10000] "rpm"  MASTER,NODE1,NODE2,NODE3,NODE4,NODE5,NODE6,NODE7,NODE8,NODE9,NODE10,NODE11,NODE12,NODE13,NODE14,NODE15,NODE16,TOOL
 SG_ actual_pos : 32|16@1+ (1.52587890625e-05,0) [0|0.9999847412109375] "rev"  MASTER,NODE1,NODE2,NODE3,NODE4,NODE5,NODE6,NODE7,NODE8,NODE9,NODE10,NODE11,NODE12,NODE13,NODE14,NODE15,NODE16,TOOL
 SG_ alive_counter : 48|8@1+ (1,0) [0|255] ""  MASTER,NODE1,NODE2,NODE3,NODE4,NODE5,NODE6,NODE7,NODE8,NODE9,NODE10,NODE11,NODE12,NODE13,NODE14,NODE15,NODE16,TOOL
 SG_ sync_error : 56|8@1- (0.00390625,0) [-0.5|0.49609375] "rev"  MASTER,NODE1,NODE2,NODE3,NODE4,NODE5,NODE6,NODE7,NODE8,NODE9,NODE10,NODE11,NODE12,NODE13,NODE14,NODE15,NODE16,TOOL

BO_ 1225 S3_NODE_DIAG_9: 8 NODE9
 SG_ bus_voltage : 0|16@1+ (0.1,0) [0|6553.5] "V"  MASTER,NODE1,NODE2,NODE3,NODE4,NODE5,NODE6,NODE7,NODE8,NODE9,NODE10,NODE11,NODE12,NODE13,NODE14,NODE15,NODE16,TOOL
 SG_ motor_current : 16|16@1- (0.1,0) [-3276.8|3276.7] "A"  MASTER,NODE1,NODE2,NODE3,NODE4,NODE5,NODE6,NODE7,NODE8,NODE9,NODE10,NODE11,NODE12,NODE13,NODE14,NODE15,NODE16,TOOL
 SG_ controller_temp : 32|8@1- (1,0) [-128|127] "degC"  MASTER,NODE1,NODE2,NODE3,NODE4,NODE5,NODE6,NODE7,NODE8,NODE9,NODE10,NODE11,NODE12,NODE13,NODE14,NODE15,NODE16,TOOL
 SG_ motor_temp : 40|8@1- (1,0) [-128|127] "degC"  MASTER,NODE1,NODE2,NODE3,NODE4,NODE5,NODE6,NODE7,NODE8,NODE9,NODE10,NODE11,NODE12,NODE13,NODE14,NODE15,NODE16,TOOL
 SG_ fault_flags : 48|8@1+ (1,0) [0|255] "bitfield"  MASTER,NODE1,NODE2,NODE3,NODE4,NODE5,NODE6,NODE7,NODE8,NODE9,NODE10,NODE11,NODE12,NODE13,NODE14,NODE15,NODE16,TOOL
 SG_ warning_flags : 56|8@1+ (1,0) [0|255] "bitfield"  MASTER,NODE1,NODE2,NODE3,NODE4,NODE5,NODE6,NODE7,NODE8,NODE9,NODE10,NODE11,NODE12,NODE13,NODE14,NODE15,NODE16,TOOL

BO_ 1050 S3_NODE_CMD_10: 8 MASTER
 SG_ node_command : 0|8@1+ (1,0) [0|255] ""  MASTER,NODE1,NODE2,NODE3,NODE4,NODE5,NODE6,NODE7,NODE8,NODE9,NODE10,NODE11,NODE12,NODE13,NODE14,NODE15,NODE16,TOOL
 SG_ node_flags : 8|8@1+ (1,0) [0|255] "bitfield"  MASTER,NODE1,NODE2,NODE3,NODE4,NODE5,NODE6,NODE7,NODE8,NODE9,NODE10,NODE11,NODE12,NODE13,NODE14,NODE15,NODE16,TOOL
 SG_ trim_rpm : 16|16@1- (0.1,0) [-3276.8|3276.7] "rpm"  MASTER,NODE1,NODE2,NODE3,NODE4,NODE5,NODE6,NODE7,NODE8,NODE9,NODE10,NODE11,NODE12,NODE13,NODE14,NODE15,NODE16,TOOL
 SG_ section_mask : 32|16@1+ (1,0) [0|65535] "bitmask"  MASTER,NODE1,NODE2,NODE3,NODE4,NODE5,NODE6,NODE7,NODE8,NODE9,NODE10,NODE11,NODE12,NODE13,NODE14,NODE15,NODE16,TOOL
 SG_ seq : 48|8@1+ (1,0) [0|255] ""  MASTER,NODE1,NODE2,NODE3,NODE4,NODE5,NODE6,NODE7,NODE8,NODE9,NODE10,NODE11,NODE12,NODE13,NODE14,NODE15,NODE16,TOOL
 SG_ reserved : 56|8@1+ (1,0) [0|255] ""  MASTER,NODE1,NODE2,NODE3,NODE4,NODE5,NODE6,NODE7,NODE8,NODE9,NODE10,NODE11,NODE12,NODE13,NODE14,NODE15,NODE16,TOOL

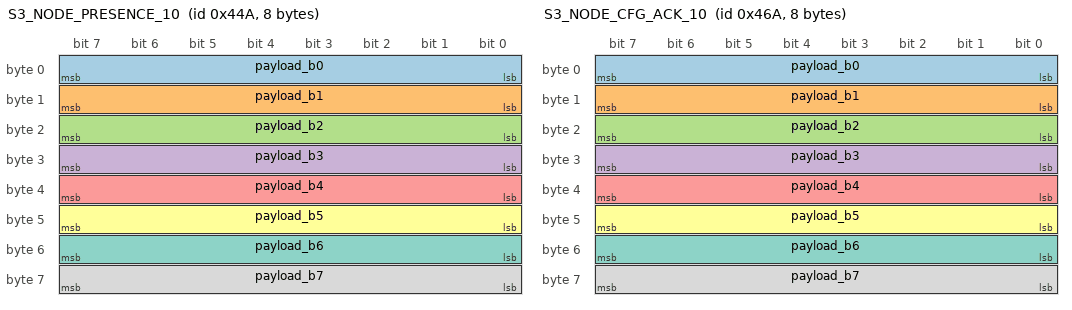
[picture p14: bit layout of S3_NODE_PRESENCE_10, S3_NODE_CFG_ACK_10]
BO_ 1098 S3_NODE_PRESENCE_10: 8 NODE10
 SG_ payload_b0 : 0|8@1+ (1,0) [0|255] "raw"  MASTER,NODE1,NODE2,NODE3,NODE4,NODE5,NODE6,NODE7,NODE8,NODE9,NODE10,NODE11,NODE12,NODE13,NODE14,NODE15,NODE16,TOOL
 SG_ payload_b1 : 8|8@1+ (1,0) [0|255] "raw"  MASTER,NODE1,NODE2,NODE3,NODE4,NODE5,NODE6,NODE7,NODE8,NODE9,NODE10,NODE11,NODE12,NODE13,NODE14,NODE15,NODE16,TOOL
 SG_ payload_b2 : 16|8@1+ (1,0) [0|255] "raw"  MASTER,NODE1,NODE2,NODE3,NODE4,NODE5,NODE6,NODE7,NODE8,NODE9,NODE10,NODE11,NODE12,NODE13,NODE14,NODE15,NODE16,TOOL
 SG_ payload_b3 : 24|8@1+ (1,0) [0|255] "raw"  MASTER,NODE1,NODE2,NODE3,NODE4,NODE5,NODE6,NODE7,NODE8,NODE9,NODE10,NODE11,NODE12,NODE13,NODE14,NODE15,NODE16,TOOL
 SG_ payload_b4 : 32|8@1+ (1,0) [0|255] "raw"  MASTER,NODE1,NODE2,NODE3,NODE4,NODE5,NODE6,NODE7,NODE8,NODE9,NODE10,NODE11,NODE12,NODE13,NODE14,NODE15,NODE16,TOOL
 SG_ payload_b5 : 40|8@1+ (1,0) [0|255] "raw"  MASTER,NODE1,NODE2,NODE3,NODE4,NODE5,NODE6,NODE7,NODE8,NODE9,NODE10,NODE11,NODE12,NODE13,NODE14,NODE15,NODE16,TOOL
 SG_ payload_b6 : 48|8@1+ (1,0) [0|255] "raw"  MASTER,NODE1,NODE2,NODE3,NODE4,NODE5,NODE6,NODE7,NODE8,NODE9,NODE10,NODE11,NODE12,NODE13,NODE14,NODE15,NODE16,TOOL
 SG_ payload_b7 : 56|8@1+ (1,0) [0|255] "raw"  MASTER,NODE1,NODE2,NODE3,NODE4,NODE5,NODE6,NODE7,NODE8,NODE9,NODE10,NODE11,NODE12,NODE13,NODE14,NODE15,NODE16,TOOL

BO_ 1130 S3_NODE_CFG_ACK_10: 8 NODE10
 SG_ payload_b0 : 0|8@1+ (1,0) [0|255] "raw"  MASTER,NODE1,NODE2,NODE3,NODE4,NODE5,NODE6,NODE7,NODE8,NODE9,NODE10,NODE11,NODE12,NODE13,NODE14,NODE15,NODE16,TOOL
 SG_ payload_b1 : 8|8@1+ (1,0) [0|255] "raw"  MASTER,NODE1,NODE2,NODE3,NODE4,NODE5,NODE6,NODE7,NODE8,NODE9,NODE10,NODE11,NODE12,NODE13,NODE14,NODE15,NODE16,TOOL
 SG_ payload_b2 : 16|8@1+ (1,0) [0|255] "raw"  MASTER,NODE1,NODE2,NODE3,NODE4,NODE5,NODE6,NODE7,NODE8,NODE9,NODE10,NODE11,NODE12,NODE13,NODE14,NODE15,NODE16,TOOL
 SG_ payload_b3 : 24|8@1+ (1,0) [0|255] "raw"  MASTER,NODE1,NODE2,NODE3,NODE4,NODE5,NODE6,NODE7,NODE8,NODE9,NODE10,NODE11,NODE12,NODE13,NODE14,NODE15,NODE16,TOOL
 SG_ payload_b4 : 32|8@1+ (1,0) [0|255] "raw"  MASTER,NODE1,NODE2,NODE3,NODE4,NODE5,NODE6,NODE7,NODE8,NODE9,NODE10,NODE11,NODE12,NODE13,NODE14,NODE15,NODE16,TOOL
 SG_ payload_b5 : 40|8@1+ (1,0) [0|255] "raw"  MASTER,NODE1,NODE2,NODE3,NODE4,NODE5,NODE6,NODE7,NODE8,NODE9,NODE10,NODE11,NODE12,NODE13,NODE14,NODE15,NODE16,TOOL
 SG_ payload_b6 : 48|8@1+ (1,0) [0|255] "raw"  MASTER,NODE1,NODE2,NODE3,NODE4,NODE5,NODE6,NODE7,NODE8,NODE9,NODE10,NODE11,NODE12,NODE13,NODE14,NODE15,NODE16,TOOL
 SG_ payload_b7 : 56|8@1+ (1,0) [0|255] "raw"  MASTER,NODE1,NODE2,NODE3,NODE4,NODE5,NODE6,NODE7,NODE8,NODE9,NODE10,NODE11,NODE12,NODE13,NODE14,NODE15,NODE16,TOOL

BO_ 1162 S3_NODE_STATUS_FAST_10: 8 NODE10
 SG_ status_flags : 0|8@1+ (1,0) [0|255] "bitfield"  MASTER,NODE1,NODE2,NODE3,NODE4,NODE5,NODE6,NODE7,NODE8,NODE9,NODE10,NODE11,NODE12,NODE13,NODE14,NODE15,NODE16,TOOL
 SG_ error_code : 8|8@1+ (1,0) [0|255] ""  MASTER,NODE1,NODE2,NODE3,NODE4,NODE5,NODE6,NODE7,NODE8,NODE9,NODE10,NODE11,NODE12,NODE13,NODE14,NODE15,NODE16,TOOL
 SG_ actual_rpm : 16|16@1+ (1,0) [0|10000] "rpm"  MASTER,NODE1,NODE2,NODE3,NODE4,NODE5,NODE6,NODE7,NODE8,NODE9,NODE10,NODE11,NODE12,NODE13,NODE14,NODE15,NODE16,TOOL
 SG_ actual_pos : 32|16@1+ (1.52587890625e-05,0) [0|0.9999847412109375] "rev"  MASTER,NODE1,NODE2,NODE3,NODE4,NODE5,NODE6,NODE7,NODE8,NODE9,NODE10,NODE11,NODE12,NODE13,NODE14,NODE15,NODE16,TOOL
 SG_ alive_counter : 48|8@1+ (1,0) [0|255] ""  MASTER,NODE1,NODE2,NODE3,NODE4,NODE5,NODE6,NODE7,NODE8,NODE9,NODE10,NODE11,NODE12,NODE13,NODE14,NODE15,NODE16,TOOL
 SG_ sync_error : 56|8@1- (0.00390625,0) [-0.5|0.49609375] "rev"  MASTER,NODE1,NODE2,NODE3,NODE4,NODE5,NODE6,NODE7,NODE8,NODE9,NODE10,NODE11,NODE12,NODE13,NODE14,NODE15,NODE16,TOOL

BO_ 1226 S3_NODE_DIAG_10: 8 NODE10
 SG_ bus_voltage : 0|16@1+ (0.1,0) [0|6553.5] "V"  MASTER,NODE1,NODE2,NODE3,NODE4,NODE5,NODE6,NODE7,NODE8,NODE9,NODE10,NODE11,NODE12,NODE13,NODE14,NODE15,NODE16,TOOL
 SG_ motor_current : 16|16@1- (0.1,0) [-3276.8|3276.7] "A"  MASTER,NODE1,NODE2,NODE3,NODE4,NODE5,NODE6,NODE7,NODE8,NODE9,NODE10,NODE11,NODE12,NODE13,NODE14,NODE15,NODE16,TOOL
 SG_ controller_temp : 32|8@1- (1,0) [-128|127] "degC"  MASTER,NODE1,NODE2,NODE3,NODE4,NODE5,NODE6,NODE7,NODE8,NODE9,NODE10,NODE11,NODE12,NODE13,NODE14,NODE15,NODE16,TOOL
 SG_ motor_temp : 40|8@1- (1,0) [-128|127] "degC"  MASTER,NODE1,NODE2,NODE3,NODE4,NODE5,NODE6,NODE7,NODE8,NODE9,NODE10,NODE11,NODE12,NODE13,NODE14,NODE15,NODE16,TOOL
 SG_ fault_flags : 48|8@1+ (1,0) [0|255] "bitfield"  MASTER,NODE1,NODE2,NODE3,NODE4,NODE5,NODE6,NODE7,NODE8,NODE9,NODE10,NODE11,NODE12,NODE13,NODE14,NODE15,NODE16,TOOL
 SG_ warning_flags : 56|8@1+ (1,0) [0|255] "bitfield"  MASTER,NODE1,NODE2,NODE3,NODE4,NODE5,NODE6,NODE7,NODE8,NODE9,NODE10,NODE11,NODE12,NODE13,NODE14,NODE15,NODE16,TOOL

BO_ 1051 S3_NODE_CMD_11: 8 MASTER
 SG_ node_command : 0|8@1+ (1,0) [0|255] ""  MASTER,NODE1,NODE2,NODE3,NODE4,NODE5,NODE6,NODE7,NODE8,NODE9,NODE10,NODE11,NODE12,NODE13,NODE14,NODE15,NODE16,TOOL
 SG_ node_flags : 8|8@1+ (1,0) [0|255] "bitfield"  MASTER,NODE1,NODE2,NODE3,NODE4,NODE5,NODE6,NODE7,NODE8,NODE9,NODE10,NODE11,NODE12,NODE13,NODE14,NODE15,NODE16,TOOL
 SG_ trim_rpm : 16|16@1- (0.1,0) [-3276.8|3276.7] "rpm"  MASTER,NODE1,NODE2,NODE3,NODE4,NODE5,NODE6,NODE7,NODE8,NODE9,NODE10,NODE11,NODE12,NODE13,NODE14,NODE15,NODE16,TOOL
 SG_ section_mask : 32|16@1+ (1,0) [0|65535] "bitmask"  MASTER,NODE1,NODE2,NODE3,NODE4,NODE5,NODE6,NODE7,NODE8,NODE9,NODE10,NODE11,NODE12,NODE13,NODE14,NODE15,NODE16,TOOL
 SG_ seq : 48|8@1+ (1,0) [0|255] ""  MASTER,NODE1,NODE2,NODE3,NODE4,NODE5,NODE6,NODE7,NODE8,NODE9,NODE10,NODE11,NODE12,NODE13,NODE14,NODE15,NODE16,TOOL
 SG_ reserved : 56|8@1+ (1,0) [0|255] ""  MASTER,NODE1,NODE2,NODE3,NODE4,NODE5,NODE6,NODE7,NODE8,NODE9,NODE10,NODE11,NODE12,NODE13,NODE14,NODE15,NODE16,TOOL

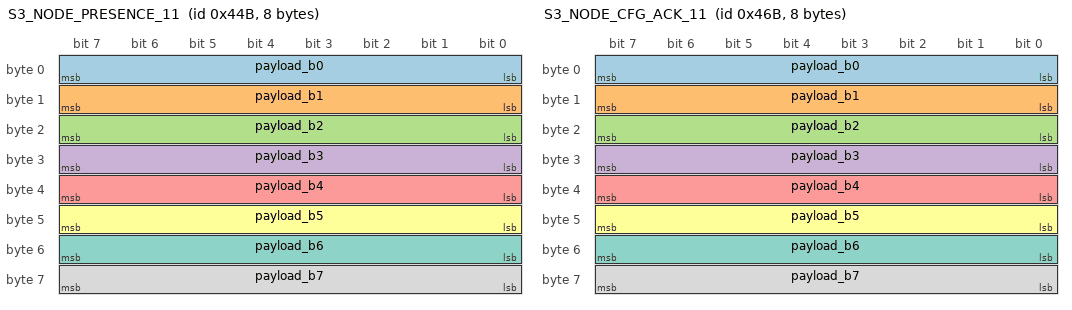
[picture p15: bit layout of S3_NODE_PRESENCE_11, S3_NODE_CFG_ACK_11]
BO_ 1099 S3_NODE_PRESENCE_11: 8 NODE11
 SG_ payload_b0 : 0|8@1+ (1,0) [0|255] "raw"  MASTER,NODE1,NODE2,NODE3,NODE4,NODE5,NODE6,NODE7,NODE8,NODE9,NODE10,NODE11,NODE12,NODE13,NODE14,NODE15,NODE16,TOOL
 SG_ payload_b1 : 8|8@1+ (1,0) [0|255] "raw"  MASTER,NODE1,NODE2,NODE3,NODE4,NODE5,NODE6,NODE7,NODE8,NODE9,NODE10,NODE11,NODE12,NODE13,NODE14,NODE15,NODE16,TOOL
 SG_ payload_b2 : 16|8@1+ (1,0) [0|255] "raw"  MASTER,NODE1,NODE2,NODE3,NODE4,NODE5,NODE6,NODE7,NODE8,NODE9,NODE10,NODE11,NODE12,NODE13,NODE14,NODE15,NODE16,TOOL
 SG_ payload_b3 : 24|8@1+ (1,0) [0|255] "raw"  MASTER,NODE1,NODE2,NODE3,NODE4,NODE5,NODE6,NODE7,NODE8,NODE9,NODE10,NODE11,NODE12,NODE13,NODE14,NODE15,NODE16,TOOL
 SG_ payload_b4 : 32|8@1+ (1,0) [0|255] "raw"  MASTER,NODE1,NODE2,NODE3,NODE4,NODE5,NODE6,NODE7,NODE8,NODE9,NODE10,NODE11,NODE12,NODE13,NODE14,NODE15,NODE16,TOOL
 SG_ payload_b5 : 40|8@1+ (1,0) [0|255] "raw"  MASTER,NODE1,NODE2,NODE3,NODE4,NODE5,NODE6,NODE7,NODE8,NODE9,NODE10,NODE11,NODE12,NODE13,NODE14,NODE15,NODE16,TOOL
 SG_ payload_b6 : 48|8@1+ (1,0) [0|255] "raw"  MASTER,NODE1,NODE2,NODE3,NODE4,NODE5,NODE6,NODE7,NODE8,NODE9,NODE10,NODE11,NODE12,NODE13,NODE14,NODE15,NODE16,TOOL
 SG_ payload_b7 : 56|8@1+ (1,0) [0|255] "raw"  MASTER,NODE1,NODE2,NODE3,NODE4,NODE5,NODE6,NODE7,NODE8,NODE9,NODE10,NODE11,NODE12,NODE13,NODE14,NODE15,NODE16,TOOL

BO_ 1131 S3_NODE_CFG_ACK_11: 8 NODE11
 SG_ payload_b0 : 0|8@1+ (1,0) [0|255] "raw"  MASTER,NODE1,NODE2,NODE3,NODE4,NODE5,NODE6,NODE7,NODE8,NODE9,NODE10,NODE11,NODE12,NODE13,NODE14,NODE15,NODE16,TOOL
 SG_ payload_b1 : 8|8@1+ (1,0) [0|255] "raw"  MASTER,NODE1,NODE2,NODE3,NODE4,NODE5,NODE6,NODE7,NODE8,NODE9,NODE10,NODE11,NODE12,NODE13,NODE14,NODE15,NODE16,TOOL
 SG_ payload_b2 : 16|8@1+ (1,0) [0|255] "raw"  MASTER,NODE1,NODE2,NODE3,NODE4,NODE5,NODE6,NODE7,NODE8,NODE9,NODE10,NODE11,NODE12,NODE13,NODE14,NODE15,NODE16,TOOL
 SG_ payload_b3 : 24|8@1+ (1,0) [0|255] "raw"  MASTER,NODE1,NODE2,NODE3,NODE4,NODE5,NODE6,NODE7,NODE8,NODE9,NODE10,NODE11,NODE12,NODE13,NODE14,NODE15,NODE16,TOOL
 SG_ payload_b4 : 32|8@1+ (1,0) [0|255] "raw"  MASTER,NODE1,NODE2,NODE3,NODE4,NODE5,NODE6,NODE7,NODE8,NODE9,NODE10,NODE11,NODE12,NODE13,NODE14,NODE15,NODE16,TOOL
 SG_ payload_b5 : 40|8@1+ (1,0) [0|255] "raw"  MASTER,NODE1,NODE2,NODE3,NODE4,NODE5,NODE6,NODE7,NODE8,NODE9,NODE10,NODE11,NODE12,NODE13,NODE14,NODE15,NODE16,TOOL
 SG_ payload_b6 : 48|8@1+ (1,0) [0|255] "raw"  MASTER,NODE1,NODE2,NODE3,NODE4,NODE5,NODE6,NODE7,NODE8,NODE9,NODE10,NODE11,NODE12,NODE13,NODE14,NODE15,NODE16,TOOL
 SG_ payload_b7 : 56|8@1+ (1,0) [0|255] "raw"  MASTER,NODE1,NODE2,NODE3,NODE4,NODE5,NODE6,NODE7,NODE8,NODE9,NODE10,NODE11,NODE12,NODE13,NODE14,NODE15,NODE16,TOOL

BO_ 1163 S3_NODE_STATUS_FAST_11: 8 NODE11
 SG_ status_flags : 0|8@1+ (1,0) [0|255] "bitfield"  MASTER,NODE1,NODE2,NODE3,NODE4,NODE5,NODE6,NODE7,NODE8,NODE9,NODE10,NODE11,NODE12,NODE13,NODE14,NODE15,NODE16,TOOL
 SG_ error_code : 8|8@1+ (1,0) [0|255] ""  MASTER,NODE1,NODE2,NODE3,NODE4,NODE5,NODE6,NODE7,NODE8,NODE9,NODE10,NODE11,NODE12,NODE13,NODE14,NODE15,NODE16,TOOL
 SG_ actual_rpm : 16|16@1+ (1,0) [0|10000] "rpm"  MASTER,NODE1,NODE2,NODE3,NODE4,NODE5,NODE6,NODE7,NODE8,NODE9,NODE10,NODE11,NODE12,NODE13,NODE14,NODE15,NODE16,TOOL
 SG_ actual_pos : 32|16@1+ (1.52587890625e-05,0) [0|0.9999847412109375] "rev"  MASTER,NODE1,NODE2,NODE3,NODE4,NODE5,NODE6,NODE7,NODE8,NODE9,NODE10,NODE11,NODE12,NODE13,NODE14,NODE15,NODE16,TOOL
 SG_ alive_counter : 48|8@1+ (1,0) [0|255] ""  MASTER,NODE1,NODE2,NODE3,NODE4,NODE5,NODE6,NODE7,NODE8,NODE9,NODE10,NODE11,NODE12,NODE13,NODE14,NODE15,NODE16,TOOL
 SG_ sync_error : 56|8@1- (0.00390625,0) [-0.5|0.49609375] "rev"  MASTER,NODE1,NODE2,NODE3,NODE4,NODE5,NODE6,NODE7,NODE8,NODE9,NODE10,NODE11,NODE12,NODE13,NODE14,NODE15,NODE16,TOOL

BO_ 1227 S3_NODE_DIAG_11: 8 NODE11
 SG_ bus_voltage : 0|16@1+ (0.1,0) [0|6553.5] "V"  MASTER,NODE1,NODE2,NODE3,NODE4,NODE5,NODE6,NODE7,NODE8,NODE9,NODE10,NODE11,NODE12,NODE13,NODE14,NODE15,NODE16,TOOL
 SG_ motor_current : 16|16@1- (0.1,0) [-3276.8|3276.7] "A"  MASTER,NODE1,NODE2,NODE3,NODE4,NODE5,NODE6,NODE7,NODE8,NODE9,NODE10,NODE11,NODE12,NODE13,NODE14,NODE15,NODE16,TOOL
 SG_ controller_temp : 32|8@1- (1,0) [-128|127] "degC"  MASTER,NODE1,NODE2,NODE3,NODE4,NODE5,NODE6,NODE7,NODE8,NODE9,NODE10,NODE11,NODE12,NODE13,NODE14,NODE15,NODE16,TOOL
 SG_ motor_temp : 40|8@1- (1,0) [-128|127] "degC"  MASTER,NODE1,NODE2,NODE3,NODE4,NODE5,NODE6,NODE7,NODE8,NODE9,NODE10,NODE11,NODE12,NODE13,NODE14,NODE15,NODE16,TOOL
 SG_ fault_flags : 48|8@1+ (1,0) [0|255] "bitfield"  MASTER,NODE1,NODE2,NODE3,NODE4,NODE5,NODE6,NODE7,NODE8,NODE9,NODE10,NODE11,NODE12,NODE13,NODE14,NODE15,NODE16,TOOL
 SG_ warning_flags : 56|8@1+ (1,0) [0|255] "bitfield"  MASTER,NODE1,NODE2,NODE3,NODE4,NODE5,NODE6,NODE7,NODE8,NODE9,NODE10,NODE11,NODE12,NODE13,NODE14,NODE15,NODE16,TOOL

BO_ 1052 S3_NODE_CMD_12: 8 MASTER
 SG_ node_command : 0|8@1+ (1,0) [0|255] ""  MASTER,NODE1,NODE2,NODE3,NODE4,NODE5,NODE6,NODE7,NODE8,NODE9,NODE10,NODE11,NODE12,NODE13,NODE14,NODE15,NODE16,TOOL
 SG_ node_flags : 8|8@1+ (1,0) [0|255] "bitfield"  MASTER,NODE1,NODE2,NODE3,NODE4,NODE5,NODE6,NODE7,NODE8,NODE9,NODE10,NODE11,NODE12,NODE13,NODE14,NODE15,NODE16,TOOL
 SG_ trim_rpm : 16|16@1- (0.1,0) [-3276.8|3276.7] "rpm"  MASTER,NODE1,NODE2,NODE3,NODE4,NODE5,NODE6,NODE7,NODE8,NODE9,NODE10,NODE11,NODE12,NODE13,NODE14,NODE15,NODE16,TOOL
 SG_ section_mask : 32|16@1+ (1,0) [0|65535] "bitmask"  MASTER,NODE1,NODE2,NODE3,NODE4,NODE5,NODE6,NODE7,NODE8,NODE9,NODE10,NODE11,NODE12,NODE13,NODE14,NODE15,NODE16,TOOL
 SG_ seq : 48|8@1+ (1,0) [0|255] ""  MASTER,NODE1,NODE2,NODE3,NODE4,NODE5,NODE6,NODE7,NODE8,NODE9,NODE10,NODE11,NODE12,NODE13,NODE14,NODE15,NODE16,TOOL
 SG_ reserved : 56|8@1+ (1,0) [0|255] ""  MASTER,NODE1,NODE2,NODE3,NODE4,NODE5,NODE6,NODE7,NODE8,NODE9,NODE10,NODE11,NODE12,NODE13,NODE14,NODE15,NODE16,TOOL

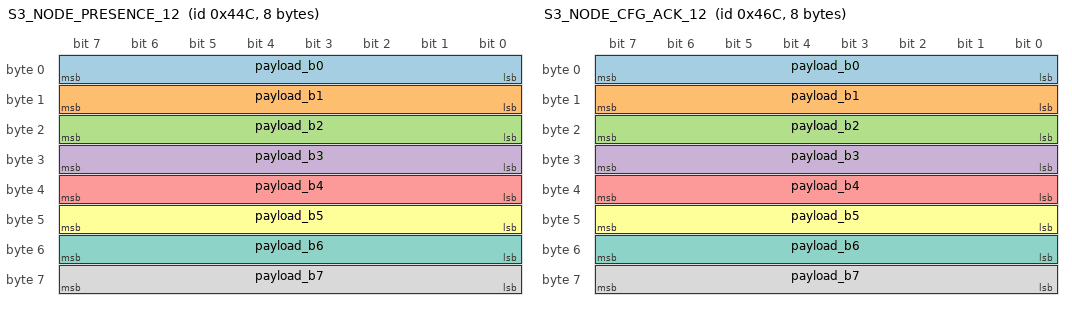
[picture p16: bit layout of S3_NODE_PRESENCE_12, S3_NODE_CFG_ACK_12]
BO_ 1100 S3_NODE_PRESENCE_12: 8 NODE12
 SG_ payload_b0 : 0|8@1+ (1,0) [0|255] "raw"  MASTER,NODE1,NODE2,NODE3,NODE4,NODE5,NODE6,NODE7,NODE8,NODE9,NODE10,NODE11,NODE12,NODE13,NODE14,NODE15,NODE16,TOOL
 SG_ payload_b1 : 8|8@1+ (1,0) [0|255] "raw"  MASTER,NODE1,NODE2,NODE3,NODE4,NODE5,NODE6,NODE7,NODE8,NODE9,NODE10,NODE11,NODE12,NODE13,NODE14,NODE15,NODE16,TOOL
 SG_ payload_b2 : 16|8@1+ (1,0) [0|255] "raw"  MASTER,NODE1,NODE2,NODE3,NODE4,NODE5,NODE6,NODE7,NODE8,NODE9,NODE10,NODE11,NODE12,NODE13,NODE14,NODE15,NODE16,TOOL
 SG_ payload_b3 : 24|8@1+ (1,0) [0|255] "raw"  MASTER,NODE1,NODE2,NODE3,NODE4,NODE5,NODE6,NODE7,NODE8,NODE9,NODE10,NODE11,NODE12,NODE13,NODE14,NODE15,NODE16,TOOL
 SG_ payload_b4 : 32|8@1+ (1,0) [0|255] "raw"  MASTER,NODE1,NODE2,NODE3,NODE4,NODE5,NODE6,NODE7,NODE8,NODE9,NODE10,NODE11,NODE12,NODE13,NODE14,NODE15,NODE16,TOOL
 SG_ payload_b5 : 40|8@1+ (1,0) [0|255] "raw"  MASTER,NODE1,NODE2,NODE3,NODE4,NODE5,NODE6,NODE7,NODE8,NODE9,NODE10,NODE11,NODE12,NODE13,NODE14,NODE15,NODE16,TOOL
 SG_ payload_b6 : 48|8@1+ (1,0) [0|255] "raw"  MASTER,NODE1,NODE2,NODE3,NODE4,NODE5,NODE6,NODE7,NODE8,NODE9,NODE10,NODE11,NODE12,NODE13,NODE14,NODE15,NODE16,TOOL
 SG_ payload_b7 : 56|8@1+ (1,0) [0|255] "raw"  MASTER,NODE1,NODE2,NODE3,NODE4,NODE5,NODE6,NODE7,NODE8,NODE9,NODE10,NODE11,NODE12,NODE13,NODE14,NODE15,NODE16,TOOL

BO_ 1132 S3_NODE_CFG_ACK_12: 8 NODE12
 SG_ payload_b0 : 0|8@1+ (1,0) [0|255] "raw"  MASTER,NODE1,NODE2,NODE3,NODE4,NODE5,NODE6,NODE7,NODE8,NODE9,NODE10,NODE11,NODE12,NODE13,NODE14,NODE15,NODE16,TOOL
 SG_ payload_b1 : 8|8@1+ (1,0) [0|255] "raw"  MASTER,NODE1,NODE2,NODE3,NODE4,NODE5,NODE6,NODE7,NODE8,NODE9,NODE10,NODE11,NODE12,NODE13,NODE14,NODE15,NODE16,TOOL
 SG_ payload_b2 : 16|8@1+ (1,0) [0|255] "raw"  MASTER,NODE1,NODE2,NODE3,NODE4,NODE5,NODE6,NODE7,NODE8,NODE9,NODE10,NODE11,NODE12,NODE13,NODE14,NODE15,NODE16,TOOL
 SG_ payload_b3 : 24|8@1+ (1,0) [0|255] "raw"  MASTER,NODE1,NODE2,NODE3,NODE4,NODE5,NODE6,NODE7,NODE8,NODE9,NODE10,NODE11,NODE12,NODE13,NODE14,NODE15,NODE16,TOOL
 SG_ payload_b4 : 32|8@1+ (1,0) [0|255] "raw"  MASTER,NODE1,NODE2,NODE3,NODE4,NODE5,NODE6,NODE7,NODE8,NODE9,NODE10,NODE11,NODE12,NODE13,NODE14,NODE15,NODE16,TOOL
 SG_ payload_b5 : 40|8@1+ (1,0) [0|255] "raw"  MASTER,NODE1,NODE2,NODE3,NODE4,NODE5,NODE6,NODE7,NODE8,NODE9,NODE10,NODE11,NODE12,NODE13,NODE14,NODE15,NODE16,TOOL
 SG_ payload_b6 : 48|8@1+ (1,0) [0|255] "raw"  MASTER,NODE1,NODE2,NODE3,NODE4,NODE5,NODE6,NODE7,NODE8,NODE9,NODE10,NODE11,NODE12,NODE13,NODE14,NODE15,NODE16,TOOL
 SG_ payload_b7 : 56|8@1+ (1,0) [0|255] "raw"  MASTER,NODE1,NODE2,NODE3,NODE4,NODE5,NODE6,NODE7,NODE8,NODE9,NODE10,NODE11,NODE12,NODE13,NODE14,NODE15,NODE16,TOOL

BO_ 1164 S3_NODE_STATUS_FAST_12: 8 NODE12
 SG_ status_flags : 0|8@1+ (1,0) [0|255] "bitfield"  MASTER,NODE1,NODE2,NODE3,NODE4,NODE5,NODE6,NODE7,NODE8,NODE9,NODE10,NODE11,NODE12,NODE13,NODE14,NODE15,NODE16,TOOL
 SG_ error_code : 8|8@1+ (1,0) [0|255] ""  MASTER,NODE1,NODE2,NODE3,NODE4,NODE5,NODE6,NODE7,NODE8,NODE9,NODE10,NODE11,NODE12,NODE13,NODE14,NODE15,NODE16,TOOL
 SG_ actual_rpm : 16|16@1+ (1,0) [0|10000] "rpm"  MASTER,NODE1,NODE2,NODE3,NODE4,NODE5,NODE6,NODE7,NODE8,NODE9,NODE10,NODE11,NODE12,NODE13,NODE14,NODE15,NODE16,TOOL
 SG_ actual_pos : 32|16@1+ (1.52587890625e-05,0) [0|0.9999847412109375] "rev"  MASTER,NODE1,NODE2,NODE3,NODE4,NODE5,NODE6,NODE7,NODE8,NODE9,NODE10,NODE11,NODE12,NODE13,NODE14,NODE15,NODE16,TOOL
 SG_ alive_counter : 48|8@1+ (1,0) [0|255] ""  MASTER,NODE1,NODE2,NODE3,NODE4,NODE5,NODE6,NODE7,NODE8,NODE9,NODE10,NODE11,NODE12,NODE13,NODE14,NODE15,NODE16,TOOL
 SG_ sync_error : 56|8@1- (0.00390625,0) [-0.5|0.49609375] "rev"  MASTER,NODE1,NODE2,NODE3,NODE4,NODE5,NODE6,NODE7,NODE8,NODE9,NODE10,NODE11,NODE12,NODE13,NODE14,NODE15,NODE16,TOOL

BO_ 1228 S3_NODE_DIAG_12: 8 NODE12
 SG_ bus_voltage : 0|16@1+ (0.1,0) [0|6553.5] "V"  MASTER,NODE1,NODE2,NODE3,NODE4,NODE5,NODE6,NODE7,NODE8,NODE9,NODE10,NODE11,NODE12,NODE13,NODE14,NODE15,NODE16,TOOL
 SG_ motor_current : 16|16@1- (0.1,0) [-3276.8|3276.7] "A"  MASTER,NODE1,NODE2,NODE3,NODE4,NODE5,NODE6,NODE7,NODE8,NODE9,NODE10,NODE11,NODE12,NODE13,NODE14,NODE15,NODE16,TOOL
 SG_ controller_temp : 32|8@1- (1,0) [-128|127] "degC"  MASTER,NODE1,NODE2,NODE3,NODE4,NODE5,NODE6,NODE7,NODE8,NODE9,NODE10,NODE11,NODE12,NODE13,NODE14,NODE15,NODE16,TOOL
 SG_ motor_temp : 40|8@1- (1,0) [-128|127] "degC"  MASTER,NODE1,NODE2,NODE3,NODE4,NODE5,NODE6,NODE7,NODE8,NODE9,NODE10,NODE11,NODE12,NODE13,NODE14,NODE15,NODE16,TOOL
 SG_ fault_flags : 48|8@1+ (1,0) [0|255] "bitfield"  MASTER,NODE1,NODE2,NODE3,NODE4,NODE5,NODE6,NODE7,NODE8,NODE9,NODE10,NODE11,NODE12,NODE13,NODE14,NODE15,NODE16,TOOL
 SG_ warning_flags : 56|8@1+ (1,0) [0|255] "bitfield"  MASTER,NODE1,NODE2,NODE3,NODE4,NODE5,NODE6,NODE7,NODE8,NODE9,NODE10,NODE11,NODE12,NODE13,NODE14,NODE15,NODE16,TOOL

BO_ 1053 S3_NODE_CMD_13: 8 MASTER
 SG_ node_command : 0|8@1+ (1,0) [0|255] ""  MASTER,NODE1,NODE2,NODE3,NODE4,NODE5,NODE6,NODE7,NODE8,NODE9,NODE10,NODE11,NODE12,NODE13,NODE14,NODE15,NODE16,TOOL
 SG_ node_flags : 8|8@1+ (1,0) [0|255] "bitfield"  MASTER,NODE1,NODE2,NODE3,NODE4,NODE5,NODE6,NODE7,NODE8,NODE9,NODE10,NODE11,NODE12,NODE13,NODE14,NODE15,NODE16,TOOL
 SG_ trim_rpm : 16|16@1- (0.1,0) [-3276.8|3276.7] "rpm"  MASTER,NODE1,NODE2,NODE3,NODE4,NODE5,NODE6,NODE7,NODE8,NODE9,NODE10,NODE11,NODE12,NODE13,NODE14,NODE15,NODE16,TOOL
 SG_ section_mask : 32|16@1+ (1,0) [0|65535] "bitmask"  MASTER,NODE1,NODE2,NODE3,NODE4,NODE5,NODE6,NODE7,NODE8,NODE9,NODE10,NODE11,NODE12,NODE13,NODE14,NODE15,NODE16,TOOL
 SG_ seq : 48|8@1+ (1,0) [0|255] ""  MASTER,NODE1,NODE2,NODE3,NODE4,NODE5,NODE6,NODE7,NODE8,NODE9,NODE10,NODE11,NODE12,NODE13,NODE14,NODE15,NODE16,TOOL
 SG_ reserved : 56|8@1+ (1,0) [0|255] ""  MASTER,NODE1,NODE2,NODE3,NODE4,NODE5,NODE6,NODE7,NODE8,NODE9,NODE10,NODE11,NODE12,NODE13,NODE14,NODE15,NODE16,TOOL

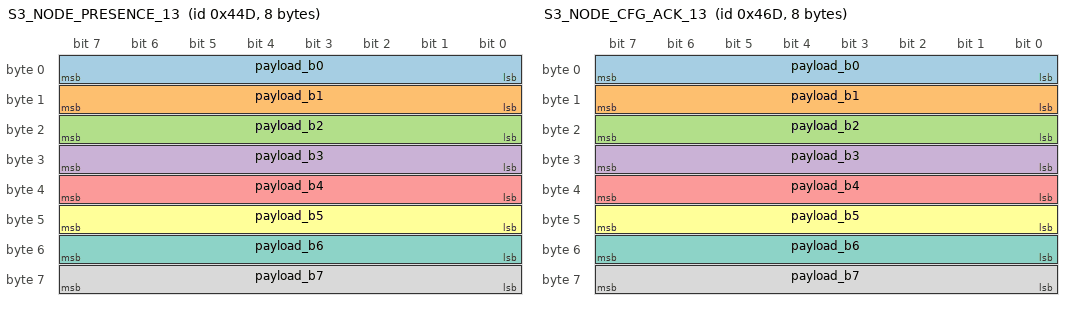
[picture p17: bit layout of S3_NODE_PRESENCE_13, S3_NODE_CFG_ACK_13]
BO_ 1101 S3_NODE_PRESENCE_13: 8 NODE13
 SG_ payload_b0 : 0|8@1+ (1,0) [0|255] "raw"  MASTER,NODE1,NODE2,NODE3,NODE4,NODE5,NODE6,NODE7,NODE8,NODE9,NODE10,NODE11,NODE12,NODE13,NODE14,NODE15,NODE16,TOOL
 SG_ payload_b1 : 8|8@1+ (1,0) [0|255] "raw"  MASTER,NODE1,NODE2,NODE3,NODE4,NODE5,NODE6,NODE7,NODE8,NODE9,NODE10,NODE11,NODE12,NODE13,NODE14,NODE15,NODE16,TOOL
 SG_ payload_b2 : 16|8@1+ (1,0) [0|255] "raw"  MASTER,NODE1,NODE2,NODE3,NODE4,NODE5,NODE6,NODE7,NODE8,NODE9,NODE10,NODE11,NODE12,NODE13,NODE14,NODE15,NODE16,TOOL
 SG_ payload_b3 : 24|8@1+ (1,0) [0|255] "raw"  MASTER,NODE1,NODE2,NODE3,NODE4,NODE5,NODE6,NODE7,NODE8,NODE9,NODE10,NODE11,NODE12,NODE13,NODE14,NODE15,NODE16,TOOL
 SG_ payload_b4 : 32|8@1+ (1,0) [0|255] "raw"  MASTER,NODE1,NODE2,NODE3,NODE4,NODE5,NODE6,NODE7,NODE8,NODE9,NODE10,NODE11,NODE12,NODE13,NODE14,NODE15,NODE16,TOOL
 SG_ payload_b5 : 40|8@1+ (1,0) [0|255] "raw"  MASTER,NODE1,NODE2,NODE3,NODE4,NODE5,NODE6,NODE7,NODE8,NODE9,NODE10,NODE11,NODE12,NODE13,NODE14,NODE15,NODE16,TOOL
 SG_ payload_b6 : 48|8@1+ (1,0) [0|255] "raw"  MASTER,NODE1,NODE2,NODE3,NODE4,NODE5,NODE6,NODE7,NODE8,NODE9,NODE10,NODE11,NODE12,NODE13,NODE14,NODE15,NODE16,TOOL
 SG_ payload_b7 : 56|8@1+ (1,0) [0|255] "raw"  MASTER,NODE1,NODE2,NODE3,NODE4,NODE5,NODE6,NODE7,NODE8,NODE9,NODE10,NODE11,NODE12,NODE13,NODE14,NODE15,NODE16,TOOL

BO_ 1133 S3_NODE_CFG_ACK_13: 8 NODE13
 SG_ payload_b0 : 0|8@1+ (1,0) [0|255] "raw"  MASTER,NODE1,NODE2,NODE3,NODE4,NODE5,NODE6,NODE7,NODE8,NODE9,NODE10,NODE11,NODE12,NODE13,NODE14,NODE15,NODE16,TOOL
 SG_ payload_b1 : 8|8@1+ (1,0) [0|255] "raw"  MASTER,NODE1,NODE2,NODE3,NODE4,NODE5,NODE6,NODE7,NODE8,NODE9,NODE10,NODE11,NODE12,NODE13,NODE14,NODE15,NODE16,TOOL
 SG_ payload_b2 : 16|8@1+ (1,0) [0|255] "raw"  MASTER,NODE1,NODE2,NODE3,NODE4,NODE5,NODE6,NODE7,NODE8,NODE9,NODE10,NODE11,NODE12,NODE13,NODE14,NODE15,NODE16,TOOL
 SG_ payload_b3 : 24|8@1+ (1,0) [0|255] "raw"  MASTER,NODE1,NODE2,NODE3,NODE4,NODE5,NODE6,NODE7,NODE8,NODE9,NODE10,NODE11,NODE12,NODE13,NODE14,NODE15,NODE16,TOOL
 SG_ payload_b4 : 32|8@1+ (1,0) [0|255] "raw"  MASTER,NODE1,NODE2,NODE3,NODE4,NODE5,NODE6,NODE7,NODE8,NODE9,NODE10,NODE11,NODE12,NODE13,NODE14,NODE15,NODE16,TOOL
 SG_ payload_b5 : 40|8@1+ (1,0) [0|255] "raw"  MASTER,NODE1,NODE2,NODE3,NODE4,NODE5,NODE6,NODE7,NODE8,NODE9,NODE10,NODE11,NODE12,NODE13,NODE14,NODE15,NODE16,TOOL
 SG_ payload_b6 : 48|8@1+ (1,0) [0|255] "raw"  MASTER,NODE1,NODE2,NODE3,NODE4,NODE5,NODE6,NODE7,NODE8,NODE9,NODE10,NODE11,NODE12,NODE13,NODE14,NODE15,NODE16,TOOL
 SG_ payload_b7 : 56|8@1+ (1,0) [0|255] "raw"  MASTER,NODE1,NODE2,NODE3,NODE4,NODE5,NODE6,NODE7,NODE8,NODE9,NODE10,NODE11,NODE12,NODE13,NODE14,NODE15,NODE16,TOOL

BO_ 1165 S3_NODE_STATUS_FAST_13: 8 NODE13
 SG_ status_flags : 0|8@1+ (1,0) [0|255] "bitfield"  MASTER,NODE1,NODE2,NODE3,NODE4,NODE5,NODE6,NODE7,NODE8,NODE9,NODE10,NODE11,NODE12,NODE13,NODE14,NODE15,NODE16,TOOL
 SG_ error_code : 8|8@1+ (1,0) [0|255] ""  MASTER,NODE1,NODE2,NODE3,NODE4,NODE5,NODE6,NODE7,NODE8,NODE9,NODE10,NODE11,NODE12,NODE13,NODE14,NODE15,NODE16,TOOL
 SG_ actual_rpm : 16|16@1+ (1,0) [0|10000] "rpm"  MASTER,NODE1,NODE2,NODE3,NODE4,NODE5,NODE6,NODE7,NODE8,NODE9,NODE10,NODE11,NODE12,NODE13,NODE14,NODE15,NODE16,TOOL
 SG_ actual_pos : 32|16@1+ (1.52587890625e-05,0) [0|0.9999847412109375] "rev"  MASTER,NODE1,NODE2,NODE3,NODE4,NODE5,NODE6,NODE7,NODE8,NODE9,NODE10,NODE11,NODE12,NODE13,NODE14,NODE15,NODE16,TOOL
 SG_ alive_counter : 48|8@1+ (1,0) [0|255] ""  MASTER,NODE1,NODE2,NODE3,NODE4,NODE5,NODE6,NODE7,NODE8,NODE9,NODE10,NODE11,NODE12,NODE13,NODE14,NODE15,NODE16,TOOL
 SG_ sync_error : 56|8@1- (0.00390625,0) [-0.5|0.49609375] "rev"  MASTER,NODE1,NODE2,NODE3,NODE4,NODE5,NODE6,NODE7,NODE8,NODE9,NODE10,NODE11,NODE12,NODE13,NODE14,NODE15,NODE16,TOOL

BO_ 1229 S3_NODE_DIAG_13: 8 NODE13
 SG_ bus_voltage : 0|16@1+ (0.1,0) [0|6553.5] "V"  MASTER,NODE1,NODE2,NODE3,NODE4,NODE5,NODE6,NODE7,NODE8,NODE9,NODE10,NODE11,NODE12,NODE13,NODE14,NODE15,NODE16,TOOL
 SG_ motor_current : 16|16@1- (0.1,0) [-3276.8|3276.7] "A"  MASTER,NODE1,NODE2,NODE3,NODE4,NODE5,NODE6,NODE7,NODE8,NODE9,NODE10,NODE11,NODE12,NODE13,NODE14,NODE15,NODE16,TOOL
 SG_ controller_temp : 32|8@1- (1,0) [-128|127] "degC"  MASTER,NODE1,NODE2,NODE3,NODE4,NODE5,NODE6,NODE7,NODE8,NODE9,NODE10,NODE11,NODE12,NODE13,NODE14,NODE15,NODE16,TOOL
 SG_ motor_temp : 40|8@1- (1,0) [-128|127] "degC"  MASTER,NODE1,NODE2,NODE3,NODE4,NODE5,NODE6,NODE7,NODE8,NODE9,NODE10,NODE11,NODE12,NODE13,NODE14,NODE15,NODE16,TOOL
 SG_ fault_flags : 48|8@1+ (1,0) [0|255] "bitfield"  MASTER,NODE1,NODE2,NODE3,NODE4,NODE5,NODE6,NODE7,NODE8,NODE9,NODE10,NODE11,NODE12,NODE13,NODE14,NODE15,NODE16,TOOL
 SG_ warning_flags : 56|8@1+ (1,0) [0|255] "bitfield"  MASTER,NODE1,NODE2,NODE3,NODE4,NODE5,NODE6,NODE7,NODE8,NODE9,NODE10,NODE11,NODE12,NODE13,NODE14,NODE15,NODE16,TOOL

BO_ 1054 S3_NODE_CMD_14: 8 MASTER
 SG_ node_command : 0|8@1+ (1,0) [0|255] ""  MASTER,NODE1,NODE2,NODE3,NODE4,NODE5,NODE6,NODE7,NODE8,NODE9,NODE10,NODE11,NODE12,NODE13,NODE14,NODE15,NODE16,TOOL
 SG_ node_flags : 8|8@1+ (1,0) [0|255] "bitfield"  MASTER,NODE1,NODE2,NODE3,NODE4,NODE5,NODE6,NODE7,NODE8,NODE9,NODE10,NODE11,NODE12,NODE13,NODE14,NODE15,NODE16,TOOL
 SG_ trim_rpm : 16|16@1- (0.1,0) [-3276.8|3276.7] "rpm"  MASTER,NODE1,NODE2,NODE3,NODE4,NODE5,NODE6,NODE7,NODE8,NODE9,NODE10,NODE11,NODE12,NODE13,NODE14,NODE15,NODE16,TOOL
 SG_ section_mask : 32|16@1+ (1,0) [0|65535] "bitmask"  MASTER,NODE1,NODE2,NODE3,NODE4,NODE5,NODE6,NODE7,NODE8,NODE9,NODE10,NODE11,NODE12,NODE13,NODE14,NODE15,NODE16,TOOL
 SG_ seq : 48|8@1+ (1,0) [0|255] ""  MASTER,NODE1,NODE2,NODE3,NODE4,NODE5,NODE6,NODE7,NODE8,NODE9,NODE10,NODE11,NODE12,NODE13,NODE14,NODE15,NODE16,TOOL
 SG_ reserved : 56|8@1+ (1,0) [0|255] ""  MASTER,NODE1,NODE2,NODE3,NODE4,NODE5,NODE6,NODE7,NODE8,NODE9,NODE10,NODE11,NODE12,NODE13,NODE14,NODE15,NODE16,TOOL

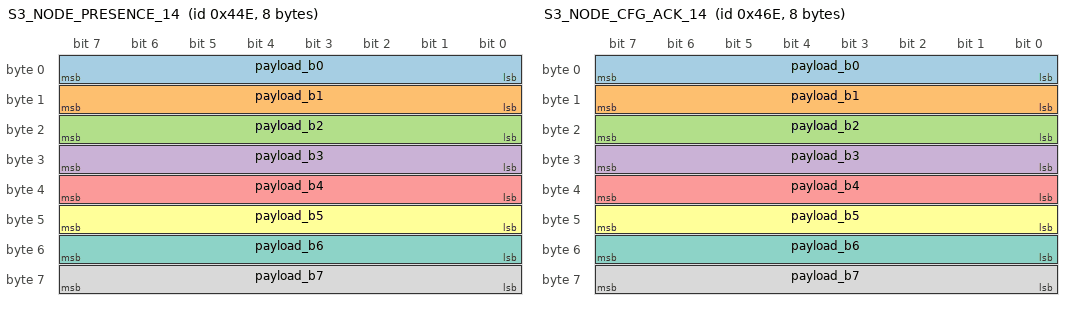
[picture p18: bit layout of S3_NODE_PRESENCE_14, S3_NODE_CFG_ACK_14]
BO_ 1102 S3_NODE_PRESENCE_14: 8 NODE14
 SG_ payload_b0 : 0|8@1+ (1,0) [0|255] "raw"  MASTER,NODE1,NODE2,NODE3,NODE4,NODE5,NODE6,NODE7,NODE8,NODE9,NODE10,NODE11,NODE12,NODE13,NODE14,NODE15,NODE16,TOOL
 SG_ payload_b1 : 8|8@1+ (1,0) [0|255] "raw"  MASTER,NODE1,NODE2,NODE3,NODE4,NODE5,NODE6,NODE7,NODE8,NODE9,NODE10,NODE11,NODE12,NODE13,NODE14,NODE15,NODE16,TOOL
 SG_ payload_b2 : 16|8@1+ (1,0) [0|255] "raw"  MASTER,NODE1,NODE2,NODE3,NODE4,NODE5,NODE6,NODE7,NODE8,NODE9,NODE10,NODE11,NODE12,NODE13,NODE14,NODE15,NODE16,TOOL
 SG_ payload_b3 : 24|8@1+ (1,0) [0|255] "raw"  MASTER,NODE1,NODE2,NODE3,NODE4,NODE5,NODE6,NODE7,NODE8,NODE9,NODE10,NODE11,NODE12,NODE13,NODE14,NODE15,NODE16,TOOL
 SG_ payload_b4 : 32|8@1+ (1,0) [0|255] "raw"  MASTER,NODE1,NODE2,NODE3,NODE4,NODE5,NODE6,NODE7,NODE8,NODE9,NODE10,NODE11,NODE12,NODE13,NODE14,NODE15,NODE16,TOOL
 SG_ payload_b5 : 40|8@1+ (1,0) [0|255] "raw"  MASTER,NODE1,NODE2,NODE3,NODE4,NODE5,NODE6,NODE7,NODE8,NODE9,NODE10,NODE11,NODE12,NODE13,NODE14,NODE15,NODE16,TOOL
 SG_ payload_b6 : 48|8@1+ (1,0) [0|255] "raw"  MASTER,NODE1,NODE2,NODE3,NODE4,NODE5,NODE6,NODE7,NODE8,NODE9,NODE10,NODE11,NODE12,NODE13,NODE14,NODE15,NODE16,TOOL
 SG_ payload_b7 : 56|8@1+ (1,0) [0|255] "raw"  MASTER,NODE1,NODE2,NODE3,NODE4,NODE5,NODE6,NODE7,NODE8,NODE9,NODE10,NODE11,NODE12,NODE13,NODE14,NODE15,NODE16,TOOL

BO_ 1134 S3_NODE_CFG_ACK_14: 8 NODE14
 SG_ payload_b0 : 0|8@1+ (1,0) [0|255] "raw"  MASTER,NODE1,NODE2,NODE3,NODE4,NODE5,NODE6,NODE7,NODE8,NODE9,NODE10,NODE11,NODE12,NODE13,NODE14,NODE15,NODE16,TOOL
 SG_ payload_b1 : 8|8@1+ (1,0) [0|255] "raw"  MASTER,NODE1,NODE2,NODE3,NODE4,NODE5,NODE6,NODE7,NODE8,NODE9,NODE10,NODE11,NODE12,NODE13,NODE14,NODE15,NODE16,TOOL
 SG_ payload_b2 : 16|8@1+ (1,0) [0|255] "raw"  MASTER,NODE1,NODE2,NODE3,NODE4,NODE5,NODE6,NODE7,NODE8,NODE9,NODE10,NODE11,NODE12,NODE13,NODE14,NODE15,NODE16,TOOL
 SG_ payload_b3 : 24|8@1+ (1,0) [0|255] "raw"  MASTER,NODE1,NODE2,NODE3,NODE4,NODE5,NODE6,NODE7,NODE8,NODE9,NODE10,NODE11,NODE12,NODE13,NODE14,NODE15,NODE16,TOOL
 SG_ payload_b4 : 32|8@1+ (1,0) [0|255] "raw"  MASTER,NODE1,NODE2,NODE3,NODE4,NODE5,NODE6,NODE7,NODE8,NODE9,NODE10,NODE11,NODE12,NODE13,NODE14,NODE15,NODE16,TOOL
 SG_ payload_b5 : 40|8@1+ (1,0) [0|255] "raw"  MASTER,NODE1,NODE2,NODE3,NODE4,NODE5,NODE6,NODE7,NODE8,NODE9,NODE10,NODE11,NODE12,NODE13,NODE14,NODE15,NODE16,TOOL
 SG_ payload_b6 : 48|8@1+ (1,0) [0|255] "raw"  MASTER,NODE1,NODE2,NODE3,NODE4,NODE5,NODE6,NODE7,NODE8,NODE9,NODE10,NODE11,NODE12,NODE13,NODE14,NODE15,NODE16,TOOL
 SG_ payload_b7 : 56|8@1+ (1,0) [0|255] "raw"  MASTER,NODE1,NODE2,NODE3,NODE4,NODE5,NODE6,NODE7,NODE8,NODE9,NODE10,NODE11,NODE12,NODE13,NODE14,NODE15,NODE16,TOOL

BO_ 1166 S3_NODE_STATUS_FAST_14: 8 NODE14
 SG_ status_flags : 0|8@1+ (1,0) [0|255] "bitfield"  MASTER,NODE1,NODE2,NODE3,NODE4,NODE5,NODE6,NODE7,NODE8,NODE9,NODE10,NODE11,NODE12,NODE13,NODE14,NODE15,NODE16,TOOL
 SG_ error_code : 8|8@1+ (1,0) [0|255] ""  MASTER,NODE1,NODE2,NODE3,NODE4,NODE5,NODE6,NODE7,NODE8,NODE9,NODE10,NODE11,NODE12,NODE13,NODE14,NODE15,NODE16,TOOL
 SG_ actual_rpm : 16|16@1+ (1,0) [0|10000] "rpm"  MASTER,NODE1,NODE2,NODE3,NODE4,NODE5,NODE6,NODE7,NODE8,NODE9,NODE10,NODE11,NODE12,NODE13,NODE14,NODE15,NODE16,TOOL
 SG_ actual_pos : 32|16@1+ (1.52587890625e-05,0) [0|0.9999847412109375] "rev"  MASTER,NODE1,NODE2,NODE3,NODE4,NODE5,NODE6,NODE7,NODE8,NODE9,NODE10,NODE11,NODE12,NODE13,NODE14,NODE15,NODE16,TOOL
 SG_ alive_counter : 48|8@1+ (1,0) [0|255] ""  MASTER,NODE1,NODE2,NODE3,NODE4,NODE5,NODE6,NODE7,NODE8,NODE9,NODE10,NODE11,NODE12,NODE13,NODE14,NODE15,NODE16,TOOL
 SG_ sync_error : 56|8@1- (0.00390625,0) [-0.5|0.49609375] "rev"  MASTER,NODE1,NODE2,NODE3,NODE4,NODE5,NODE6,NODE7,NODE8,NODE9,NODE10,NODE11,NODE12,NODE13,NODE14,NODE15,NODE16,TOOL

BO_ 1230 S3_NODE_DIAG_14: 8 NODE14
 SG_ bus_voltage : 0|16@1+ (0.1,0) [0|6553.5] "V"  MASTER,NODE1,NODE2,NODE3,NODE4,NODE5,NODE6,NODE7,NODE8,NODE9,NODE10,NODE11,NODE12,NODE13,NODE14,NODE15,NODE16,TOOL
 SG_ motor_current : 16|16@1- (0.1,0) [-3276.8|3276.7] "A"  MASTER,NODE1,NODE2,NODE3,NODE4,NODE5,NODE6,NODE7,NODE8,NODE9,NODE10,NODE11,NODE12,NODE13,NODE14,NODE15,NODE16,TOOL
 SG_ controller_temp : 32|8@1- (1,0) [-128|127] "degC"  MASTER,NODE1,NODE2,NODE3,NODE4,NODE5,NODE6,NODE7,NODE8,NODE9,NODE10,NODE11,NODE12,NODE13,NODE14,NODE15,NODE16,TOOL
 SG_ motor_temp : 40|8@1- (1,0) [-128|127] "degC"  MASTER,NODE1,NODE2,NODE3,NODE4,NODE5,NODE6,NODE7,NODE8,NODE9,NODE10,NODE11,NODE12,NODE13,NODE14,NODE15,NODE16,TOOL
 SG_ fault_flags : 48|8@1+ (1,0) [0|255] "bitfield"  MASTER,NODE1,NODE2,NODE3,NODE4,NODE5,NODE6,NODE7,NODE8,NODE9,NODE10,NODE11,NODE12,NODE13,NODE14,NODE15,NODE16,TOOL
 SG_ warning_flags : 56|8@1+ (1,0) [0|255] "bitfield"  MASTER,NODE1,NODE2,NODE3,NODE4,NODE5,NODE6,NODE7,NODE8,NODE9,NODE10,NODE11,NODE12,NODE13,NODE14,NODE15,NODE16,TOOL

BO_ 1055 S3_NODE_CMD_15: 8 MASTER
 SG_ node_command : 0|8@1+ (1,0) [0|255] ""  MASTER,NODE1,NODE2,NODE3,NODE4,NODE5,NODE6,NODE7,NODE8,NODE9,NODE10,NODE11,NODE12,NODE13,NODE14,NODE15,NODE16,TOOL
 SG_ node_flags : 8|8@1+ (1,0) [0|255] "bitfield"  MASTER,NODE1,NODE2,NODE3,NODE4,NODE5,NODE6,NODE7,NODE8,NODE9,NODE10,NODE11,NODE12,NODE13,NODE14,NODE15,NODE16,TOOL
 SG_ trim_rpm : 16|16@1- (0.1,0) [-3276.8|3276.7] "rpm"  MASTER,NODE1,NODE2,NODE3,NODE4,NODE5,NODE6,NODE7,NODE8,NODE9,NODE10,NODE11,NODE12,NODE13,NODE14,NODE15,NODE16,TOOL
 SG_ section_mask : 32|16@1+ (1,0) [0|65535] "bitmask"  MASTER,NODE1,NODE2,NODE3,NODE4,NODE5,NODE6,NODE7,NODE8,NODE9,NODE10,NODE11,NODE12,NODE13,NODE14,NODE15,NODE16,TOOL
 SG_ seq : 48|8@1+ (1,0) [0|255] ""  MASTER,NODE1,NODE2,NODE3,NODE4,NODE5,NODE6,NODE7,NODE8,NODE9,NODE10,NODE11,NODE12,NODE13,NODE14,NODE15,NODE16,TOOL
 SG_ reserved : 56|8@1+ (1,0) [0|255] ""  MASTER,NODE1,NODE2,NODE3,NODE4,NODE5,NODE6,NODE7,NODE8,NODE9,NODE10,NODE11,NODE12,NODE13,NODE14,NODE15,NODE16,TOOL

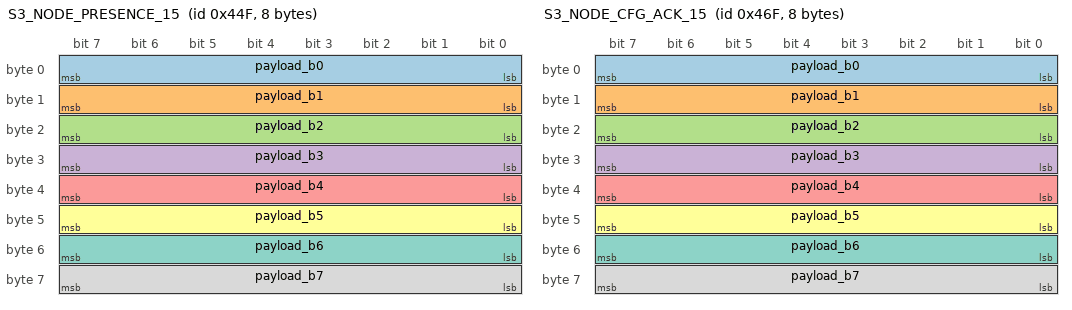
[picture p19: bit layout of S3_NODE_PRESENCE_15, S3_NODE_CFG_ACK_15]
BO_ 1103 S3_NODE_PRESENCE_15: 8 NODE15
 SG_ payload_b0 : 0|8@1+ (1,0) [0|255] "raw"  MASTER,NODE1,NODE2,NODE3,NODE4,NODE5,NODE6,NODE7,NODE8,NODE9,NODE10,NODE11,NODE12,NODE13,NODE14,NODE15,NODE16,TOOL
 SG_ payload_b1 : 8|8@1+ (1,0) [0|255] "raw"  MASTER,NODE1,NODE2,NODE3,NODE4,NODE5,NODE6,NODE7,NODE8,NODE9,NODE10,NODE11,NODE12,NODE13,NODE14,NODE15,NODE16,TOOL
 SG_ payload_b2 : 16|8@1+ (1,0) [0|255] "raw"  MASTER,NODE1,NODE2,NODE3,NODE4,NODE5,NODE6,NODE7,NODE8,NODE9,NODE10,NODE11,NODE12,NODE13,NODE14,NODE15,NODE16,TOOL
 SG_ payload_b3 : 24|8@1+ (1,0) [0|255] "raw"  MASTER,NODE1,NODE2,NODE3,NODE4,NODE5,NODE6,NODE7,NODE8,NODE9,NODE10,NODE11,NODE12,NODE13,NODE14,NODE15,NODE16,TOOL
 SG_ payload_b4 : 32|8@1+ (1,0) [0|255] "raw"  MASTER,NODE1,NODE2,NODE3,NODE4,NODE5,NODE6,NODE7,NODE8,NODE9,NODE10,NODE11,NODE12,NODE13,NODE14,NODE15,NODE16,TOOL
 SG_ payload_b5 : 40|8@1+ (1,0) [0|255] "raw"  MASTER,NODE1,NODE2,NODE3,NODE4,NODE5,NODE6,NODE7,NODE8,NODE9,NODE10,NODE11,NODE12,NODE13,NODE14,NODE15,NODE16,TOOL
 SG_ payload_b6 : 48|8@1+ (1,0) [0|255] "raw"  MASTER,NODE1,NODE2,NODE3,NODE4,NODE5,NODE6,NODE7,NODE8,NODE9,NODE10,NODE11,NODE12,NODE13,NODE14,NODE15,NODE16,TOOL
 SG_ payload_b7 : 56|8@1+ (1,0) [0|255] "raw"  MASTER,NODE1,NODE2,NODE3,NODE4,NODE5,NODE6,NODE7,NODE8,NODE9,NODE10,NODE11,NODE12,NODE13,NODE14,NODE15,NODE16,TOOL

BO_ 1135 S3_NODE_CFG_ACK_15: 8 NODE15
 SG_ payload_b0 : 0|8@1+ (1,0) [0|255] "raw"  MASTER,NODE1,NODE2,NODE3,NODE4,NODE5,NODE6,NODE7,NODE8,NODE9,NODE10,NODE11,NODE12,NODE13,NODE14,NODE15,NODE16,TOOL
 SG_ payload_b1 : 8|8@1+ (1,0) [0|255] "raw"  MASTER,NODE1,NODE2,NODE3,NODE4,NODE5,NODE6,NODE7,NODE8,NODE9,NODE10,NODE11,NODE12,NODE13,NODE14,NODE15,NODE16,TOOL
 SG_ payload_b2 : 16|8@1+ (1,0) [0|255] "raw"  MASTER,NODE1,NODE2,NODE3,NODE4,NODE5,NODE6,NODE7,NODE8,NODE9,NODE10,NODE11,NODE12,NODE13,NODE14,NODE15,NODE16,TOOL
 SG_ payload_b3 : 24|8@1+ (1,0) [0|255] "raw"  MASTER,NODE1,NODE2,NODE3,NODE4,NODE5,NODE6,NODE7,NODE8,NODE9,NODE10,NODE11,NODE12,NODE13,NODE14,NODE15,NODE16,TOOL
 SG_ payload_b4 : 32|8@1+ (1,0) [0|255] "raw"  MASTER,NODE1,NODE2,NODE3,NODE4,NODE5,NODE6,NODE7,NODE8,NODE9,NODE10,NODE11,NODE12,NODE13,NODE14,NODE15,NODE16,TOOL
 SG_ payload_b5 : 40|8@1+ (1,0) [0|255] "raw"  MASTER,NODE1,NODE2,NODE3,NODE4,NODE5,NODE6,NODE7,NODE8,NODE9,NODE10,NODE11,NODE12,NODE13,NODE14,NODE15,NODE16,TOOL
 SG_ payload_b6 : 48|8@1+ (1,0) [0|255] "raw"  MASTER,NODE1,NODE2,NODE3,NODE4,NODE5,NODE6,NODE7,NODE8,NODE9,NODE10,NODE11,NODE12,NODE13,NODE14,NODE15,NODE16,TOOL
 SG_ payload_b7 : 56|8@1+ (1,0) [0|255] "raw"  MASTER,NODE1,NODE2,NODE3,NODE4,NODE5,NODE6,NODE7,NODE8,NODE9,NODE10,NODE11,NODE12,NODE13,NODE14,NODE15,NODE16,TOOL

BO_ 1167 S3_NODE_STATUS_FAST_15: 8 NODE15
 SG_ status_flags : 0|8@1+ (1,0) [0|255] "bitfield"  MASTER,NODE1,NODE2,NODE3,NODE4,NODE5,NODE6,NODE7,NODE8,NODE9,NODE10,NODE11,NODE12,NODE13,NODE14,NODE15,NODE16,TOOL
 SG_ error_code : 8|8@1+ (1,0) [0|255] ""  MASTER,NODE1,NODE2,NODE3,NODE4,NODE5,NODE6,NODE7,NODE8,NODE9,NODE10,NODE11,NODE12,NODE13,NODE14,NODE15,NODE16,TOOL
 SG_ actual_rpm : 16|16@1+ (1,0) [0|10000] "rpm"  MASTER,NODE1,NODE2,NODE3,NODE4,NODE5,NODE6,NODE7,NODE8,NODE9,NODE10,NODE11,NODE12,NODE13,NODE14,NODE15,NODE16,TOOL
 SG_ actual_pos : 32|16@1+ (1.52587890625e-05,0) [0|0.9999847412109375] "rev"  MASTER,NODE1,NODE2,NODE3,NODE4,NODE5,NODE6,NODE7,NODE8,NODE9,NODE10,NODE11,NODE12,NODE13,NODE14,NODE15,NODE16,TOOL
 SG_ alive_counter : 48|8@1+ (1,0) [0|255] ""  MASTER,NODE1,NODE2,NODE3,NODE4,NODE5,NODE6,NODE7,NODE8,NODE9,NODE10,NODE11,NODE12,NODE13,NODE14,NODE15,NODE16,TOOL
 SG_ sync_error : 56|8@1- (0.00390625,0) [-0.5|0.49609375] "rev"  MASTER,NODE1,NODE2,NODE3,NODE4,NODE5,NODE6,NODE7,NODE8,NODE9,NODE10,NODE11,NODE12,NODE13,NODE14,NODE15,NODE16,TOOL

BO_ 1231 S3_NODE_DIAG_15: 8 NODE15
 SG_ bus_voltage : 0|16@1+ (0.1,0) [0|6553.5] "V"  MASTER,NODE1,NODE2,NODE3,NODE4,NODE5,NODE6,NODE7,NODE8,NODE9,NODE10,NODE11,NODE12,NODE13,NODE14,NODE15,NODE16,TOOL
 SG_ motor_current : 16|16@1- (0.1,0) [-3276.8|3276.7] "A"  MASTER,NODE1,NODE2,NODE3,NODE4,NODE5,NODE6,NODE7,NODE8,NODE9,NODE10,NODE11,NODE12,NODE13,NODE14,NODE15,NODE16,TOOL
 SG_ controller_temp : 32|8@1- (1,0) [-128|127] "degC"  MASTER,NODE1,NODE2,NODE3,NODE4,NODE5,NODE6,NODE7,NODE8,NODE9,NODE10,NODE11,NODE12,NODE13,NODE14,NODE15,NODE16,TOOL
 SG_ motor_temp : 40|8@1- (1,0) [-128|127] "degC"  MASTER,NODE1,NODE2,NODE3,NODE4,NODE5,NODE6,NODE7,NODE8,NODE9,NODE10,NODE11,NODE12,NODE13,NODE14,NODE15,NODE16,TOOL
 SG_ fault_flags : 48|8@1+ (1,0) [0|255] "bitfield"  MASTER,NODE1,NODE2,NODE3,NODE4,NODE5,NODE6,NODE7,NODE8,NODE9,NODE10,NODE11,NODE12,NODE13,NODE14,NODE15,NODE16,TOOL
 SG_ warning_flags : 56|8@1+ (1,0) [0|255] "bitfield"  MASTER,NODE1,NODE2,NODE3,NODE4,NODE5,NODE6,NODE7,NODE8,NODE9,NODE10,NODE11,NODE12,NODE13,NODE14,NODE15,NODE16,TOOL

BO_ 1056 S3_NODE_CMD_16: 8 MASTER
 SG_ node_command : 0|8@1+ (1,0) [0|255] ""  MASTER,NODE1,NODE2,NODE3,NODE4,NODE5,NODE6,NODE7,NODE8,NODE9,NODE10,NODE11,NODE12,NODE13,NODE14,NODE15,NODE16,TOOL
 SG_ node_flags : 8|8@1+ (1,0) [0|255] "bitfield"  MASTER,NODE1,NODE2,NODE3,NODE4,NODE5,NODE6,NODE7,NODE8,NODE9,NODE10,NODE11,NODE12,NODE13,NODE14,NODE15,NODE16,TOOL
 SG_ trim_rpm : 16|16@1- (0.1,0) [-3276.8|3276.7] "rpm"  MASTER,NODE1,NODE2,NODE3,NODE4,NODE5,NODE6,NODE7,NODE8,NODE9,NODE10,NODE11,NODE12,NODE13,NODE14,NODE15,NODE16,TOOL
 SG_ section_mask : 32|16@1+ (1,0) [0|65535] "bitmask"  MASTER,NODE1,NODE2,NODE3,NODE4,NODE5,NODE6,NODE7,NODE8,NODE9,NODE10,NODE11,NODE12,NODE13,NODE14,NODE15,NODE16,TOOL
 SG_ seq : 48|8@1+ (1,0) [0|255] ""  MASTER,NODE1,NODE2,NODE3,NODE4,NODE5,NODE6,NODE7,NODE8,NODE9,NODE10,NODE11,NODE12,NODE13,NODE14,NODE15,NODE16,TOOL
 SG_ reserved : 56|8@1+ (1,0) [0|255] ""  MASTER,NODE1,NODE2,NODE3,NODE4,NODE5,NODE6,NODE7,NODE8,NODE9,NODE10,NODE11,NODE12,NODE13,NODE14,NODE15,NODE16,TOOL

BO_ 1104 S3_NODE_PRESENCE_16: 8 NODE16
 SG_ payload_b0 : 0|8@1+ (1,0) [0|255] "raw"  MASTER,NODE1,NODE2,NODE3,NODE4,NODE5,NODE6,NODE7,NODE8,NODE9,NODE10,NODE11,NODE12,NODE13,NODE14,NODE15,NODE16,TOOL
 SG_ payload_b1 : 8|8@1+ (1,0) [0|255] "raw"  MASTER,NODE1,NODE2,NODE3,NODE4,NODE5,NODE6,NODE7,NODE8,NODE9,NODE10,NODE11,NODE12,NODE13,NODE14,NODE15,NODE16,TOOL
 SG_ payload_b2 : 16|8@1+ (1,0) [0|255] "raw"  MASTER,NODE1,NODE2,NODE3,NODE4,NODE5,NODE6,NODE7,NODE8,NODE9,NODE10,NODE11,NODE12,NODE13,NODE14,NODE15,NODE16,TOOL
 SG_ payload_b3 : 24|8@1+ (1,0) [0|255] "raw"  MASTER,NODE1,NODE2,NODE3,NODE4,NODE5,NODE6,NODE7,NODE8,NODE9,NODE10,NODE11,NODE12,NODE13,NODE14,NODE15,NODE16,TOOL
 SG_ payload_b4 : 32|8@1+ (1,0) [0|255] "raw"  MASTER,NODE1,NODE2,NODE3,NODE4,NODE5,NODE6,NODE7,NODE8,NODE9,NODE10,NODE11,NODE12,NODE13,NODE14,NODE15,NODE16,TOOL
 SG_ payload_b5 : 40|8@1+ (1,0) [0|255] "raw"  MASTER,NODE1,NODE2,NODE3,NODE4,NODE5,NODE6,NODE7,NODE8,NODE9,NODE10,NODE11,NODE12,NODE13,NODE14,NODE15,NODE16,TOOL
 SG_ payload_b6 : 48|8@1+ (1,0) [0|255] "raw"  MASTER,NODE1,NODE2,NODE3,NODE4,NODE5,NODE6,NODE7,NODE8,NODE9,NODE10,NODE11,NODE12,NODE13,NODE14,NODE15,NODE16,TOOL
 SG_ payload_b7 : 56|8@1+ (1,0) [0|255] "raw"  MASTER,NODE1,NODE2,NODE3,NODE4,NODE5,NODE6,NODE7,NODE8,NODE9,NODE10,NODE11,NODE12,NODE13,NODE14,NODE15,NODE16,TOOL

BO_ 1136 S3_NODE_CFG_ACK_16: 8 NODE16
 SG_ payload_b0 : 0|8@1+ (1,0) [0|255] "raw"  MASTER,NODE1,NODE2,NODE3,NODE4,NODE5,NODE6,NODE7,NODE8,NODE9,NODE10,NODE11,NODE12,NODE13,NODE14,NODE15,NODE16,TOOL
 SG_ payload_b1 : 8|8@1+ (1,0) [0|255] "raw"  MASTER,NODE1,NODE2,NODE3,NODE4,NODE5,NODE6,NODE7,NODE8,NODE9,NODE10,NODE11,NODE12,NODE13,NODE14,NODE15,NODE16,TOOL
 SG_ payload_b2 : 16|8@1+ (1,0) [0|255] "raw"  MASTER,NODE1,NODE2,NODE3,NODE4,NODE5,NODE6,NODE7,NODE8,NODE9,NODE10,NODE11,NODE12,NODE13,NODE14,NODE15,NODE16,TOOL
 SG_ payload_b3 : 24|8@1+ (1,0) [0|255] "raw"  MASTER,NODE1,NODE2,NODE3,NODE4,NODE5,NODE6,NODE7,NODE8,NODE9,NODE10,NODE11,NODE12,NODE13,NODE14,NODE15,NODE16,TOOL
 SG_ payload_b4 : 32|8@1+ (1,0) [0|255] "raw"  MASTER,NODE1,NODE2,NODE3,NODE4,NODE5,NODE6,NODE7,NODE8,NODE9,NODE10,NODE11,NODE12,NODE13,NODE14,NODE15,NODE16,TOOL
 SG_ payload_b5 : 40|8@1+ (1,0) [0|255] "raw"  MASTER,NODE1,NODE2,NODE3,NODE4,NODE5,NODE6,NODE7,NODE8,NODE9,NODE10,NODE11,NODE12,NODE13,NODE14,NODE15,NODE16,TOOL
 SG_ payload_b6 : 48|8@1+ (1,0) [0|255] "raw"  MASTER,NODE1,NODE2,NODE3,NODE4,NODE5,NODE6,NODE7,NODE8,NODE9,NODE10,NODE11,NODE12,NODE13,NODE14,NODE15,NODE16,TOOL
 SG_ payload_b7 : 56|8@1+ (1,0) [0|255] "raw"  MASTER,NODE1,NODE2,NODE3,NODE4,NODE5,NODE6,NODE7,NODE8,NODE9,NODE10,NODE11,NODE12,NODE13,NODE14,NODE15,NODE16,TOOL

BO_ 1168 S3_NODE_STATUS_FAST_16: 8 NODE16
 SG_ status_flags : 0|8@1+ (1,0) [0|255] "bitfield"  MASTER,NODE1,NODE2,NODE3,NODE4,NODE5,NODE6,NODE7,NODE8,NODE9,NODE10,NODE11,NODE12,NODE13,NODE14,NODE15,NODE16,TOOL
 SG_ error_code : 8|8@1+ (1,0) [0|255] ""  MASTER,NODE1,NODE2,NODE3,NODE4,NODE5,NODE6,NODE7,NODE8,NODE9,NODE10,NODE11,NODE12,NODE13,NODE14,NODE15,NODE16,TOOL
 SG_ actual_rpm : 16|16@1+ (1,0) [0|10000] "rpm"  MASTER,NODE1,NODE2,NODE3,NODE4,NODE5,NODE6,NODE7,NODE8,NODE9,NODE10,NODE11,NODE12,NODE13,NODE14,NODE15,NODE16,TOOL
 SG_ actual_pos : 32|16@1+ (1.52587890625e-05,0) [0|0.9999847412109375] "rev"  MASTER,NODE1,NODE2,NODE3,NODE4,NODE5,NODE6,NODE7,NODE8,NODE9,NODE10,NODE11,NODE12,NODE13,NODE14,NODE15,NODE16,TOOL
 SG_ alive_counter : 48|8@1+ (1,0) [0|255] ""  MASTER,NODE1,NODE2,NODE3,NODE4,NODE5,NODE6,NODE7,NODE8,NODE9,NODE10,NODE11,NODE12,NODE13,NODE14,NODE15,NODE16,TOOL
 SG_ sync_error : 56|8@1- (0.00390625,0) [-0.5|0.49609375] "rev"  MASTER,NODE1,NODE2,NODE3,NODE4,NODE5,NODE6,NODE7,NODE8,NODE9,NODE10,NODE11,NODE12,NODE13,NODE14,NODE15,NODE16,TOOL

BO_ 1232 S3_NODE_DIAG_16: 8 NODE16
 SG_ bus_voltage : 0|16@1+ (0.1,0) [0|6553.5] "V"  MASTER,NODE1,NODE2,NODE3,NODE4,NODE5,NODE6,NODE7,NODE8,NODE9,NODE10,NODE11,NODE12,NODE13,NODE14,NODE15,NODE16,TOOL
 SG_ motor_current : 16|16@1- (0.1,0) [-3276.8|3276.7] "A"  MASTER,NODE1,NODE2,NODE3,NODE4,NODE5,NODE6,NODE7,NODE8,NODE9,NODE10,NODE11,NODE12,NODE13,NODE14,NODE15,NODE16,TOOL
 SG_ controller_temp : 32|8@1- (1,0) [-128|127] "degC"  MASTER,NODE1,NODE2,NODE3,NODE4,NODE5,NODE6,NODE7,NODE8,NODE9,NODE10,NODE11,NODE12,NODE13,NODE14,NODE15,NODE16,TOOL
 SG_ motor_temp : 40|8@1- (1,0) [-128|127] "degC"  MASTER,NODE1,NODE2,NODE3,NODE4,NODE5,NODE6,NODE7,NODE8,NODE9,NODE10,NODE11,NODE12,NODE13,NODE14,NODE15,NODE16,TOOL
 SG_ fault_flags : 48|8@1+ (1,0) [0|255] "bitfield"  MASTER,NODE1,NODE2,NODE3,NODE4,NODE5,NODE6,NODE7,NODE8,NODE9,NODE10,NODE11,NODE12,NODE13,NODE14,NODE15,NODE16,TOOL
 SG_ warning_flags : 56|8@1+ (1,0) [0|255] "bitfield"  MASTER,NODE1,NODE2,NODE3,NODE4,NODE5,NODE6,NODE7,NODE8,NODE9,NODE10,NODE11,NODE12,NODE13,NODE14,NODE15,NODE16,TOOL

BO_ 1280 SRV_DISCOVER: 8 TOOL
 SG_ cmd : 0|8@1+ (1,0) [0|255] ""  MASTER,NODE1,NODE2,NODE3,NODE4,NODE5,NODE6,NODE7,NODE8,NODE9,NODE10,NODE11,NODE12,NODE13,NODE14,NODE15,NODE16,TOOL
 SG_ response_delay_slots : 8|8@1+ (1,0) [0|255] ""  MASTER,NODE1,NODE2,NODE3,NODE4,NODE5,NODE6,NODE7,NODE8,NODE9,NODE10,NODE11,NODE12,NODE13,NODE14,NODE15,NODE16,TOOL
 SG_ request_uid : 16|8@1+ (1,0) [0|1] "bool"  MASTER,NODE1,NODE2,NODE3,NODE4,NODE5,NODE6,NODE7,NODE8,NODE9,NODE10,NODE11,NODE12,NODE13,NODE14,NODE15,NODE16,TOOL
 SG_ request_cfg : 24|8@1+ (1,0) [0|1] "bool"  MASTER,NODE1,NODE2,NODE3,NODE4,NODE5,NODE6,NODE7,NODE8,NODE9,NODE10,NODE11,NODE12,NODE13,NODE14,NODE15,NODE16,TOOL
 SG_ reserved_b4 : 32|8@1+ (1,0) [0|255] ""  MASTER,NODE1,NODE2,NODE3,NODE4,NODE5,NODE6,NODE7,NODE8,NODE9,NODE10,NODE11,NODE12,NODE13,NODE14,NODE15,NODE16,TOOL
 SG_ reserved_b5 : 40|8@1+ (1,0) [0|255] ""  MASTER,NODE1,NODE2,NODE3,NODE4,NODE5,NODE6,NODE7,NODE8,NODE9,NODE10,NODE11,NODE12,NODE13,NODE14,NODE15,NODE16,TOOL
 SG_ reserved_b6 : 48|8@1+ (1,0) [0|255] ""  MASTER,NODE1,NODE2,NODE3,NODE4,NODE5,NODE6,NODE7,NODE8,NODE9,NODE10,NODE11,NODE12,NODE13,NODE14,NODE15,NODE16,TOOL
 SG_ reserved_b7 : 56|8@1+ (1,0) [0|255] ""  MASTER,NODE1,NODE2,NODE3,NODE4,NODE5,NODE6,NODE7,NODE8,NODE9,NODE10,NODE11,NODE12,NODE13,NODE14,NODE15,NODE16,TOOL

BO_ 1281 SRV_UID_A: 8 NODE1
 SG_ uid32 : 0|32@1+ (1,0) [0|4294967295] ""  MASTER,NODE1,NODE2,NODE3,NODE4,NODE5,NODE6,NODE7,NODE8,NODE9,NODE10,NODE11,NODE12,NODE13,NODE14,NODE15,NODE16,TOOL
 SG_ sensor_channel : 32|8@1+ (1,0) [0|255] ""  MASTER,NODE1,NODE2,NODE3,NODE4,NODE5,NODE6,NODE7,NODE8,NODE9,NODE10,NODE11,NODE12,NODE13,NODE14,NODE15,NODE16,TOOL
 SG_ node_id : 40|8@1+ (1,0) [0|255] ""  MASTER,NODE1,NODE2,NODE3,NODE4,NODE5,NODE6,NODE7,NODE8,NODE9,NODE10,NODE11,NODE12,NODE13,NODE14,NODE15,NODE16,TOOL
 SG_ fw_major : 48|8@1+ (1,0) [0|255] ""  MASTER,NODE1,NODE2,NODE3,NODE4,NODE5,NODE6,NODE7,NODE8,NODE9,NODE10,NODE11,NODE12,NODE13,NODE14,NODE15,NODE16,TOOL
 SG_ fw_minor : 56|8@1+ (1,0) [0|255] ""  MASTER,NODE1,NODE2,NODE3,NODE4,NODE5,NODE6,NODE7,NODE8,NODE9,NODE10,NODE11,NODE12,NODE13,NODE14,NODE15,NODE16,TOOL

BO_ 1282 SRV_UID_B: 8 NODE1
 SG_ uid32_hi : 0|32@1+ (1,0) [0|4294967295] ""  MASTER,NODE1,NODE2,NODE3,NODE4,NODE5,NODE6,NODE7,NODE8,NODE9,NODE10,NODE11,NODE12,NODE13,NODE14,NODE15,NODE16,TOOL
 SG_ hw_rev : 32|8@1+ (1,0) [0|255] ""  MASTER,NODE1,NODE2,NODE3,NODE4,NODE5,NODE6,NODE7,NODE8,NODE9,NODE10,NODE11,NODE12,NODE13,NODE14,NODE15,NODE16,TOOL
 SG_ cap_flags : 40|8@1+ (1,0) [0|255] "bitfield"  MASTER,NODE1,NODE2,NODE3,NODE4,NODE5,NODE6,NODE7,NODE8,NODE9,NODE10,NODE11,NODE12,NODE13,NODE14,NODE15,NODE16,TOOL
 SG_ status_flags : 48|8@1+ (1,0) [0|255] "bitfield"  MASTER,NODE1,NODE2,NODE3,NODE4,NODE5,NODE6,NODE7,NODE8,NODE9,NODE10,NODE11,NODE12,NODE13,NODE14,NODE15,NODE16,TOOL
 SG_ reserved : 56|8@1+ (1,0) [0|255] ""  MASTER,NODE1,NODE2,NODE3,NODE4,NODE5,NODE6,NODE7,NODE8,NODE9,NODE10,NODE11,NODE12,NODE13,NODE14,NODE15,NODE16,TOOL

BO_ 1283 SRV_ASSIGN: 8 TOOL
 SG_ uid32 : 0|32@1+ (1,0) [0|4294967295] ""  MASTER,NODE1,NODE2,NODE3,NODE4,NODE5,NODE6,NODE7,NODE8,NODE9,NODE10,NODE11,NODE12,NODE13,NODE14,NODE15,NODE16,TOOL
 SG_ sensor_channel : 32|8@1+ (1,0) [0|255] ""  MASTER,NODE1,NODE2,NODE3,NODE4,NODE5,NODE6,NODE7,NODE8,NODE9,NODE10,NODE11,NODE12,NODE13,NODE14,NODE15,NODE16,TOOL
 SG_ node_id : 40|8@1+ (1,0) [0|255] ""  MASTER,NODE1,NODE2,NODE3,NODE4,NODE5,NODE6,NODE7,NODE8,NODE9,NODE10,NODE11,NODE12,NODE13,NODE14,NODE15,NODE16,TOOL
 SG_ apply_now : 48|8@1+ (1,0) [0|1] "bool"  MASTER,NODE1,NODE2,NODE3,NODE4,NODE5,NODE6,NODE7,NODE8,NODE9,NODE10,NODE11,NODE12,NODE13,NODE14,NODE15,NODE16,TOOL
 SG_ save_now : 56|8@1+ (1,0) [0|1] "bool"  MASTER,NODE1,NODE2,NODE3,NODE4,NODE5,NODE6,NODE7,NODE8,NODE9,NODE10,NODE11,NODE12,NODE13,NODE14,NODE15,NODE16,TOOL

BO_ 1284 SRV_SAVE_CFG: 8 TOOL
 SG_ uid32 : 0|32@1+ (1,0) [0|4294967295] ""  MASTER,NODE1,NODE2,NODE3,NODE4,NODE5,NODE6,NODE7,NODE8,NODE9,NODE10,NODE11,NODE12,NODE13,NODE14,NODE15,NODE16,TOOL
 SG_ magic : 32|8@1+ (1,0) [0|255] ""  MASTER,NODE1,NODE2,NODE3,NODE4,NODE5,NODE6,NODE7,NODE8,NODE9,NODE10,NODE11,NODE12,NODE13,NODE14,NODE15,NODE16,TOOL
 SG_ scope : 40|8@1+ (1,0) [0|255] ""  MASTER,NODE1,NODE2,NODE3,NODE4,NODE5,NODE6,NODE7,NODE8,NODE9,NODE10,NODE11,NODE12,NODE13,NODE14,NODE15,NODE16,TOOL
 SG_ reserved_b6 : 48|8@1+ (1,0) [0|255] ""  MASTER,NODE1,NODE2,NODE3,NODE4,NODE5,NODE6,NODE7,NODE8,NODE9,NODE10,NODE11,NODE12,NODE13,NODE14,NODE15,NODE16,TOOL
 SG_ reserved_b7 : 56|8@1+ (1,0) [0|255] ""  MASTER,NODE1,NODE2,NODE3,NODE4,NODE5,NODE6,NODE7,NODE8,NODE9,NODE10,NODE11,NODE12,NODE13,NODE14,NODE15,NODE16,TOOL

BO_ 1285 SRV_ACK: 8 NODE1
 SG_ uid32 : 0|32@1+ (1,0) [0|4294967295] ""  MASTER,NODE1,NODE2,NODE3,NODE4,NODE5,NODE6,NODE7,NODE8,NODE9,NODE10,NODE11,NODE12,NODE13,NODE14,NODE15,NODE16,TOOL
 SG_ ack_cmd : 32|8@1+ (1,0) [0|255] ""  MASTER,NODE1,NODE2,NODE3,NODE4,NODE5,NODE6,NODE7,NODE8,NODE9,NODE10,NODE11,NODE12,NODE13,NODE14,NODE15,NODE16,TOOL
 SG_ result : 40|8@1+ (1,0) [0|255] ""  MASTER,NODE1,NODE2,NODE3,NODE4,NODE5,NODE6,NODE7,NODE8,NODE9,NODE10,NODE11,NODE12,NODE13,NODE14,NODE15,NODE16,TOOL
 SG_ sensor_channel : 48|8@1+ (1,0) [0|255] ""  MASTER,NODE1,NODE2,NODE3,NODE4,NODE5,NODE6,NODE7,NODE8,NODE9,NODE10,NODE11,NODE12,NODE13,NODE14,NODE15,NODE16,TOOL
 SG_ node_id : 56|8@1+ (1,0) [0|255] ""  MASTER,NODE1,NODE2,NODE3,NODE4,NODE5,NODE6,NODE7,NODE8,NODE9,NODE10,NODE11,NODE12,NODE13,NODE14,NODE15,NODE16,TOOL

BO_ 1286 SRV_TEST_SPIN: 8 TOOL
 SG_ uid32 : 0|32@1+ (1,0) [0|4294967295] ""  MASTER,NODE1,NODE2,NODE3,NODE4,NODE5,NODE6,NODE7,NODE8,NODE9,NODE10,NODE11,NODE12,NODE13,NODE14,NODE15,NODE16,TOOL
 SG_ test_rpm : 32|16@1- (0.1,0) [-3276.8|3276.7] "rpm"  MASTER,NODE1,NODE2,NODE3,NODE4,NODE5,NODE6,NODE7,NODE8,NODE9,NODE10,NODE11,NODE12,NODE13,NODE14,NODE15,NODE16,TOOL
 SG_ duration_s : 48|8@1+ (1,0) [0|255] "s"  MASTER,NODE1,NODE2,NODE3,NODE4,NODE5,NODE6,NODE7,NODE8,NODE9,NODE10,NODE11,NODE12,NODE13,NODE14,NODE15,NODE16,TOOL
 SG_ mode : 56|8@1+ (1,0) [0|255] ""  MASTER,NODE1,NODE2,NODE3,NODE4,NODE5,NODE6,NODE7,NODE8,NODE9,NODE10,NODE11,NODE12,NODE13,NODE14,NODE15,NODE16,TOOL

BO_ 1287 SRV_DIAG_REQ: 8 TOOL
 SG_ uid32 : 0|32@1+ (1,0) [0|4294967295] ""  MASTER,NODE1,NODE2,NODE3,NODE4,NODE5,NODE6,NODE7,NODE8,NODE9,NODE10,NODE11,NODE12,NODE13,NODE14,NODE15,NODE16,TOOL
 SG_ detail_level : 32|8@1+ (1,0) [0|255] ""  MASTER,NODE1,NODE2,NODE3,NODE4,NODE5,NODE6,NODE7,NODE8,NODE9,NODE10,NODE11,NODE12,NODE13,NODE14,NODE15,NODE16,TOOL
 SG_ include_runtime : 40|8@1+ (1,0) [0|1] "bool"  MASTER,NODE1,NODE2,NODE3,NODE4,NODE5,NODE6,NODE7,NODE8,NODE9,NODE10,NODE11,NODE12,NODE13,NODE14,NODE15,NODE16,TOOL
 SG_ include_cfg : 48|8@1+ (1,0) [0|1] "bool"  MASTER,NODE1,NODE2,NODE3,NODE4,NODE5,NODE6,NODE7,NODE8,NODE9,NODE10,NODE11,NODE12,NODE13,NODE14,NODE15,NODE16,TOOL
 SG_ reserved : 56|8@1+ (1,0) [0|255] ""  MASTER,NODE1,NODE2,NODE3,NODE4,NODE5,NODE6,NODE7,NODE8,NODE9,NODE10,NODE11,NODE12,NODE13,NODE14,NODE15,NODE16,TOOL

BO_ 1288 SRV_DIAG_RESP_A: 8 NODE1
 SG_ sensor_channel : 0|8@1+ (1,0) [0|255] ""  MASTER,NODE1,NODE2,NODE3,NODE4,NODE5,NODE6,NODE7,NODE8,NODE9,NODE10,NODE11,NODE12,NODE13,NODE14,NODE15,NODE16,TOOL
 SG_ node_id : 8|8@1+ (1,0) [0|255] ""  MASTER,NODE1,NODE2,NODE3,NODE4,NODE5,NODE6,NODE7,NODE8,NODE9,NODE10,NODE11,NODE12,NODE13,NODE14,NODE15,NODE16,TOOL
 SG_ actual_rpm : 16|16@1+ (1,0) [0|10000] "rpm"  MASTER,NODE1,NODE2,NODE3,NODE4,NODE5,NODE6,NODE7,NODE8,NODE9,NODE10,NODE11,NODE12,NODE13,NODE14,NODE15,NODE16,TOOL
 SG_ actual_pos : 32|16@1+ (1.52587890625e-05,0) [0|0.9999847412109375] "rev"  MASTER,NODE1,NODE2,NODE3,NODE4,NODE5,NODE6,NODE7,NODE8,NODE9,NODE10,NODE11,NODE12,NODE13,NODE14,NODE15,NODE16,TOOL
 SG_ error_code : 48|8@1+ (1,0) [0|255] ""  MASTER,NODE1,NODE2,NODE3,NODE4,NODE5,NODE6,NODE7,NODE8,NODE9,NODE10,NODE11,NODE12,NODE13,NODE14,NODE15,NODE16,TOOL
 SG_ status_flags : 56|8@1+ (1,0) [0|255] "bitfield"  MASTER,NODE1,NODE2,NODE3,NODE4,NODE5,NODE6,NODE7,NODE8,NODE9,NODE10,NODE11,NODE12,NODE13,NODE14,NODE15,NODE16,TOOL

BO_ 1289 SRV_DIAG_RESP_B: 8 NODE1
 SG_ uid32 : 0|32@1+ (1,0) [0|4294967295] ""  MASTER,NODE1,NODE2,NODE3,NODE4,NODE5,NODE6,NODE7,NODE8,NODE9,NODE10,NODE11,NODE12,NODE13,NODE14,NODE15,NODE16,TOOL
 SG_ sync_error : 32|8@1- (0.00390625,0) [-0.5|0.49609375] "rev"  MASTER,NODE1,NODE2,NODE3,NODE4,NODE5,NODE6,NODE7,NODE8,NODE9,NODE10,NODE11,NODE12,NODE13,NODE14,NODE15,NODE16,TOOL
 SG_ alive_counter : 40|8@1+ (1,0) [0|255] ""  MASTER,NODE1,NODE2,NODE3,NODE4,NODE5,NODE6,NODE7,NODE8,NODE9,NODE10,NODE11,NODE12,NODE13,NODE14,NODE15,NODE16,TOOL
 SG_ temp_or_supply : 48|8@1+ (1,0) [0|255] "raw"  MASTER,NODE1,NODE2,NODE3,NODE4,NODE5,NODE6,NODE7,NODE8,NODE9,NODE10,NODE11,NODE12,NODE13,NODE14,NODE15,NODE16,TOOL
 SG_ reserved : 56|8@1+ (1,0) [0|255] ""  MASTER,NODE1,NODE2,NODE3,NODE4,NODE5,NODE6,NODE7,NODE8,NODE9,NODE10,NODE11,NODE12,NODE13,NODE14,NODE15,NODE16,TOOL

BO_ 1290 SRV_REBOOT: 8 TOOL
 SG_ uid32 : 0|32@1+ (1,0) [0|4294967295] ""  MASTER,NODE1,NODE2,NODE3,NODE4,NODE5,NODE6,NODE7,NODE8,NODE9,NODE10,NODE11,NODE12,NODE13,NODE14,NODE15,NODE16,TOOL
 SG_ magic : 32|8@1+ (1,0) [0|255] ""  MASTER,NODE1,NODE2,NODE3,NODE4,NODE5,NODE6,NODE7,NODE8,NODE9,NODE10,NODE11,NODE12,NODE13,NODE14,NODE15,NODE16,TOOL
 SG_ reserved_b5 : 40|8@1+ (1,0) [0|255] ""  MASTER,NODE1,NODE2,NODE3,NODE4,NODE5,NODE6,NODE7,NODE8,NODE9,NODE10,NODE11,NODE12,NODE13,NODE14,NODE15,NODE16,TOOL
 SG_ reserved_b6 : 48|8@1+ (1,0) [0|255] ""  MASTER,NODE1,NODE2,NODE3,NODE4,NODE5,NODE6,NODE7,NODE8,NODE9,NODE10,NODE11,NODE12,NODE13,NODE14,NODE15,NODE16,TOOL
 SG_ reserved_b7 : 56|8@1+ (1,0) [0|255] ""  MASTER,NODE1,NODE2,NODE3,NODE4,NODE5,NODE6,NODE7,NODE8,NODE9,NODE10,NODE11,NODE12,NODE13,NODE14,NODE15,NODE16,TOOL

BO_ 1291 SRV_IDENTIFY: 8 TOOL
 SG_ uid32 : 0|32@1+ (1,0) [0|4294967295] ""  MASTER,NODE1,NODE2,NODE3,NODE4,NODE5,NODE6,NODE7,NODE8,NODE9,NODE10,NODE11,NODE12,NODE13,NODE14,NODE15,NODE16,TOOL
 SG_ mode : 32|8@1+ (1,0) [0|255] ""  MASTER,NODE1,NODE2,NODE3,NODE4,NODE5,NODE6,NODE7,NODE8,NODE9,NODE10,NODE11,NODE12,NODE13,NODE14,NODE15,NODE16,TOOL
 SG_ duration_s : 40|8@1+ (1,0) [0|255] "s"  MASTER,NODE1,NODE2,NODE3,NODE4,NODE5,NODE6,NODE7,NODE8,NODE9,NODE10,NODE11,NODE12,NODE13,NODE14,NODE15,NODE16,TOOL
 SG_ reserved_b6 : 48|8@1+ (1,0) [0|255] ""  MASTER,NODE1,NODE2,NODE3,NODE4,NODE5,NODE6,NODE7,NODE8,NODE9,NODE10,NODE11,NODE12,NODE13,NODE14,NODE15,NODE16,TOOL
 SG_ reserved_b7 : 56|8@1+ (1,0) [0|255] ""  MASTER,NODE1,NODE2,NODE3,NODE4,NODE5,NODE6,NODE7,NODE8,NODE9,NODE10,NODE11,NODE12,NODE13,NODE14,NODE15,NODE16,TOOL

BO_ 1292 SRV_CFG_READ: 8 TOOL
 SG_ uid32 : 0|32@1+ (1,0) [0|4294967295] ""  MASTER,NODE1,NODE2,NODE3,NODE4,NODE5,NODE6,NODE7,NODE8,NODE9,NODE10,NODE11,NODE12,NODE13,NODE14,NODE15,NODE16,TOOL
 SG_ block_id : 32|8@1+ (1,0) [0|255] ""  MASTER,NODE1,NODE2,NODE3,NODE4,NODE5,NODE6,NODE7,NODE8,NODE9,NODE10,NODE11,NODE12,NODE13,NODE14,NODE15,NODE16,TOOL
 SG_ reserved_b5 : 40|8@1+ (1,0) [0|255] ""  MASTER,NODE1,NODE2,NODE3,NODE4,NODE5,NODE6,NODE7,NODE8,NODE9,NODE10,NODE11,NODE12,NODE13,NODE14,NODE15,NODE16,TOOL
 SG_ reserved_b6 : 48|8@1+ (1,0) [0|255] ""  MASTER,NODE1,NODE2,NODE3,NODE4,NODE5,NODE6,NODE7,NODE8,NODE9,NODE10,NODE11,NODE12,NODE13,NODE14,NODE15,NODE16,TOOL
 SG_ reserved_b7 : 56|8@1+ (1,0) [0|255] ""  MASTER,NODE1,NODE2,NODE3,NODE4,NODE5,NODE6,NODE7,NODE8,NODE9,NODE10,NODE11,NODE12,NODE13,NODE14,NODE15,NODE16,TOOL

BO_ 1293 SRV_CFG_RESP: 8 NODE1
 SG_ block_id : 0|8@1+ (1,0) [0|255] ""  MASTER,NODE1,NODE2,NODE3,NODE4,NODE5,NODE6,NODE7,NODE8,NODE9,NODE10,NODE11,NODE12,NODE13,NODE14,NODE15,NODE16,TOOL
 SG_ node_id : 8|8@1+ (1,0) [0|255] ""  MASTER,NODE1,NODE2,NODE3,NODE4,NODE5,NODE6,NODE7,NODE8,NODE9,NODE10,NODE11,NODE12,NODE13,NODE14,NODE15,NODE16,TOOL
 SG_ data_b2 : 16|8@1+ (1,0) [0|255] "raw"  MASTER,NODE1,NODE2,NODE3,NODE4,NODE5,NODE6,NODE7,NODE8,NODE9,NODE10,NODE11,NODE12,NODE13,NODE14,NODE15,NODE16,TOOL
 SG_ data_b3 : 24|8@1+ (1,0) [0|255] "raw"  MASTER,NODE1,NODE2,NODE3,NODE4,NODE5,NODE6,NODE7,NODE8,NODE9,NODE10,NODE11,NODE12,NODE13,NODE14,NODE15,NODE16,TOOL
 SG_ data_b4 : 32|8@1+ (1,0) [0|255] "raw"  MASTER,NODE1,NODE2,NODE3,NODE4,NODE5,NODE6,NODE7,NODE8,NODE9,NODE10,NODE11,NODE12,NODE13,NODE14,NODE15,NODE16,TOOL
 SG_ data_b5 : 40|8@1+ (1,0) [0|255] "raw"  MASTER,NODE1,NODE2,NODE3,NODE4,NODE5,NODE6,NODE7,NODE8,NODE9,NODE10,NODE11,NODE12,NODE13,NODE14,NODE15,NODE16,TOOL
 SG_ data_b6 : 48|8@1+ (1,0) [0|255] "raw"  MASTER,NODE1,NODE2,NODE3,NODE4,NODE5,NODE6,NODE7,NODE8,NODE9,NODE10,NODE11,NODE12,NODE13,NODE14,NODE15,NODE16,TOOL
 SG_ data_b7 : 56|8@1+ (1,0) [0|255] "raw"  MASTER,NODE1,NODE2,NODE3,NODE4,NODE5,NODE6,NODE7,NODE8,NODE9,NODE10,NODE11,NODE12,NODE13,NODE14,NODE15,NODE16,TOOL

BO_ 1294 SRV_SET_CAN_SOURCE: 8 TOOL
 SG_ uid32 : 0|32@1+ (1,0) [0|4294967295] ""  MASTER,NODE1,NODE2,NODE3,NODE4,NODE5,NODE6,NODE7,NODE8,NODE9,NODE10,NODE11,NODE12,NODE13,NODE14,NODE15,NODE16,TOOL
 SG_ sensor_channel : 32|8@1+ (1,0) [0|255] ""  MASTER,NODE1,NODE2,NODE3,NODE4,NODE5,NODE6,NODE7,NODE8,NODE9,NODE10,NODE11,NODE12,NODE13,NODE14,NODE15,NODE16,TOOL
 SG_ node_id : 40|8@1+ (1,0) [0|255] ""  MASTER,NODE1,NODE2,NODE3,NODE4,NODE5,NODE6,NODE7,NODE8,NODE9,NODE10,NODE11,NODE12,NODE13,NODE14,NODE15,NODE16,TOOL
 SG_ can_profile_index : 48|8@1+ (1,0) [0|255] ""  MASTER,NODE1,NODE2,NODE3,NODE4,NODE5,NODE6,NODE7,NODE8,NODE9,NODE10,NODE11,NODE12,NODE13,NODE14,NODE15,NODE16,TOOL
 SG_ save_now : 56|8@1+ (1,0) [0|1] "bool"  MASTER,NODE1,NODE2,NODE3,NODE4,NODE5,NODE6,NODE7,NODE8,NODE9,NODE10,NODE11,NODE12,NODE13,NODE14,NODE15,NODE16,TOOL

CM_ SG_ 1024 control_flags "bit0=drive_enable, bit1=sync_enable, bit2=estop, bit3=diag_enable";
CM_ SG_ 1041 section_mask "Bytes 4-5 carry the full 16-bit section mask, not a position offset.";
CM_ SG_ 972 fault_flags "bit0=overcurrent, bit1=undervoltage, bit2=overvoltage, bit3=overtemperature, bit4=encoder_fault, bit5=hall_fault, bit6=motor_stall, bit7=driver_fault";
CM_ SG_ 972 warning_flags "bit0=rpm_deviation, bit1=sync_deviation, bit2=temp_high, bit3=current_high, bit4=communication_late";
CM_ SG_ 797 node_flags "bit0=allow_run, bit1=invert_dir, bit2=use_local_sensor";
CM_ SG_ 797 section_mask "NODE_CMD bytes 4-5 are used as section mask in current ECU firmware, not position offset.";
CM_ SG_ 909 status_flags "bit0=ready, bit1=enabled, bit2=running, bit3=sync_locked, bit4=warning_active, bit5=fault_active, bit6=position_valid, bit7=can_timeout";
CM_ SG_ 973 fault_flags "bit0=overcurrent, bit1=undervoltage, bit2=overvoltage, bit3=overtemperature, bit4=encoder_fault, bit5=hall_fault, bit6=motor_stall, bit7=driver_fault";
CM_ SG_ 973 warning_flags "bit0=rpm_deviation, bit1=sync_deviation, bit2=temp_high, bit3=current_high, bit4=communication_late";
CM_ SG_ 798 node_flags "bit0=allow_run, bit1=invert_dir, bit2=use_local_sensor";
CM_ SG_ 798 section_mask "NODE_CMD bytes 4-5 are used as section mask in current ECU firmware, not position offset.";
CM_ SG_ 910 status_flags "bit0=ready, bit1=enabled, bit2=running, bit3=sync_locked, bit4=warning_active, bit5=fault_active, bit6=position_valid, bit7=can_timeout";
CM_ SG_ 974 fault_flags "bit0=overcurrent, bit1=undervoltage, bit2=overvoltage, bit3=overtemperature, bit4=encoder_fault, bit5=hall_fault, bit6=motor_stall, bit7=driver_fault";
CM_ SG_ 974 warning_flags "bit0=rpm_deviation, bit1=sync_deviation, bit2=temp_high, bit3=current_high, bit4=communication_late";
CM_ SG_ 799 node_flags "bit0=allow_run, bit1=invert_dir, bit2=use_local_sensor";
CM_ SG_ 799 section_mask "NODE_CMD bytes 4-5 are used as section mask in current ECU firmware, not position offset.";
CM_ SG_ 911 status_flags "bit0=ready, bit1=enabled, bit2=running, bit3=sync_locked, bit4=warning_active, bit5=fault_active, bit6=position_valid, bit7=can_timeout";
CM_ SG_ 975 fault_flags "bit0=overcurrent, bit1=undervoltage, bit2=overvoltage, bit3=overtemperature, bit4=encoder_fault, bit5=hall_fault, bit6=motor_stall, bit7=driver_fault";
CM_ SG_ 975 warning_flags "bit0=rpm_deviation, bit1=sync_deviation, bit2=temp_high, bit3=current_high, bit4=communication_late";
CM_ SG_ 800 node_flags "bit0=allow_run, bit1=invert_dir, bit2=use_local_sensor";
CM_ SG_ 800 section_mask "NODE_CMD bytes 4-5 are used as section mask in current ECU firmware, not position offset.";
CM_ SG_ 912 status_flags "bit0=ready, bit1=enabled, bit2=running, bit3=sync_locked, bit4=warning_active, bit5=fault_active, bit6=position_valid, bit7=can_timeout";
CM_ SG_ 976 fault_flags "bit0=overcurrent, bit1=undervoltage, bit2=overvoltage, bit3=overtemperature, bit4=encoder_fault, bit5=hall_fault, bit6=motor_stall, bit7=driver_fault";
CM_ SG_ 976 warning_flags "bit0=rpm_deviation, bit1=sync_deviation, bit2=temp_high, bit3=current_high, bit4=communication_late";
CM_ BO_ 1024 "S3 runtime bank global control.";
CM_ SG_ 1041 node_flags "bit0=allow_run, bit1=invert_dir, bit2=use_local_sensor";
CM_ SG_ 1041 section_mask "NODE_CMD bytes 4-5 are used as section mask in current ECU firmware, not position offset.";
CM_ SG_ 1153 status_flags "bit0=ready, bit1=enabled, bit2=running, bit3=sync_locked, bit4=warning_active, bit5=fault_active, bit6=position_valid, bit7=can_timeout";
CM_ SG_ 1217 fault_flags "bit0=overcurrent, bit1=undervoltage, bit2=overvoltage, bit3=overtemperature, bit4=encoder_fault, bit5=hall_fault, bit6=motor_stall, bit7=driver_fault";
CM_ SG_ 1217 warning_flags "bit0=rpm_deviation, bit1=sync_deviation, bit2=temp_high, bit3=current_high, bit4=communication_late";
CM_ SG_ 1042 node_flags "bit0=allow_run, bit1=invert_dir, bit2=use_local_sensor";
CM_ SG_ 1042 section_mask "NODE_CMD bytes 4-5 are used as section mask in current ECU firmware, not position offset.";
CM_ SG_ 1154 status_flags "bit0=ready, bit1=enabled, bit2=running, bit3=sync_locked, bit4=warning_active, bit5=fault_active, bit6=position_valid, bit7=can_timeout";
CM_ SG_ 1218 fault_flags "bit0=overcurrent, bit1=undervoltage, bit2=overvoltage, bit3=overtemperature, bit4=encoder_fault, bit5=hall_fault, bit6=motor_stall, bit7=driver_fault";
CM_ SG_ 1218 warning_flags "bit0=rpm_deviation, bit1=sync_deviation, bit2=temp_high, bit3=current_high, bit4=communication_late";
CM_ SG_ 1043 node_flags "bit0=allow_run, bit1=invert_dir, bit2=use_local_sensor";
CM_ SG_ 1043 section_mask "NODE_CMD bytes 4-5 are used as section mask in current ECU firmware, not position offset.";
CM_ SG_ 1155 status_flags "bit0=ready, bit1=enabled, bit2=running, bit3=sync_locked, bit4=warning_active, bit5=fault_active, bit6=position_valid, bit7=can_timeout";
CM_ SG_ 1219 fault_flags "bit0=overcurrent, bit1=undervoltage, bit2=overvoltage, bit3=overtemperature, bit4=encoder_fault, bit5=hall_fault, bit6=motor_stall, bit7=driver_fault";
CM_ SG_ 1219 warning_flags "bit0=rpm_deviation, bit1=sync_deviation, bit2=temp_high, bit3=current_high, bit4=communication_late";
CM_ SG_ 1044 node_flags "bit0=allow_run, bit1=invert_dir, bit2=use_local_sensor";
CM_ SG_ 1044 section_mask "NODE_CMD bytes 4-5 are used as section mask in current ECU firmware, not position offset.";
CM_ SG_ 1156 status_flags "bit0=ready, bit1=enabled, bit2=running, bit3=sync_locked, bit4=warning_active, bit5=fault_active, bit6=position_valid, bit7=can_timeout";
CM_ SG_ 1220 fault_flags "bit0=overcurrent, bit1=undervoltage, bit2=overvoltage, bit3=overtemperature, bit4=encoder_fault, bit5=hall_fault, bit6=motor_stall, bit7=driver_fault";
CM_ SG_ 1220 warning_flags "bit0=rpm_deviation, bit1=sync_deviation, bit2=temp_high, bit3=current_high, bit4=communication_late";
CM_ SG_ 1045 node_flags "bit0=allow_run, bit1=invert_dir, bit2=use_local_sensor";
CM_ SG_ 1045 section_mask "NODE_CMD bytes 4-5 are used as section mask in current ECU firmware, not position offset.";
CM_ SG_ 1157 status_flags "bit0=ready, bit1=enabled, bit2=running, bit3=sync_locked, bit4=warning_active, bit5=fault_active, bit6=position_valid, bit7=can_timeout";
CM_ SG_ 1221 fault_flags "bit0=overcurrent, bit1=undervoltage, bit2=overvoltage, bit3=overtemperature, bit4=encoder_fault, bit5=hall_fault, bit6=motor_stall, bit7=driver_fault";
CM_ SG_ 1221 warning_flags "bit0=rpm_deviation, bit1=sync_deviation, bit2=temp_high, bit3=current_high, bit4=communication_late";
CM_ SG_ 1046 node_flags "bit0=allow_run, bit1=invert_dir, bit2=use_local_sensor";
CM_ SG_ 1046 section_mask "NODE_CMD bytes 4-5 are used as section mask in current ECU firmware, not position offset.";
CM_ SG_ 1158 status_flags "bit0=ready, bit1=enabled, bit2=running, bit3=sync_locked, bit4=warning_active, bit5=fault_active, bit6=position_valid, bit7=can_timeout";
CM_ SG_ 1222 fault_flags "bit0=overcurrent, bit1=undervoltage, bit2=overvoltage, bit3=overtemperature, bit4=encoder_fault, bit5=hall_fault, bit6=motor_stall, bit7=driver_fault";
CM_ SG_ 1222 warning_flags "bit0=rpm_deviation, bit1=sync_deviation, bit2=temp_high, bit3=current_high, bit4=communication_late";
CM_ SG_ 1047 node_flags "bit0=allow_run, bit1=invert_dir, bit2=use_local_sensor";
CM_ SG_ 1047 section_mask "NODE_CMD bytes 4-5 are used as section mask in current ECU firmware, not position offset.";
CM_ SG_ 1159 status_flags "bit0=ready, bit1=enabled, bit2=running, bit3=sync_locked, bit4=warning_active, bit5=fault_active, bit6=position_valid, bit7=can_timeout";
CM_ SG_ 1223 fault_flags "bit0=overcurrent, bit1=undervoltage, bit2=overvoltage, bit3=overtemperature, bit4=encoder_fault, bit5=hall_fault, bit6=motor_stall, bit7=driver_fault";
CM_ SG_ 1223 warning_flags "bit0=rpm_deviation, bit1=sync_deviation, bit2=temp_high, bit3=current_high, bit4=communication_late";
CM_ SG_ 1048 node_flags "bit0=allow_run, bit1=invert_dir, bit2=use_local_sensor";
CM_ SG_ 1048 section_mask "NODE_CMD bytes 4-5 are used as section mask in current ECU firmware, not position offset.";
CM_ SG_ 1160 status_flags "bit0=ready, bit1=enabled, bit2=running, bit3=sync_locked, bit4=warning_active, bit5=fault_active, bit6=position_valid, bit7=can_timeout";
CM_ SG_ 1224 fault_flags "bit0=overcurrent, bit1=undervoltage, bit2=overvoltage, bit3=overtemperature, bit4=encoder_fault, bit5=hall_fault, bit6=motor_stall, bit7=driver_fault";
CM_ SG_ 1224 warning_flags "bit0=rpm_deviation, bit1=sync_deviation, bit2=temp_high, bit3=current_high, bit4=communication_late";
CM_ SG_ 1049 node_flags "bit0=allow_run, bit1=invert_dir, bit2=use_local_sensor";
CM_ SG_ 1049 section_mask "NODE_CMD bytes 4-5 are used as section mask in current ECU firmware, not position offset.";
CM_ SG_ 1161 status_flags "bit0=ready, bit1=enabled, bit2=running, bit3=sync_locked, bit4=warning_active, bit5=fault_active, bit6=position_valid, bit7=can_timeout";
CM_ SG_ 1225 fault_flags "bit0=overcurrent, bit1=undervoltage, bit2=overvoltage, bit3=overtemperature, bit4=encoder_fault, bit5=hall_fault, bit6=motor_stall, bit7=driver_fault";
CM_ SG_ 1225 warning_flags "bit0=rpm_deviation, bit1=sync_deviation, bit2=temp_high, bit3=current_high, bit4=communication_late";
CM_ SG_ 1050 node_flags "bit0=allow_run, bit1=invert_dir, bit2=use_local_sensor";
CM_ SG_ 1050 section_mask "NODE_CMD bytes 4-5 are used as section mask in current ECU firmware, not position offset.";
CM_ SG_ 1162 status_flags "bit0=ready, bit1=enabled, bit2=running, bit3=sync_locked, bit4=warning_active, bit5=fault_active, bit6=position_valid, bit7=can_timeout";
CM_ SG_ 1226 fault_flags "bit0=overcurrent, bit1=undervoltage, bit2=overvoltage, bit3=overtemperature, bit4=encoder_fault, bit5=hall_fault, bit6=motor_stall, bit7=driver_fault";
CM_ SG_ 1226 warning_flags "bit0=rpm_deviation, bit1=sync_deviation, bit2=temp_high, bit3=current_high, bit4=communication_late";
CM_ SG_ 1051 node_flags "bit0=allow_run, bit1=invert_dir, bit2=use_local_sensor";
CM_ SG_ 1051 section_mask "NODE_CMD bytes 4-5 are used as section mask in current ECU firmware, not position offset.";
CM_ SG_ 1163 status_flags "bit0=ready, bit1=enabled, bit2=running, bit3=sync_locked, bit4=warning_active, bit5=fault_active, bit6=position_valid, bit7=can_timeout";
CM_ SG_ 1227 fault_flags "bit0=overcurrent, bit1=undervoltage, bit2=overvoltage, bit3=overtemperature, bit4=encoder_fault, bit5=hall_fault, bit6=motor_stall, bit7=driver_fault";
CM_ SG_ 1227 warning_flags "bit0=rpm_deviation, bit1=sync_deviation, bit2=temp_high, bit3=current_high, bit4=communication_late";
CM_ SG_ 1052 node_flags "bit0=allow_run, bit1=invert_dir, bit2=use_local_sensor";
CM_ SG_ 1052 section_mask "NODE_CMD bytes 4-5 are used as section mask in current ECU firmware, not position offset.";
CM_ SG_ 1164 status_flags "bit0=ready, bit1=enabled, bit2=running, bit3=sync_locked, bit4=warning_active, bit5=fault_active, bit6=position_valid, bit7=can_timeout";
CM_ SG_ 1228 fault_flags "bit0=overcurrent, bit1=undervoltage, bit2=overvoltage, bit3=overtemperature, bit4=encoder_fault, bit5=hall_fault, bit6=motor_stall, bit7=driver_fault";
CM_ SG_ 1228 warning_flags "bit0=rpm_deviation, bit1=sync_deviation, bit2=temp_high, bit3=current_high, bit4=communication_late";
CM_ SG_ 1053 node_flags "bit0=allow_run, bit1=invert_dir, bit2=use_local_sensor";
CM_ SG_ 1053 section_mask "NODE_CMD bytes 4-5 are used as section mask in current ECU firmware, not position offset.";
CM_ SG_ 1165 status_flags "bit0=ready, bit1=enabled, bit2=running, bit3=sync_locked, bit4=warning_active, bit5=fault_active, bit6=position_valid, bit7=can_timeout";
CM_ SG_ 1229 fault_flags "bit0=overcurrent, bit1=undervoltage, bit2=overvoltage, bit3=overtemperature, bit4=encoder_fault, bit5=hall_fault, bit6=motor_stall, bit7=driver_fault";
CM_ SG_ 1229 warning_flags "bit0=rpm_deviation, bit1=sync_deviation, bit2=temp_high, bit3=current_high, bit4=communication_late";
CM_ SG_ 1054 node_flags "bit0=allow_run, bit1=invert_dir, bit2=use_local_sensor";
CM_ SG_ 1054 section_mask "NODE_CMD bytes 4-5 are used as section mask in current ECU firmware, not position offset.";
CM_ SG_ 1166 status_flags "bit0=ready, bit1=enabled, bit2=running, bit3=sync_locked, bit4=warning_active, bit5=fault_active, bit6=position_valid, bit7=can_timeout";
CM_ SG_ 1230 fault_flags "bit0=overcurrent, bit1=undervoltage, bit2=overvoltage, bit3=overtemperature, bit4=encoder_fault, bit5=hall_fault, bit6=motor_stall, bit7=driver_fault";
CM_ SG_ 1230 warning_flags "bit0=rpm_deviation, bit1=sync_deviation, bit2=temp_high, bit3=current_high, bit4=communication_late";
CM_ SG_ 1055 node_flags "bit0=allow_run, bit1=invert_dir, bit2=use_local_sensor";
CM_ SG_ 1055 section_mask "NODE_CMD bytes 4-5 are used as section mask in current ECU firmware, not position offset.";
CM_ SG_ 1167 status_flags "bit0=ready, bit1=enabled, bit2=running, bit3=sync_locked, bit4=warning_active, bit5=fault_active, bit6=position_valid, bit7=can_timeout";
CM_ SG_ 1231 fault_flags "bit0=overcurrent, bit1=undervoltage, bit2=overvoltage, bit3=overtemperature, bit4=encoder_fault, bit5=hall_fault, bit6=motor_stall, bit7=driver_fault";
CM_ SG_ 1231 warning_flags "bit0=rpm_deviation, bit1=sync_deviation, bit2=temp_high, bit3=current_high, bit4=communication_late";
CM_ SG_ 1056 node_flags "bit0=allow_run, bit1=invert_dir, bit2=use_local_sensor";
CM_ SG_ 1056 section_mask "NODE_CMD bytes 4-5 are used as section mask in current ECU firmware, not position offset.";
CM_ SG_ 1168 status_flags "bit0=ready, bit1=enabled, bit2=running, bit3=sync_locked, bit4=warning_active, bit5=fault_active, bit6=position_valid, bit7=can_timeout";
CM_ SG_ 1232 fault_flags "bit0=overcurrent, bit1=undervoltage, bit2=overvoltage, bit3=overtemperature, bit4=encoder_fault, bit5=hall_fault, bit6=motor_stall, bit7=driver_fault";
CM_ SG_ 1232 warning_flags "bit0=rpm_deviation, bit1=sync_deviation, bit2=temp_high, bit3=current_high, bit4=communication_late";

BA_DEF_ BO_  "GenMsgCycleTime" INT 0 65535;
BA_DEF_DEF_  "GenMsgCycleTime" 0;
BA_ "GenMsgCycleTime" BO_ 972 100;
BA_ "GenMsgCycleTime" BO_ 797 50;
BA_ "GenMsgCycleTime" BO_ 845 1000;
BA_ "GenMsgCycleTime" BO_ 909 20;
BA_ "GenMsgCycleTime" BO_ 973 100;
BA_ "GenMsgCycleTime" BO_ 798 50;
BA_ "GenMsgCycleTime" BO_ 846 1000;
BA_ "GenMsgCycleTime" BO_ 910 20;
BA_ "GenMsgCycleTime" BO_ 974 100;
BA_ "GenMsgCycleTime" BO_ 799 50;
BA_ "GenMsgCycleTime" BO_ 847 1000;
BA_ "GenMsgCycleTime" BO_ 911 20;
BA_ "GenMsgCycleTime" BO_ 975 100;
BA_ "GenMsgCycleTime" BO_ 800 50;
BA_ "GenMsgCycleTime" BO_ 848 1000;
BA_ "GenMsgCycleTime" BO_ 912 20;
BA_ "GenMsgCycleTime" BO_ 976 100;
BA_ "GenMsgCycleTime" BO_ 1024 20;
BA_ "GenMsgCycleTime" BO_ 1025 100;
BA_ "GenMsgCycleTime" BO_ 1041 50;
BA_ "GenMsgCycleTime" BO_ 1089 1000;
BA_ "GenMsgCycleTime" BO_ 1153 20;
BA_ "GenMsgCycleTime" BO_ 1217 100;
BA_ "GenMsgCycleTime" BO_ 1042 50;
BA_ "GenMsgCycleTime" BO_ 1090 1000;
BA_ "GenMsgCycleTime" BO_ 1154 20;
BA_ "GenMsgCycleTime" BO_ 1218 100;
BA_ "GenMsgCycleTime" BO_ 1043 50;
BA_ "GenMsgCycleTime" BO_ 1091 1000;
BA_ "GenMsgCycleTime" BO_ 1155 20;
BA_ "GenMsgCycleTime" BO_ 1219 100;
BA_ "GenMsgCycleTime" BO_ 1044 50;
BA_ "GenMsgCycleTime" BO_ 1092 1000;
BA_ "GenMsgCycleTime" BO_ 1156 20;
BA_ "GenMsgCycleTime" BO_ 1220 100;
BA_ "GenMsgCycleTime" BO_ 1045 50;
BA_ "GenMsgCycleTime" BO_ 1093 1000;
BA_ "GenMsgCycleTime" BO_ 1157 20;
BA_ "GenMsgCycleTime" BO_ 1221 100;
BA_ "GenMsgCycleTime" BO_ 1046 50;
BA_ "GenMsgCycleTime" BO_ 1094 1000;
BA_ "GenMsgCycleTime" BO_ 1158 20;
BA_ "GenMsgCycleTime" BO_ 1222 100;
BA_ "GenMsgCycleTime" BO_ 1047 50;
BA_ "GenMsgCycleTime" BO_ 1095 1000;
BA_ "GenMsgCycleTime" BO_ 1159 20;
BA_ "GenMsgCycleTime" BO_ 1223 100;
BA_ "GenMsgCycleTime" BO_ 1048 50;
BA_ "GenMsgCycleTime" BO_ 1096 1000;
BA_ "GenMsgCycleTime" BO_ 1160 20;
BA_ "GenMsgCycleTime" BO_ 1224 100;
BA_ "GenMsgCycleTime" BO_ 1049 50;
BA_ "GenMsgCycleTime" BO_ 1097 1000;
BA_ "GenMsgCycleTime" BO_ 1161 20;
BA_ "GenMsgCycleTime" BO_ 1225 100;
BA_ "GenMsgCycleTime" BO_ 1050 50;
BA_ "GenMsgCycleTime" BO_ 1098 1000;
BA_ "GenMsgCycleTime" BO_ 1162 20;
BA_ "GenMsgCycleTime" BO_ 1226 100;
BA_ "GenMsgCycleTime" BO_ 1051 50;
BA_ "GenMsgCycleTime" BO_ 1099 1000;
BA_ "GenMsgCycleTime" BO_ 1163 20;
BA_ "GenMsgCycleTime" BO_ 1227 100;
BA_ "GenMsgCycleTime" BO_ 1052 50;
BA_ "GenMsgCycleTime" BO_ 1100 1000;
BA_ "GenMsgCycleTime" BO_ 1164 20;
BA_ "GenMsgCycleTime" BO_ 1228 100;
BA_ "GenMsgCycleTime" BO_ 1053 50;
BA_ "GenMsgCycleTime" BO_ 1101 1000;
BA_ "GenMsgCycleTime" BO_ 1165 20;
BA_ "GenMsgCycleTime" BO_ 1229 100;
BA_ "GenMsgCycleTime" BO_ 1054 50;
BA_ "GenMsgCycleTime" BO_ 1102 1000;
BA_ "GenMsgCycleTime" BO_ 1166 20;
BA_ "GenMsgCycleTime" BO_ 1230 100;
BA_ "GenMsgCycleTime" BO_ 1055 50;
BA_ "GenMsgCycleTime" BO_ 1103 1000;
BA_ "GenMsgCycleTime" BO_ 1167 20;
BA_ "GenMsgCycleTime" BO_ 1231 100;
BA_ "GenMsgCycleTime" BO_ 1056 50;
BA_ "GenMsgCycleTime" BO_ 1104 1000;
BA_ "GenMsgCycleTime" BO_ 1168 20;
BA_ "GenMsgCycleTime" BO_ 1232 100;
VAL_ 797 node_command 0 "NOP" 1 "ENABLE" 2 "DISABLE" 3 "ZERO_POS" 4 "CLEAR_FAULT";
VAL_ 798 node_command 0 "NOP" 1 "ENABLE" 2 "DISABLE" 3 "ZERO_POS" 4 "CLEAR_FAULT";
VAL_ 799 node_command 0 "NOP" 1 "ENABLE" 2 "DISABLE" 3 "ZERO_POS" 4 "CLEAR_FAULT";
VAL_ 800 node_command 0 "NOP" 1 "ENABLE" 2 "DISABLE" 3 "ZERO_POS" 4 "CLEAR_FAULT";
VAL_ 1024 system_mode 0 "OFF" 1 "MANUAL" 2 "AUTO" 3 "CALIBRATION" 4 "FAULT_HOLD";
VAL_ 1026 estop_cmd 165 "EMERGENCY_STOP";
VAL_ 1026 reason 0 "manual" 1 "comm_fault" 2 "master_fault";
VAL_ 1041 node_command 0 "NOP" 1 "ENABLE" 2 "DISABLE" 3 "ZERO_POS" 4 "CLEAR_FAULT";
VAL_ 1042 node_command 0 "NOP" 1 "ENABLE" 2 "DISABLE" 3 "ZERO_POS" 4 "CLEAR_FAULT";
VAL_ 1043 node_command 0 "NOP" 1 "ENABLE" 2 "DISABLE" 3 "ZERO_POS" 4 "CLEAR_FAULT";
VAL_ 1044 node_command 0 "NOP" 1 "ENABLE" 2 "DISABLE" 3 "ZERO_POS" 4 "CLEAR_FAULT";
VAL_ 1045 node_command 0 "NOP" 1 "ENABLE" 2 "DISABLE" 3 "ZERO_POS" 4 "CLEAR_FAULT";
VAL_ 1046 node_command 0 "NOP" 1 "ENABLE" 2 "DISABLE" 3 "ZERO_POS" 4 "CLEAR_FAULT";
VAL_ 1047 node_command 0 "NOP" 1 "ENABLE" 2 "DISABLE" 3 "ZERO_POS" 4 "CLEAR_FAULT";
VAL_ 1048 node_command 0 "NOP" 1 "ENABLE" 2 "DISABLE" 3 "ZERO_POS" 4 "CLEAR_FAULT";
VAL_ 1049 node_command 0 "NOP" 1 "ENABLE" 2 "DISABLE" 3 "ZERO_POS" 4 "CLEAR_FAULT";
VAL_ 1050 node_command 0 "NOP" 1 "ENABLE" 2 "DISABLE" 3 "ZERO_POS" 4 "CLEAR_FAULT";
VAL_ 1051 node_command 0 "NOP" 1 "ENABLE" 2 "DISABLE" 3 "ZERO_POS" 4 "CLEAR_FAULT";
VAL_ 1052 node_command 0 "NOP" 1 "ENABLE" 2 "DISABLE" 3 "ZERO_POS" 4 "CLEAR_FAULT";
VAL_ 1053 node_command 0 "NOP" 1 "ENABLE" 2 "DISABLE" 3 "ZERO_POS" 4 "CLEAR_FAULT";
VAL_ 1054 node_command 0 "NOP" 1 "ENABLE" 2 "DISABLE" 3 "ZERO_POS" 4 "CLEAR_FAULT";
VAL_ 1055 node_command 0 "NOP" 1 "ENABLE" 2 "DISABLE" 3 "ZERO_POS" 4 "CLEAR_FAULT";
VAL_ 1056 node_command 0 "NOP" 1 "ENABLE" 2 "DISABLE" 3 "ZERO_POS" 4 "CLEAR_FAULT";
VAL_ 1285 result 0 "OK" 1 "unknown_command" 2 "bad_payload" 3 "wrong_uid" 4 "busy" 5 "save_failed" 6 "not_supported";
VAL_ 1286 mode 0 "RUN" 1 "COAST" 2 "BRAKE";
VAL_ 1291 mode 0 "LED_BLINK" 1 "SHORT_JOG";
